VERSION "HNNBNNNYNNNNNNNNNNNNNNNNNNNNNNNNNNNNNNNNNN/4/%%%/4/'%**4NNN///"

NS_ :

BS_:

BU_: AAG BCM1 BCM2 ELV Gateway HDSG IEZS MFG MSBBR SAD SAD2 Schwerpanzer_Zusatz SitzMem_BFS SitzMem_FS SitzMem_HBFS SitzMem_HFS SitzMem_SR3 SpoilerSG TSG_BFS TSG_FS VSG VTS DK_Dummy

BO_ 262 ESP_05: 8 Gateway
 SG_ ESP_05_CRC : 0|8@1+ (1,0) [0|255] ""  BCM2
 SG_ ESP_05_BZ : 8|4@1+ (1,0) [0|15] ""  BCM2
 SG_ ESP_QBit_Bremsdruck : 12|1@1+ (1,0) [0|1] "" Vector__XXX
 SG_ ESP_QBit_Fahrer_bremst : 13|1@1+ (1,0) [0|1] "" Vector__XXX
 SG_ ESP_Schwelle_Unterdruck : 14|2@1+ (1,0) [0|3] "" Vector__XXX
 SG_ ESP_Bremsdruck : 16|10@1+ (0.3,-30) [-30|276.6] "Unit_Bar" Vector__XXX
 SG_ ESP_Fahrer_bremst : 26|1@1+ (1,0) [0|1] "" Vector__XXX
 SG_ ESP_Lenkeingriff_ADS : 28|1@1+ (1,0) [0|1] "" Vector__XXX
 SG_ ECD_Fehler : 32|1@1+ (1,0) [0|1] "" Vector__XXX
 SG_ ECD_nicht_verfuegbar : 33|1@1+ (1,0) [0|1] "" Vector__XXX
 SG_ ESP_Status_Bremsentemp : 34|1@1+ (1,0) [0|1] "" Vector__XXX
 SG_ ESP_Autohold_Standby : 35|1@1+ (1,0) [0|1] "" Vector__XXX
 SG_ ESP_HDC_Standby : 36|1@1+ (1,0) [0|1] "" Vector__XXX
 SG_ ESP_HBA_aktiv : 37|1@1+ (1,0) [0|1] "" Vector__XXX
 SG_ ESP_Prefill_ausgeloest : 38|1@1+ (1,0) [0|1] "" Vector__XXX
 SG_ ESP_Rueckwaertsfahrt_erkannt : 39|1@1+ (1,0) [0|1] "" Vector__XXX
 SG_ ESP_Status_Anfahrhilfe : 40|1@1+ (1,0) [0|1] "" Vector__XXX
 SG_ ESP_HDC_aktiv : 41|1@1+ (1,0) [0|1] "" Vector__XXX
 SG_ ESP_StartStopp_Info : 42|2@1+ (1,0) [0|3] "" Vector__XXX
 SG_ ESP_Eingr_HL : 44|1@1+ (1,0) [0|1] "" Vector__XXX
 SG_ ESP_Eingr_HR : 45|1@1+ (1,0) [0|1] "" Vector__XXX
 SG_ ESP_Eingr_VL : 46|1@1+ (1,0) [0|1] "" Vector__XXX
 SG_ ESP_Eingr_VR : 47|1@1+ (1,0) [0|1] "" Vector__XXX
 SG_ ESP_BKV_Unterdruck : 48|8@1+ (4,0) [4|1012] "Unit_MilliBar" Vector__XXX
 SG_ ESP_Autohold_aktiv : 56|1@1+ (1,0) [0|1] "" Vector__XXX
 SG_ ESP_FStatus_Anfahrhilfe : 57|1@1+ (1,0) [0|1] "" Vector__XXX
 SG_ ESP_Verz_EPB_aktiv : 58|1@1+ (1,0) [0|1] "" Vector__XXX
 SG_ ESC_Bremslicht : 59|1@1+ (1,0) [0|1] ""  AAG,BCM2,MSBBR
 SG_ ESP_Verzoeg_EPB_verf : 60|1@1+ (1,0) [0|1] "" Vector__XXX
 SG_ ESP_Status_Bremsdruck : 61|1@1+ (1,0) [0|1] "" Vector__XXX
 SG_ ESP_Anforderung_EPB : 62|2@1+ (1,0) [0|3] "" Vector__XXX

BO_ 914 ESP_07: 8 Gateway
 SG_ ESP_07_CRC : 0|8@1+ (1,0) [0|255] "" Vector__XXX
 SG_ ESP_07_BZ : 8|4@1+ (1,0) [0|15] "" Vector__XXX
 SG_ ESP_ACC_LDE : 12|1@1+ (1,0) [0|1] "" Vector__XXX
 SG_ ESP_Allrad_Antrieb : 13|1@1+ (1,0) [0|1] "" Vector__XXX
 SG_ ESP_Codierung_ADS : 14|2@1+ (1,0) [0|3] ""  BCM1
 SG_ ESP_RTA_HL : 16|8@1+ (0.048828125,-6.20117) [-6.20117|6.152345625] "Unit_PerCent" Vector__XXX
 SG_ ESP_RTA_HR : 24|8@1+ (0.048828125,-6.20117) [-6.20117|6.152345625] "Unit_PerCent" Vector__XXX
 SG_ ESP_RTA_VR : 32|8@1+ (0.048828125,-6.20117) [-6.20117|6.152345625] "Unit_PerCent" Vector__XXX
 SG_ OBD_Fehler_Radsensor_HL : 40|4@1+ (1,0) [0|15] "" Vector__XXX
 SG_ OBD_Fehler_Radsensor_HR : 44|4@1+ (1,0) [0|15] "" Vector__XXX
 SG_ OBD_Fehler_Radsensor_VL : 48|4@1+ (1,0) [0|15] "" Vector__XXX
 SG_ OBD_Fehler_Radsensor_VR : 52|4@1+ (1,0) [0|15] "" Vector__XXX
 SG_ ESP_Qualifizierung_Antriebsart : 56|1@1+ (1,0) [0|1] "" Vector__XXX
 SG_ ESP_Offroad_Modus : 57|1@1+ (1,0) [0|1] "" Vector__XXX
 SG_ ESP_MKB_ausloesbar : 58|1@1+ (1,0) [0|1] "" Vector__XXX
 SG_ ESP_Stat_FallBack_eBKV : 59|1@1+ (1,0) [0|1] "" Vector__XXX
 SG_ ESP_CM_Variante : 60|1@1+ (1,0) [0|1] "" Vector__XXX
 SG_ ESP_OBD_Status : 61|1@1+ (1,0) [0|1] "" Vector__XXX
 SG_ ESP_Rollenmodus_Deaktivieren : 62|1@1+ (1,0) [0|1] ""  BCM2
 SG_ ESP_nachtr_Stopp_Anf : 63|1@1+ (1,0) [0|1] "" Vector__XXX

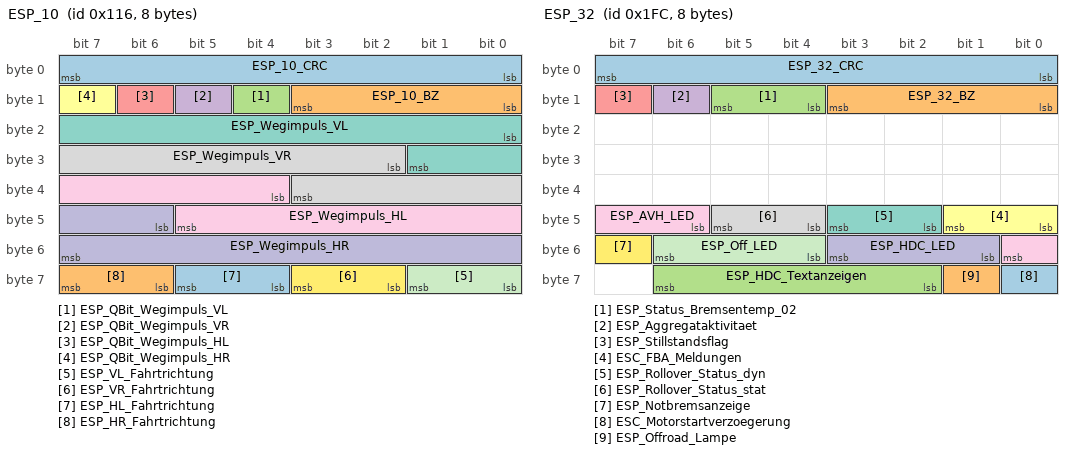
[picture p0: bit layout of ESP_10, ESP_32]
BO_ 278 ESP_10: 8 Gateway
 SG_ ESP_10_CRC : 0|8@1+ (1,0) [0|255] ""  BCM1,ELV
 SG_ ESP_10_BZ : 8|4@1+ (1,0) [0|15] ""  BCM1,ELV
 SG_ ESP_QBit_Wegimpuls_VL : 12|1@1+ (1,0) [0|1] ""  BCM1,ELV
 SG_ ESP_QBit_Wegimpuls_VR : 13|1@1+ (1,0) [0|1] ""  BCM1,ELV
 SG_ ESP_QBit_Wegimpuls_HL : 14|1@1+ (1,0) [0|1] ""  BCM1,ELV
 SG_ ESP_QBit_Wegimpuls_HR : 15|1@1+ (1,0) [0|1] ""  BCM1,ELV
 SG_ ESP_Wegimpuls_VL : 16|10@1+ (1,0) [0|1000] ""  BCM1,ELV
 SG_ ESP_Wegimpuls_VR : 26|10@1+ (1,0) [0|1000] ""  BCM1,ELV
 SG_ ESP_Wegimpuls_HL : 36|10@1+ (1,0) [0|1000] ""  BCM1,ELV
 SG_ ESP_Wegimpuls_HR : 46|10@1+ (1,0) [0|1000] ""  BCM1,ELV
 SG_ ESP_VL_Fahrtrichtung : 56|2@1+ (1,0) [0|3] ""  BCM1
 SG_ ESP_VR_Fahrtrichtung : 58|2@1+ (1,0) [0|3] ""  BCM1
 SG_ ESP_HL_Fahrtrichtung : 60|2@1+ (1,0) [0|3] ""  BCM1
 SG_ ESP_HR_Fahrtrichtung : 62|2@1+ (1,0) [0|3] ""  BCM1

BO_ 418 ESP_15: 8 Gateway
 SG_ ESP_15_CRC : 0|8@1+ (1,0) [0|255] "" Vector__XXX
 SG_ ESP_15_BZ : 8|4@1+ (1,0) [0|15] "" Vector__XXX
 SG_ HMS_P_beibehalten_GE : 12|2@1+ (1,0) [0|3] "" Vector__XXX
 SG_ HMS_Konsistenz_GE : 14|1@1+ (1,0) [0|1] "" Vector__XXX
 SG_ HMS_Konsistenz_IPA : 15|1@1+ (1,0) [0|1] "" Vector__XXX
 SG_ HMS_Konsistenz_EBKV : 16|1@1+ (1,0) [0|1] "" Vector__XXX
 SG_ HMS_Konsistenz_RCTA : 17|1@1+ (1,0) [0|1] "" Vector__XXX
 SG_ HMS_Konsistenz_STA : 18|1@1+ (1,0) [0|1] "" Vector__XXX
 SG_ HMS_Konsistenz_MO : 19|1@1+ (1,0) [0|1] "" Vector__XXX
 SG_ HMS_halten_nicht_verfuegbar : 20|1@1+ (1,0) [0|1] "" Vector__XXX
 SG_ HMS_parken_nicht_verfuegbar : 32|1@1+ (1,0) [0|1] "" Vector__XXX
 SG_ HMS_Anforderung_GE : 33|3@1+ (1,0) [0|7] "" Vector__XXX
 SG_ HMS_Systemstatus : 36|4@1+ (1,0) [0|15] ""  BCM1
 SG_ HMS_Stillstand : 40|3@1+ (1,0) [0|7] ""  BCM1
 SG_ HMS_aktives_System : 43|5@1+ (1,0) [0|31] ""  BCM1
 SG_ HMS_Konsistenz_HVLM : 48|1@1+ (1,0) [0|1] "" Vector__XXX
 SG_ HMS_Konsistenz_ACC : 49|1@1+ (1,0) [0|1] "" Vector__XXX
 SG_ HMS_Fehlerstatus : 50|3@1+ (1,0) [0|7] "" Vector__XXX
 SG_ ESP_Index_Haltemoment : 53|1@1+ (1,0) [0|1] "" Vector__XXX
 SG_ ESP_Haltemoment : 54|10@1+ (10,0) [0|10210] "Unit_NewtoMeter" Vector__XXX

BO_ 1629 ESP_20: 8 Gateway
 SG_ ESP_20_CRC : 0|8@1+ (1,0) [0|255] "" Vector__XXX
 SG_ ESP_20_BZ : 8|4@1+ (1,0) [0|15] "" Vector__XXX
 SG_ BR_Systemart : 12|2@1+ (1,0) [0|3] "" Vector__XXX
 SG_ ESP_SpannungsAnf_02 : 14|2@1+ (1,0) [0|3] "" Vector__XXX
 SG_ ESP_Zaehnezahl : 16|8@1+ (1,0) [0|255] ""  BCM2
 SG_ ESP_Charisma_FahrPr : 24|4@1+ (1,0) [0|15] "" Vector__XXX
 SG_ ESP_Charisma_Status : 28|2@1+ (1,0) [0|3] "" Vector__XXX
 SG_ ESP_Wiederstart_Anz_01 : 30|1@1+ (1,0) [0|1] "" Vector__XXX
 SG_ ESP_Wiederstart_Anz_02 : 31|1@1+ (1,0) [0|1] "" Vector__XXX
 SG_ ESP_Wiederstart_Anz_03 : 32|1@1+ (1,0) [0|1] "" Vector__XXX
 SG_ ESP_Wiederstart_Anz_04 : 33|1@1+ (1,0) [0|1] "" Vector__XXX
 SG_ ESP_Stoppverbot_Anz_01 : 34|1@1+ (1,0) [0|1] "" Vector__XXX
 SG_ ESP_Stoppverbot_Anz_02 : 35|1@1+ (1,0) [0|1] "" Vector__XXX
 SG_ ESP_Stoppverbot_Anz_03 : 36|1@1+ (1,0) [0|1] "" Vector__XXX
 SG_ ESP_Stoppverbot_Anz_04 : 37|1@1+ (1,0) [0|1] "" Vector__XXX
 SG_ ESP_Stoppverbot_Anz_05 : 38|1@1+ (1,0) [0|1] "" Vector__XXX
 SG_ ESP_Stoppverbot_Anz_06 : 39|1@1+ (1,0) [0|1] "" Vector__XXX
 SG_ ESP_Stoppverbot_Anz_07 : 40|1@1+ (1,0) [0|1] "" Vector__XXX
 SG_ ESP_Stoppverbot_Anz_Std : 41|1@1+ (1,0) [0|1] "" Vector__XXX
 SG_ ESP_Dachrelingsensor : 42|2@1+ (1,0) [0|3] "" Vector__XXX
 SG_ ESP_Stoppverbot_Anz_08 : 44|1@1+ (1,0) [0|1] "" Vector__XXX
 SG_ HDC_Charisma_FahrPr : 45|4@1+ (1,0) [0|15] "" Vector__XXX
 SG_ HDC_Charisma_Status : 49|2@1+ (1,0) [0|3] "" Vector__XXX
 SG_ BR_QBit_Reifenumfang : 51|1@1+ (1,0) [0|1] "" Vector__XXX
 SG_ BR_Reifenumfang : 52|12@1+ (1,0) [0|4095] "Unit_MilliMeter" Vector__XXX

BO_ 253 ESP_21: 8 Gateway
 SG_ ESP_21_CRC : 0|8@1+ (1,0) [0|255] ""  AAG,BCM1,BCM2,ELV,IEZS,MSBBR,SitzMem_BFS,SitzMem_FS,SitzMem_HBFS,SitzMem_HFS,SitzMem_SR3,SpoilerSG
 SG_ ESP_21_BZ : 8|4@1+ (1,0) [0|15] ""  AAG,BCM1,BCM2,ELV,IEZS,MSBBR,SitzMem_BFS,SitzMem_FS,SitzMem_HBFS,SitzMem_HFS,SitzMem_SR3,SpoilerSG
 SG_ BR_Eingriffsmoment : 12|10@1+ (1,-509) [-509|509] ""  BCM1
 SG_ ESP_PLA_Bremseingriff : 22|1@1+ (1,0) [0|1] ""  BCM1
 SG_ ESP_Diagnose : 23|1@1+ (1,0) [0|1] "" Vector__XXX
 SG_ ESC_v_Signal_Qualifier_High_Low : 24|3@1+ (1,0) [0|7] ""  IEZS,SpoilerSG
 SG_ ESP_Vorsteuerung : 28|1@1+ (1,0) [0|1] ""  BCM1
 SG_ OBD_Schlechtweg : 30|1@1+ (1,0) [0|1] "" Vector__XXX
 SG_ OBD_QBit_Schlechtweg : 31|1@1+ (1,0) [0|1] "" Vector__XXX
 SG_ ESP_v_Signal : 32|16@1+ (0.01,0) [0|655.32] "Unit_KiloMeterPerHour"  AAG,BCM1,BCM2,ELV,HDSG,MFG,MSBBR,SAD,SAD2,SitzMem_BFS,SitzMem_FS,SitzMem_HBFS,SitzMem_HFS,SitzMem_SR3,SpoilerSG,TSG_BFS,TSG_FS,VSG,VTS
 SG_ ASR_Tastung_passiv : 48|1@1+ (1,0) [0|1] ""  BCM1
 SG_ ESP_Tastung_passiv : 49|1@1+ (1,0) [0|1] ""  BCM1
 SG_ ESP_Systemstatus : 50|1@1+ (1,0) [0|1] ""  BCM1
 SG_ ASR_Schalteingriff : 51|2@1+ (1,0) [0|3] ""  BCM1
 SG_ ESP_Haltebestaetigung : 53|1@1+ (1,0) [0|1] ""  BCM1
 SG_ ESP_MKB_Abbruch_Geschw : 54|1@1+ (1,0) [0|1] "" Vector__XXX
 SG_ ESP_QBit_v_Signal : 55|1@1+ (1,0) [0|1] ""  BCM1,BCM2,ELV,SitzMem_BFS,SitzMem_FS,SitzMem_SR3,SpoilerSG
 SG_ ABS_Bremsung : 56|1@1+ (1,0) [0|1] ""  BCM1,MSBBR
 SG_ ASR_Anf : 57|1@1+ (1,0) [0|1] ""  BCM1
 SG_ MSR_Anf : 58|1@1+ (1,0) [0|1] ""  BCM1
 SG_ EBV_Eingriff : 59|1@1+ (1,0) [0|1] ""  BCM1
 SG_ EDS_Eingriff : 60|1@1+ (1,0) [0|1] ""  BCM1
 SG_ ESP_Eingriff : 61|1@1+ (1,0) [0|1] ""  BCM1
 SG_ ESP_ASP : 62|1@1+ (1,0) [0|1] ""  BCM1

BO_ 795 ESP_24: 8 Gateway
 SG_ ESP_24_CRC : 0|8@1+ (1,0) [0|255] "" Vector__XXX
 SG_ ESP_24_BZ : 8|4@1+ (1,0) [0|15] "" Vector__XXX
 SG_ ESP_Lampe : 12|1@1+ (1,0) [0|1] "" Vector__XXX
 SG_ ABS_Lampe : 13|1@1+ (1,0) [0|1] "" Vector__XXX
 SG_ BK_Lampe_02 : 14|2@1+ (1,0) [0|3] ""  VTS
 SG_ TC_Lampe : 16|1@1+ (1,0) [0|1] "" Vector__XXX
 SG_ ESP_m_Raddrehz : 17|15@1+ (0.002,0) [0|65.278] "Unit_Hertz" Vector__XXX
 SG_ ESP_Textanzeigen_03 : 32|5@1+ (1,0) [0|31] ""  VTS
 SG_ ESP_Meldungen : 37|3@1+ (1,0) [0|7] "" Vector__XXX
 SG_ ESP_Wegimp_VA : 40|11@1+ (1,0) [0|2047] "" Vector__XXX
 SG_ ESP_Fehlerstatus_Wegimp : 51|1@1+ (1,0) [0|1] "" Vector__XXX
 SG_ ESP_Wegimp_Ueberlauf : 52|1@1+ (1,0) [0|1] "" Vector__XXX
 SG_ ESP_QBit_Wegimp_VA : 53|1@1+ (1,0) [0|1] "" Vector__XXX
 SG_ ESP_HDC_FktLampe : 54|1@1+ (1,0) [0|1] "" Vector__XXX
 SG_ ESP_Off_Lampe : 55|1@1+ (1,0) [0|1] "" Vector__XXX
 SG_ ESP_HDC_Regelgeschw : 56|7@1+ (0.32,0) [0.32|39.68] "Unit_KiloMeterPerHour" Vector__XXX
 SG_ ESP_BKV_Warnung : 63|1@1+ (1,0) [0|1] ""  VTS

BO_ 508 ESP_32: 8 Gateway
 SG_ ESP_32_CRC : 0|8@1+ (1,0) [0|255] "" Vector__XXX
 SG_ ESP_32_BZ : 8|4@1+ (1,0) [0|15] "" Vector__XXX
 SG_ ESP_Status_Bremsentemp_02 : 12|2@1+ (1,0) [0|3] "" Vector__XXX
 SG_ ESP_Aggregataktivitaet : 14|1@1+ (1,0) [0|1] "" Vector__XXX
 SG_ ESP_Stillstandsflag : 15|1@1+ (1,0) [0|1] ""  BCM1,BCM2
 SG_ ESC_FBA_Meldungen : 40|2@1+ (1,0) [0|3] "" Vector__XXX
 SG_ ESP_Rollover_Status_dyn : 42|2@1+ (1,0) [0|3] "" Vector__XXX
 SG_ ESP_Rollover_Status_stat : 44|2@1+ (1,0) [0|3] "" Vector__XXX
 SG_ ESP_AVH_LED : 46|3@1+ (1,0) [0|7] ""  BCM1
 SG_ ESP_HDC_LED : 49|3@1+ (1,0) [0|7] ""  BCM1
 SG_ ESP_Off_LED : 52|3@1+ (1,0) [0|7] ""  BCM1,VTS
 SG_ ESP_Notbremsanzeige : 55|1@1+ (1,0) [0|1] ""  SAD2,BCM2,SAD
 SG_ ESC_Motorstartverzoegerung : 56|1@1+ (1,0) [0|1] "" Vector__XXX
 SG_ ESP_Offroad_Lampe : 57|1@1+ (1,0) [0|1] "" Vector__XXX
 SG_ ESP_HDC_Textanzeigen : 58|5@1+ (1,0) [0|31] "" Vector__XXX

BO_ 427 ESP_33: 8 Gateway
 SG_ ESP_33_CRC : 0|8@1+ (1,0) [0|255] "" Vector__XXX
 SG_ ESP_33_BZ : 8|4@1+ (1,0) [0|15] "" Vector__XXX
 SG_ ESC_AHW_aktiv : 12|3@1+ (1,0) [0|7] ""  BCM1
 SG_ ESC_AHW_nicht_verfuegbar : 15|1@1+ (1,0) [0|1] ""  BCM1
 SG_ ESC_ANB_CM_aktiv : 16|2@1+ (1,0) [0|3] "" Vector__XXX
 SG_ ESC_ANB_CM_nicht_verfuegbar : 18|1@1+ (1,0) [0|1] "" Vector__XXX
 SG_ ESC_Warnruck_aktiv : 19|4@1+ (1,0) [0|15] "" Vector__XXX
 SG_ ESC_Warnruck_nicht_verfuegbar : 23|1@1+ (1,0) [0|1] "" Vector__XXX
 SG_ ESC_Prefill_aktiv : 24|1@1+ (1,0) [0|1] "" Vector__XXX
 SG_ ESC_Prefill_nicht_verfuegbar : 25|1@1+ (1,0) [0|1] "" Vector__XXX
 SG_ ESC_HBA_aktiv : 26|1@1+ (1,0) [0|1] "" Vector__XXX
 SG_ ESC_HBA_nicht_verfuegbar : 27|1@1+ (1,0) [0|1] "" Vector__XXX
 SG_ ESC_TSK_SRBM_Anf : 28|1@1+ (1,0) [0|1] "" Vector__XXX
 SG_ ESC_TSK_SRBM_nicht_verfuegbar : 29|1@1+ (1,0) [0|1] "" Vector__XXX
 SG_ ESC_Verz_Reg_aktiv : 30|4@1+ (1,0) [0|15] ""  BCM1
 SG_ ESC_Verz_Reg_nicht_verfuegbar : 34|1@1+ (1,0) [0|1] ""  BCM1
 SG_ ESC_Verz_Reg_TB_nicht_verfuegbar : 35|1@1+ (1,0) [0|1] "" Vector__XXX
 SG_ ESC_Verz_Reg_ZB_nicht_verfuegbar : 36|1@1+ (1,0) [0|1] ""  BCM1
 SG_ ESC_Bremslicht_unplausibel : 37|1@1+ (1,0) [0|1] "" Vector__XXX
 SG_ ESC_Konsistenz_ACC : 38|1@1+ (1,0) [0|1] "" Vector__XXX
 SG_ ESC_Konsistenz_AWV : 39|1@1+ (1,0) [0|1] "" Vector__XXX
 SG_ ESC_Konsistenz_ARA : 40|1@1+ (1,0) [0|1] ""  BCM1
 SG_ ESC_Konsistenz_IPA : 41|1@1+ (1,0) [0|1] ""  BCM1
 SG_ ESC_Konsistenz_FCW : 42|1@1+ (1,0) [0|1] "" Vector__XXX
 SG_ ESC_Konsistenz_NV : 43|1@1+ (1,0) [0|1] "" Vector__XXX
 SG_ ESC_Konsistenz_RCTA : 44|1@1+ (1,0) [0|1] "" Vector__XXX
 SG_ ESC_Konsistenz_TSK : 45|1@1+ (1,0) [0|1] "" Vector__XXX
 SG_ ESC_Konsistenz_vFGS : 46|1@1+ (1,0) [0|1] "" Vector__XXX
 SG_ ESC_Konsistenz_STA : 47|1@1+ (1,0) [0|1] "" Vector__XXX
 SG_ ESC_Fahrer_Bremsdruck_bestimmend : 48|1@1+ (1,0) [0|1] "" Vector__XXX
 SG_ ESC_Konsistenz_EA : 49|1@1+ (1,0) [0|1] "" Vector__XXX
 SG_ ESC_Konsistenz_BFF : 50|1@1+ (1,0) [0|1] "" Vector__XXX
 SG_ ESC_Konsistenz_MKB : 51|1@1+ (1,0) [0|1] "" Vector__XXX

BO_ 2589283470 ESP_35: 8 Gateway
 SG_ ESC_Kilometer : 0|20@1+ (1,0) [0|1048573] "Unit_KiloMeter"  BCM2
 SG_ ESC_Kilometer_MUX M : 20|1@1+ (1,0) [0|1] ""  BCM2
 SG_ ESC_Signatur_Kilometer_GFA_01 m0 : 23|9@1+ (1,0) [0|511] ""  BCM2
 SG_ ESC_Signatur_Kilometer_IKA_01 m1 : 23|9@1+ (1,0) [0|511] ""  BCM2
 SG_ ESC_Signatur_Kilometer_GFA_02 m0 : 32|32@1+ (1,0) [0|4294967295] ""  BCM2
 SG_ ESC_Signatur_Kilometer_IKA_02 m1 : 32|32@1+ (1,0) [0|4294967295] ""  BCM2

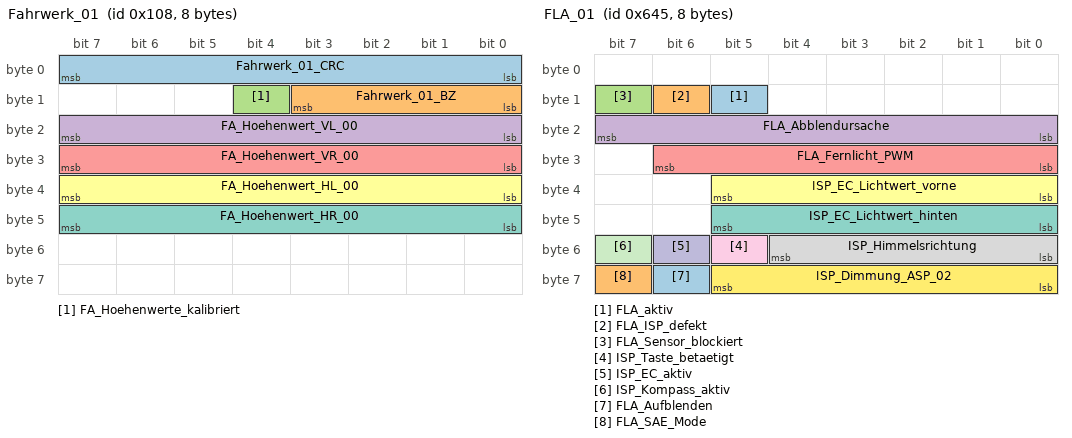
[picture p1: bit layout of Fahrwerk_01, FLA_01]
BO_ 264 Fahrwerk_01: 8 Gateway
 SG_ Fahrwerk_01_CRC : 0|8@1+ (1,0) [0|255] "" Vector__XXX
 SG_ Fahrwerk_01_BZ : 8|4@1+ (1,0) [0|15] "" Vector__XXX
 SG_ FA_Hoehenwerte_kalibriert : 12|1@1+ (1,0) [0|1] ""  BCM1
 SG_ FA_Hoehenwert_VL_00 : 16|8@1+ (1,-127) [-127|126] "Unit_MilliMeter"  BCM1
 SG_ FA_Hoehenwert_VR_00 : 24|8@1+ (1,-127) [-127|126] "Unit_MilliMeter" Vector__XXX
 SG_ FA_Hoehenwert_HL_00 : 32|8@1+ (1,-127) [-127|126] "Unit_MilliMeter"  BCM1
 SG_ FA_Hoehenwert_HR_00 : 40|8@1+ (1,-127) [-127|126] "Unit_MilliMeter" Vector__XXX

BO_ 429 Fahrwerk_06: 8 Gateway
 SG_ Fahrwerk_06_CRC : 0|8@1+ (1,0) [0|255] "" Vector__XXX
 SG_ Fahrwerk_06_BZ : 8|4@1+ (1,0) [0|15] "" Vector__XXX
 SG_ NR_Reglerstatus : 12|4@1+ (1,0) [0|15] ""  BCM1
 SG_ FA_Verstellung_in_Kuerze : 16|1@1+ (1,0) [0|1] "" Vector__XXX
 SG_ FA_Verstellung_aktiv : 17|1@1+ (1,0) [0|1] "" Vector__XXX
 SG_ FA_Kompressor_laeuft_in_Kuerze : 18|1@1+ (1,0) [0|1] "" Vector__XXX
 SG_ FA_Kompressor_laeuft : 19|1@1+ (1,0) [0|1] "" Vector__XXX
 SG_ NR_Anforderung_v_Begrenzung : 20|2@1+ (1,0) [0|3] "" Vector__XXX
 SG_ NR_LED_SGN : 22|1@1+ (1,0) [0|1] ""  BCM1
 SG_ NR_LED_TN : 23|1@1+ (1,0) [0|1] ""  BCM1
 SG_ NR_LED_BN : 24|1@1+ (1,0) [0|1] ""  BCM1
 SG_ FA_Absenkung_Fahrzeug : 25|1@1+ (1,0) [0|1] "" Vector__XXX
 SG_ FA_Anhaengerstatus_intern : 26|3@1+ (1,0) [0|7] "" Vector__XXX
 SG_ FA_Anhebung_Fahrzeug : 29|1@1+ (1,0) [0|1] "" Vector__XXX
 SG_ FA_Druckspeicher_verfuegbar : 30|1@1+ (1,0) [0|1] "" Vector__XXX
 SG_ FA_ESP_Zuschaltung : 32|1@1+ (1,0) [0|1] "" Vector__XXX
 SG_ NR_LED_HN : 33|1@1+ (1,0) [0|1] ""  BCM1
 SG_ FA_Zwischenniveau : 34|1@1+ (1,0) [0|1] "" Vector__XXX
 SG_ FA_Systemstatus : 35|1@1+ (1,0) [0|1] "" Vector__XXX
 SG_ EFP_Soll_FahrPr_HAL : 36|4@1+ (1,0) [0|15] "" Vector__XXX
 SG_ NR_Kompressor_Temp_Zylinderkopf : 48|8@1+ (1,-40) [-40|213] "Unit_DegreCelsi" Vector__XXX
 SG_ FA_Signal_Drucksensor : 56|8@1+ (0.1,0) [0|25.3] "Unit_Bar" Vector__XXX

BO_ 1605 FLA_01: 8 Gateway
 SG_ FLA_aktiv : 13|1@1+ (1,0) [0|1] ""  BCM1
 SG_ FLA_ISP_defekt : 14|1@1+ (1,0) [0|1] ""  BCM1
 SG_ FLA_Sensor_blockiert : 15|1@1+ (1,0) [0|1] ""  BCM1
 SG_ FLA_Abblendursache : 16|8@1+ (1,0) [0|255] "" Vector__XXX
 SG_ FLA_Fernlicht_PWM : 24|7@1+ (1,0) [0|100] "Unit_PerCent"  BCM1
 SG_ ISP_EC_Lichtwert_vorne : 32|6@1+ (1,0) [0|61] "Unit_None" Vector__XXX
 SG_ ISP_EC_Lichtwert_hinten : 40|6@1+ (1,0) [0|61] "Unit_None" Vector__XXX
 SG_ ISP_Himmelsrichtung : 48|5@1+ (12,0) [0|348] "Unit_DegreOfArc" Vector__XXX
 SG_ ISP_Taste_betaetigt : 53|1@1+ (1,0) [0|1] "" Vector__XXX
 SG_ ISP_EC_aktiv : 54|1@1+ (1,0) [0|1] "" Vector__XXX
 SG_ ISP_Kompass_aktiv : 55|1@1+ (1,0) [0|1] "" Vector__XXX
 SG_ ISP_Dimmung_ASP_02 : 56|6@1+ (0.0226,0) [0|1.4012] "Unit_Volt"  TSG_BFS,TSG_FS
 SG_ FLA_Aufblenden : 62|1@1+ (1,0) [0|1] ""  BCM1
 SG_ FLA_SAE_Mode : 63|1@1+ (1,0) [0|1] "" Vector__XXX

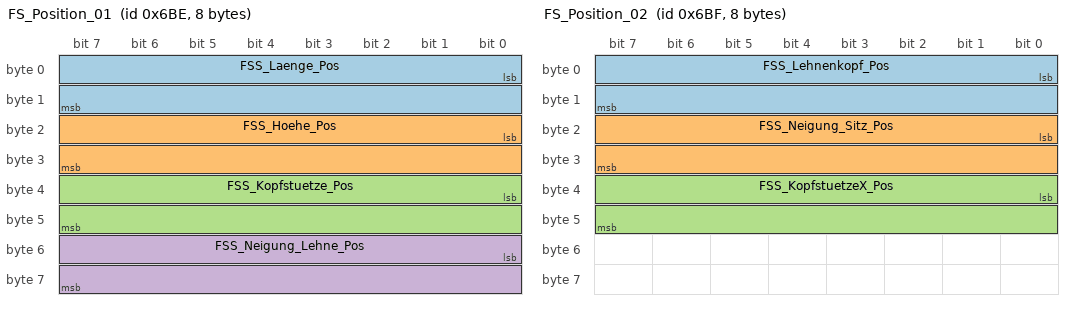
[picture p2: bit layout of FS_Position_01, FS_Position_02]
BO_ 1726 FS_Position_01: 8 SitzMem_FS
 SG_ FSS_Laenge_Pos : 0|16@1+ (1,0) [0|65535] ""  SitzMem_BFS
 SG_ FSS_Hoehe_Pos : 16|16@1+ (1,0) [0|65535] ""  SitzMem_BFS
 SG_ FSS_Kopfstuetze_Pos : 32|16@1+ (1,0) [0|65535] ""  SitzMem_BFS
 SG_ FSS_Neigung_Lehne_Pos : 48|16@1+ (1,0) [0|65535] ""  SitzMem_BFS

BO_ 1727 FS_Position_02: 8 SitzMem_FS
 SG_ FSS_Lehnenkopf_Pos : 0|16@1+ (1,0) [0|65535] ""  SitzMem_BFS
 SG_ FSS_Neigung_Sitz_Pos : 16|16@1+ (1,0) [1|65535] ""  SitzMem_BFS
 SG_ FSS_KopfstuetzeX_Pos : 32|16@1+ (1,0) [1|65535] ""  SitzMem_BFS

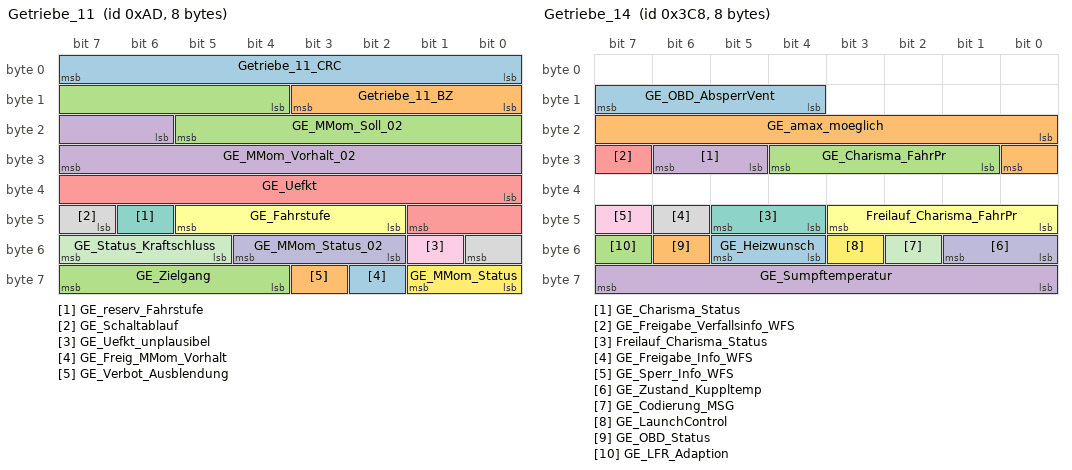
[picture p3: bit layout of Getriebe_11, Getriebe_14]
BO_ 173 Getriebe_11: 8 Gateway
 SG_ Getriebe_11_CRC : 0|8@1+ (1,0) [0|255] "" Vector__XXX
 SG_ Getriebe_11_BZ : 8|4@1+ (1,0) [0|15] "" Vector__XXX
 SG_ GE_MMom_Soll_02 : 12|10@1+ (1,-509) [-509|509] "" Vector__XXX
 SG_ GE_MMom_Vorhalt_02 : 22|10@1+ (1,-509) [-509|509] "" Vector__XXX
 SG_ GE_Uefkt : 32|10@1+ (0.1,0) [0|102.2] "" Vector__XXX
 SG_ GE_Fahrstufe : 42|4@1+ (1,0) [0|15] ""  BCM1,BCM2,ELV,MFG
 SG_ GE_reserv_Fahrstufe : 46|1@1+ (1,0) [0|1] "" Vector__XXX
 SG_ GE_Schaltablauf : 47|2@1+ (1,0) [0|3] "" Vector__XXX
 SG_ GE_Uefkt_unplausibel : 49|1@1+ (1,0) [0|1] "" Vector__XXX
 SG_ GE_MMom_Status_02 : 50|3@1+ (1,0) [0|7] "" Vector__XXX
 SG_ GE_Status_Kraftschluss : 53|3@1+ (1,0) [0|7] "" Vector__XXX
 SG_ GE_MMom_Status : 56|2@1+ (1,0) [0|3] "" Vector__XXX
 SG_ GE_Freig_MMom_Vorhalt : 58|1@1+ (1,0) [0|1] "" Vector__XXX
 SG_ GE_Verbot_Ausblendung : 59|1@1+ (1,0) [0|1] "" Vector__XXX
 SG_ GE_Zielgang : 60|4@1+ (1,0) [0|15] ""  BCM1

BO_ 968 Getriebe_14: 8 Gateway
 SG_ GE_OBD_AbsperrVent : 12|4@1+ (1,0) [0|15] "" Vector__XXX
 SG_ GE_amax_moeglich : 16|9@1+ (0.024,-2.016) [-2.016|10.224] "Unit_MeterPerSeconSquar" Vector__XXX
 SG_ GE_Charisma_FahrPr : 25|4@1+ (1,0) [0|15] "" Vector__XXX
 SG_ GE_Charisma_Status : 29|2@1+ (1,0) [0|3] "" Vector__XXX
 SG_ GE_Freigabe_Verfallsinfo_WFS : 31|1@1+ (1,0) [0|1] ""  BCM2
 SG_ Freilauf_Charisma_FahrPr : 40|4@1+ (1,0) [0|15] "" Vector__XXX
 SG_ Freilauf_Charisma_Status : 44|2@1+ (1,0) [0|3] "" Vector__XXX
 SG_ GE_Freigabe_Info_WFS : 46|1@1+ (1,0) [0|1] ""  BCM2
 SG_ GE_Sperr_Info_WFS : 47|1@1+ (1,0) [0|1] ""  BCM2
 SG_ GE_Zustand_Kuppltemp : 48|2@1+ (1,0) [0|3] "" Vector__XXX
 SG_ GE_Codierung_MSG : 50|1@1+ (1,0) [0|1] "" Vector__XXX
 SG_ GE_LaunchControl : 51|1@1+ (1,0) [0|1] "" Vector__XXX
 SG_ GE_Heizwunsch : 52|2@1+ (1,0) [0|3] "" Vector__XXX
 SG_ GE_OBD_Status : 54|1@1+ (1,0) [0|1] "" Vector__XXX
 SG_ GE_LFR_Adaption : 55|1@1+ (1,0) [0|1] "" Vector__XXX
 SG_ GE_Sumpftemperatur : 56|8@1+ (1,-58) [-58|196] "Unit_DegreCelsi" Vector__XXX

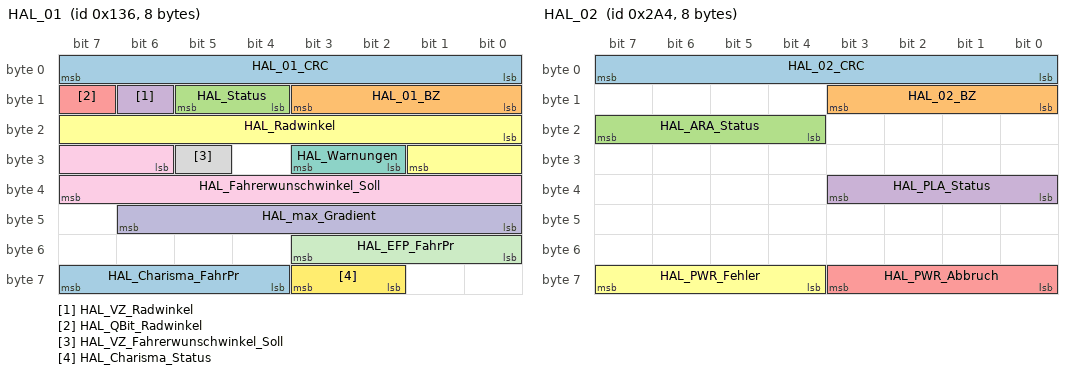
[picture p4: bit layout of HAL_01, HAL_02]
BO_ 310 HAL_01: 8 Gateway
 SG_ HAL_01_CRC : 0|8@1+ (1,0) [0|255] ""  BCM1
 SG_ HAL_01_BZ : 8|4@1+ (1,0) [0|15] ""  BCM1
 SG_ HAL_Status : 12|2@1+ (1,0) [0|3] ""  BCM1
 SG_ HAL_VZ_Radwinkel : 14|1@1+ (1,0) [0|1] ""  BCM1
 SG_ HAL_QBit_Radwinkel : 15|1@1+ (1,0) [0|1] ""  BCM1
 SG_ HAL_Radwinkel : 16|10@1+ (0.01,0) [0|10.19] "Unit_DegreOfArc"  BCM1
 SG_ HAL_Warnungen : 26|2@1+ (1,0) [0|3] "" Vector__XXX
 SG_ HAL_VZ_Fahrerwunschwinkel_Soll : 29|1@1+ (1,0) [0|1] ""  BCM1
 SG_ HAL_Fahrerwunschwinkel_Soll : 30|10@1+ (0.01,0) [0|10.21] "Unit_DegreOfArc"  BCM1
 SG_ HAL_max_Gradient : 40|7@1+ (0.1,0) [0|12.5] "Unit_DegreOfArcPerSecon" Vector__XXX
 SG_ HAL_EFP_FahrPr : 48|4@1+ (1,0) [0|15] "" Vector__XXX
 SG_ HAL_Charisma_Status : 58|2@1+ (1,0) [0|3] "" Vector__XXX
 SG_ HAL_Charisma_FahrPr : 60|4@1+ (1,0) [0|15] "" Vector__XXX

BO_ 676 HAL_02: 8 Gateway
 SG_ HAL_02_CRC : 0|8@1+ (1,0) [0|255] ""  BCM1
 SG_ HAL_02_BZ : 8|4@1+ (1,0) [0|15] ""  BCM1
 SG_ HAL_ARA_Status : 20|4@1+ (1,0) [0|15] ""  BCM1
 SG_ HAL_PLA_Status : 32|4@1+ (1,0) [0|15] ""  BCM1
 SG_ HAL_PWR_Abbruch : 56|4@1+ (1,0) [0|15] ""  BCM1
 SG_ HAL_PWR_Fehler : 60|4@1+ (1,0) [0|15] ""  BCM1

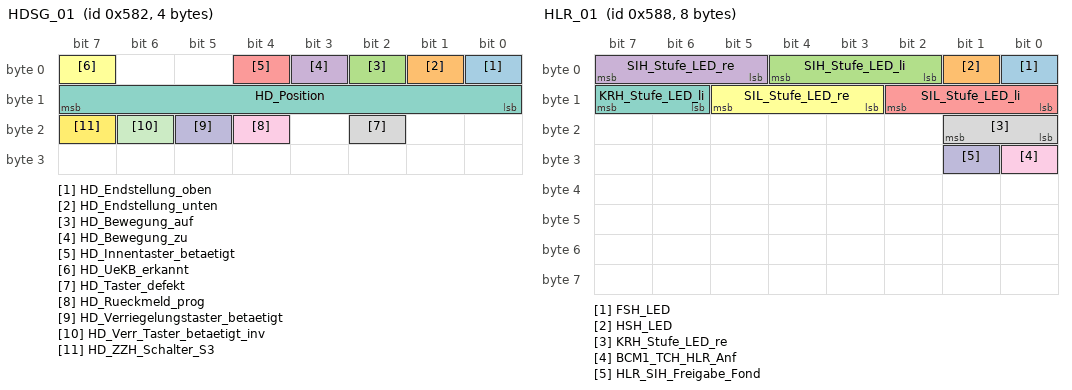
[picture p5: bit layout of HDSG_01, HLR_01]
BO_ 1410 HDSG_01: 4 HDSG
 SG_ HD_Endstellung_oben : 0|1@1+ (1,0) [0|1] ""  Gateway
 SG_ HD_Endstellung_unten : 1|1@1+ (1,0) [0|1] ""  Gateway
 SG_ HD_Bewegung_auf : 2|1@1+ (1,0) [0|1] ""  BCM2,Gateway
 SG_ HD_Bewegung_zu : 3|1@1+ (1,0) [0|1] ""  BCM2,Gateway
 SG_ HD_Innentaster_betaetigt : 4|1@1+ (1,0) [0|1] ""  AAG,Gateway
 SG_ HD_UeKB_erkannt : 7|1@1+ (1,0) [0|1] ""  Gateway
 SG_ HD_Position : 8|8@1+ (1,0) [0|100] "Unit_PerCent"  BCM1,BCM2,Gateway
 SG_ HD_Taster_defekt : 18|1@1+ (1,0) [0|1] ""  Gateway
 SG_ HD_Rueckmeld_prog : 20|1@1+ (1,0) [0|1] ""  BCM2,Gateway
 SG_ HD_Verriegelungstaster_betaetigt : 21|1@1+ (1,0) [0|1] ""  AAG,BCM2,Gateway
 SG_ HD_Verr_Taster_betaetigt_inv : 22|1@1+ (1,0) [0|1] ""  BCM2,Gateway
 SG_ HD_ZZH_Schalter_S3 : 23|1@1+ (1,0) [0|1] ""  BCM2,Gateway

BO_ 1416 HLR_01: 8 BCM1
 SG_ FSH_LED : 0|1@1+ (1,0) [0|1] ""  Gateway
 SG_ HSH_LED : 1|1@1+ (1,0) [0|1] ""  Gateway
 SG_ SIH_Stufe_LED_li : 2|3@1+ (1,0) [0|7] ""  Gateway
 SG_ SIH_Stufe_LED_re : 5|3@1+ (1,0) [0|7] ""  Gateway
 SG_ SIL_Stufe_LED_li : 8|3@1+ (1,0) [0|7] ""  Gateway
 SG_ SIL_Stufe_LED_re : 11|3@1+ (1,0) [0|7] ""  Gateway
 SG_ KRH_Stufe_LED_li : 14|2@1+ (1,0) [0|3] ""  Gateway
 SG_ KRH_Stufe_LED_re : 16|2@1+ (1,0) [0|3] ""  Gateway
 SG_ BCM1_TCH_HLR_Anf : 24|1@1+ (1,0) [0|1] ""  Gateway
 SG_ HLR_SIH_Freigabe_Fond : 25|1@1+ (1,0) [0|1] ""  Gateway

BO_ 1016 HLR_02: 8 Gateway
 SG_ HLR_FlHz_Freigabe_Ruhesitz : 14|2@1+ (1,0) [0|3] ""  BCM1
 SG_ HLR_FlHz_Freigabe_VR : 16|2@1+ (1,0) [0|3] ""  BCM1
 SG_ HLR_FlHz_Freigabe_VL : 18|2@1+ (1,0) [0|3] ""  BCM1
 SG_ HLR_FlHz_Freigabe_HR : 20|2@1+ (1,0) [0|3] ""  BCM1
 SG_ HLR_FlHz_Freigabe_HL : 22|2@1+ (1,0) [0|3] ""  BCM1
 SG_ HLR_TCH_Freigabe : 24|1@1+ (1,0) [0|1] ""  BCM1
 SG_ HLR_SIH_Freigabe_Fond : 25|1@1+ (1,0) [0|1] ""  BCM1
 SG_ HLR_Sp_Heizung_Freigabe_BT : 26|1@1+ (1,0) [0|1] ""  TSG_BFS,TSG_FS
 SG_ HLR_Sp_Heizung_Freigabe_FT : 27|1@1+ (1,0) [0|1] ""  TSG_BFS,TSG_FS
 SG_ HLR_KRH_Freigabe_VL : 28|2@1+ (1,0) [0|3] ""  BCM1
 SG_ HLR_KRH_Freigabe_VR : 30|2@1+ (1,0) [0|3] ""  BCM1
 SG_ HLR_SIH_Freigabe_VL : 32|2@1+ (1,0) [0|3] ""  BCM1
 SG_ HLR_SIH_Freigabe_VR : 34|2@1+ (1,0) [0|3] ""  BCM1
 SG_ HLR_SIH_Freigabe_HL : 36|2@1+ (1,0) [0|3] ""  BCM1
 SG_ HLR_SIH_Freigabe_HR : 38|2@1+ (1,0) [0|3] ""  BCM1
 SG_ HLR_SIL_Freigabe_VL : 40|2@1+ (1,0) [0|3] ""  BCM1
 SG_ HLR_SIL_Freigabe_VR : 42|2@1+ (1,0) [0|3] ""  BCM1
 SG_ HLR_SIL_Freigabe_HL : 44|2@1+ (1,0) [0|3] ""  BCM1
 SG_ HLR_SIL_Freigabe_HR : 46|2@1+ (1,0) [0|3] ""  BCM1
 SG_ HLR_FSH_Freigabe : 48|6@1+ (20,0) [20|1240] "Unit_Watt"  BCM2
 SG_ HLR_HSH_Freigabe : 54|1@1+ (1,0) [0|1] ""  BCM2
 SG_ HLR_LRH_Freigabe : 55|1@1+ (1,0) [0|1] "" Vector__XXX
 SG_ HLR_PTC_linear_Freigabe : 56|6@1+ (50,0) [0|3100] "Unit_Watt" Vector__XXX
 SG_ HLR_PTC_Freigabe : 62|2@1+ (1,0) [0|3] ""  BCM1

BO_ 1412 HSP_01: 6 BCM2
 SG_ HSP_01_CRC : 0|8@1+ (1,0) [0|255] ""  Gateway
 SG_ HSP_01_BZ : 8|4@1+ (1,0) [0|15] ""  Gateway
 SG_ HSP_Taster : 12|1@1+ (1,0) [0|1] ""  Gateway
 SG_ HSP_Status_LED : 13|1@1+ (1,0) [0|1] ""  Gateway
 SG_ HSP_Warnung_LED : 14|1@1+ (1,0) [0|1] ""  Gateway
 SG_ HSP_Warnung_Ton : 15|1@1+ (1,0) [0|1] ""  Gateway
 SG_ HSP_Warnung_Text : 16|1@1+ (1,0) [0|1] ""  Gateway
 SG_ HSP_Endlage_eingefahren : 17|1@1+ (1,0) [0|1] ""  Gateway,VTS
 SG_ HSP_Endlage_ausgefahren : 18|1@1+ (1,0) [0|1] ""  Gateway,VTS
 SG_ HSP_Unterspannung : 19|1@1+ (1,0) [0|1] ""  Gateway
 SG_ HSP_Ueberspannung : 20|1@1+ (1,0) [0|1] ""  Gateway
 SG_ HSP_Lokalaktiv : 21|1@1+ (1,0) [0|1] ""  Gateway
 SG_ HSP_ResponseError : 22|1@1+ (1,0) [0|1] ""  Gateway
 SG_ HSP_ErrorGueltigkeit_1 : 23|1@1+ (1,0) [0|1] ""  Gateway
 SG_ HSP_ErrorGueltigkeit_2 : 24|1@1+ (1,0) [0|1] ""  Gateway
 SG_ HSP_def : 25|1@1+ (1,0) [0|1] ""  Gateway
 SG_ HSP_Motor_def : 26|1@1+ (1,0) [0|1] ""  Gateway
 SG_ HSP_Spoiler_Error : 27|1@1+ (1,0) [0|1] ""  Gateway
 SG_ HSP_Taster_Error : 28|1@1+ (1,0) [0|1] ""  Gateway
 SG_ HSP_LED_Error : 29|1@1+ (1,0) [0|1] ""  Gateway
 SG_ HSP_Spielschutz : 30|1@1+ (1,0) [0|1] ""  Gateway
 SG_ HSP_Charisma_FahrPr : 32|4@1+ (1,0) [0|15] ""  Gateway
 SG_ HSP_Charisma_Status : 36|2@1+ (1,0) [0|3] ""  Gateway
 SG_ HSP_Adressegment : 41|3@1+ (1,0) [0|7] "Unit_None"  Gateway
 SG_ HSP_AdressInhalt : 44|4@1+ (1,0) [0|15] "Unit_None"  Gateway

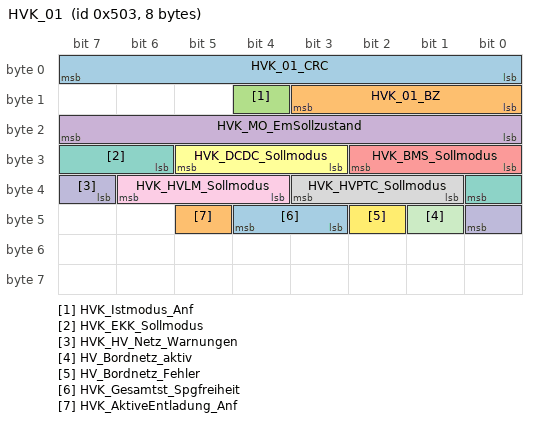
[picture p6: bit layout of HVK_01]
BO_ 1283 HVK_01: 8 Gateway
 SG_ HVK_01_CRC : 0|8@1+ (1,0) [0|255] "" Vector__XXX
 SG_ HVK_01_BZ : 8|4@1+ (1,0) [0|15] "" Vector__XXX
 SG_ HVK_Istmodus_Anf : 12|1@1+ (1,0) [0|1] "" Vector__XXX
 SG_ HVK_MO_EmSollzustand : 16|8@1+ (1,0) [0|255] "" Vector__XXX
 SG_ HVK_BMS_Sollmodus : 24|3@1+ (1,0) [0|7] "" Vector__XXX
 SG_ HVK_DCDC_Sollmodus : 27|3@1+ (1,0) [0|7] "" Vector__XXX
 SG_ HVK_EKK_Sollmodus : 30|3@1+ (1,0) [0|7] "" Vector__XXX
 SG_ HVK_HVPTC_Sollmodus : 33|3@1+ (1,0) [0|7] "" Vector__XXX
 SG_ HVK_HVLM_Sollmodus : 36|3@1+ (1,0) [0|7] "" Vector__XXX
 SG_ HVK_HV_Netz_Warnungen : 39|2@1+ (1,0) [0|3] "" Vector__XXX
 SG_ HV_Bordnetz_aktiv : 41|1@1+ (1,0) [0|1] "" Vector__XXX
 SG_ HV_Bordnetz_Fehler : 42|1@1+ (1,0) [0|1] ""  BCM2
 SG_ HVK_Gesamtst_Spgfreiheit : 43|2@1+ (1,0) [0|3] "" Vector__XXX
 SG_ HVK_AktiveEntladung_Anf : 45|1@1+ (1,0) [0|1] "" Vector__XXX

CM_ SG_ 262 ESP_05_CRC "Für MLB:
'Berechnung siehe Lastenheft 'Kommunikationsabsicherung für FlexRay und CAN''

Ab MQB und MLBevo:
'Berechnung siehe Lastenheft 'End-to-End Kommunikationsabsicherung''

Endwerte siehe Begleitdokument 'S-PDU Kennungsfolgen'";
CM_ SG_ 262 ESP_QBit_Bremsdruck "QBit des Bremsdrucks. Gesetzt bei Ersatzwert, Init oder Fehler.";
CM_ SG_ 262 ESP_QBit_Fahrer_bremst "Gültigkeit der Bremsdruckschwelleninformation des Signals ESP_Fahrer_bremst vom ESP SG
0x1 = Druckschwelleninformation kann noch nicht oder aufgrund eines Fehlers nicht ausgegeben werden
";
CM_ SG_ 262 ESP_Schwelle_Unterdruck "Verwendung im MQB für HBV-Projekte oder wenn für St/St ein Unterdrucksensor verbaut ist";
CM_ SG_ 262 ESP_Bremsdruck "Rohwert des Bremsdrucks [Vordruck durch Fahrervorgabe (Pvor). Bei aktivem Druckaufbau (Stabilisierungseingriffe) kein Pvor]
";
CM_ SG_ 262 ESP_Fahrer_bremst "Bit wird gesetzt beim Überschreiten der Bremsdruckschwelle

Weiterführende Informationen im Lastenheft spezifiziert und in der entsprechenden Fachabteilung zu erfragen.
";
CM_ SG_ 262 ESP_Lenkeingriff_ADS "Im Falle eines fahrzeugstabilisierenden Lenkeingriffs des ADS-Systems soll ACC/GRA deaktiviert werden.

Im MQB wird dieses Signal nicht unterstützt!";
CM_ SG_ 262 ECD_Fehler "ESP kann die Verzögerungsregelung/Bremsenregelung aufgrund eines internen Fehlers nicht ausführen, mit Fehlereintrag im ESP.
";
CM_ SG_ 262 ECD_nicht_verfuegbar "ESP kann die Verzögerungsregelung/Bremsenregelung temporär nicht ausführen (z.B. Netzwerkmanagement-Betriebe - KL15 Aus; v<18km/h; ESP in Diagnose, ...), ohne Fehlereintrag im ESP.

";
CM_ SG_ 262 ESP_Status_Bremsentemp "ECD-Bremsscheibentemperaturmodell. Rückmeldung für Sender einer ECD Verzögerungsanforderung, ohne Fehlereintrag im ESP";
CM_ SG_ 262 ESP_Autohold_Standby "Rückmeldung an EPB, dass der Fahrer die Funktion Autohold mindestens einmal angefordert hat. Im Fall eines ESP-Ausfalles oder einer Übernahmeaufforderung erfolgt die EPB-Zuschaltung nur nach Setzen dieses Bits. Bit wird gesetzt nach Betätigung des Autohol";
CM_ SG_ 262 ESP_HDC_Standby "Verwendung/Bedienung im MQB und AU57x Allroad:
Flag wird vom ESP gesetzt, wenn über den HDC-Taster die HDC-Funktion eingeschalten wurde";
CM_ SG_ 262 ESP_HBA_aktiv "Verwendung/Bedienung ab D4
Signal gibt an, ob der hydraulische Bremsassistent im Regler aktiviert wurde

Im MQB wird das Signal nicht unterstützt!

";
CM_ SG_ 262 ESP_Prefill_ausgeloest "MLB: Verwendung/Bedienung ab D4
zeigt, ob die Funktion Prefill (aufgrund Fahrpedalgradient) ausgelöst wird; zeigt keinen Funktionszustand bezüglich Fehlerstilllegung

MQB: Wird gesetzt bei jeder Art von aktivem Prefill";
CM_ SG_ 262 ESP_Rueckwaertsfahrt_erkannt "nur bei AU57x und AU416 sowie Audi B8PA
Info, ob Rückwärtsfahrt über internen Algorithmus sicher erkannt

Im MQB wird das Signal nicht unterstützt!";
CM_ SG_ 262 ESP_Status_Anfahrhilfe "Funktionsstatus des Berganfahrassistenten
MQB: Auswertung im Getriebe zwecks Standabkopplung";
CM_ SG_ 262 ESP_HDC_aktiv "MQB und AU57x Allroad: Mit diesem Statusbit wird eine gerade aktive Regelung des Bergabfahrassistenten (Hill Descent Control) signalisiert.";
CM_ SG_ 262 ESP_StartStopp_Info "Stopp-Freigabe und Start-Anforderung an den Start-Stopp-Koordinator";
CM_ SG_ 262 ESP_Eingr_HL "wird von QSP und Neigungsanzeige verwendet

Flag wird vom ESP gesetzt, sobald aufgrund eines ESP-Eingriffs am Rad aktiv Druck aufgebaut wird.
Frühestens mit öffnen des Ventils und spätestens bei einem Bremsmoment von 100Nm. Flag bleibt solange gesetzt ";
CM_ SG_ 262 ESP_Eingr_HR "wird von QSP und Neigungsanzeige verwendet

Flag wird vom ESP gesetzt, sobald aufgrund eines ESP-Eingriffs am Rad aktiv Druck aufgebaut wird.
Frühestens mit öffnen des Ventils und spätestens bei einem Bremsmoment von 100Nm. Flag bleibt solange gesetzt ";
CM_ SG_ 262 ESP_Eingr_VL "wird von QSP und Neigungsanzeige verwendet

Flag wird vom ESP gesetzt, sobald aufgrund eines ESP-Eingriffs am Rad aktiv Druck aufgebaut wird.
Frühestens mit öffnen des Ventils und spätestens bei einem Bremsmoment von 100Nm. Flag bleibt solange gesetzt ";
CM_ SG_ 262 ESP_Eingr_VR "wird von QSP und Neigungsanzeige verwendet

Flag wird vom ESP gesetzt, sobald aufgrund eines ESP-Eingriffs am Rad aktiv Druck aufgebaut wird.
Frühestens mit öffnen des Ventils und spätestens bei einem Bremsmoment von 100Nm. Flag bleibt solange gesetzt ";
CM_ SG_ 262 ESP_BKV_Unterdruck "Der maximale Wert wird auf 1012 mbar begrenzt.
Dieses Signal wird im AU64x nicht unterstützt.

Hinweis: Auch bei nicht verbautem BKV-Unterdrucksensor könnte während der Initialisierung der Initialisierungswert gesendet werden.";
CM_ SG_ 262 ESP_Autohold_aktiv "Rückmeldung an EPB, dass Autohold aktiv ist.";
CM_ SG_ 262 ESP_FStatus_Anfahrhilfe "Bei gesetztem Bit steht die Funktion Berganfahrassistent (Hillhold) nicht zur Verfügung";
CM_ SG_ 262 ESP_Verz_EPB_aktiv "Bei gesetztem Bit wird die Verzögerungsanforderung von EPB umgesetzt.";
CM_ SG_ 262 ESC_Bremslicht "Die Bremslichtansteuerung erfolgt, wenn die Ist_Verzögerung für eine Dauer von  (ca.100 ms) die bewertete Verzögerungsschwelle unterschreitet (Einschaltschwelle Bremslicht),  Bremsdruck vorhanden aufgrund ECD , EMP, HMS oder HDC. Bei AWV2 wird von Beginn ";
CM_ SG_ 262 ESP_Verzoeg_EPB_verf "Bei gesetztem Bit ist der Verzögerungsregeler für EPB verfügbar.";
CM_ SG_ 262 ESP_Status_Bremsdruck "MLB: Bei gesetztem Bit liegt p > ca. 2 bar an, hervorgerufen durch Fahrer, ASR, FZR, ECD, Bremsregler ... bei Abfall des Bits ist p < X bar, bei aktivem ECD-Eingriff Ende des Eingriffs 

Weiterführende Informationen im Lastenheft spezifiziert und in der";
CM_ SG_ 262 ESP_Anforderung_EPB "ESP fordert von der EPB Öffnen bzw. Schliessen an. Notwendig wegen Autohold-Funktion.";
CM_ SG_ 914 ESP_07_CRC "Für MLB:
'Berechnung siehe Lastenheft 'Kommunikationsabsicherung für FlexRay und CAN''

Ab MQB und MLBevo:
'Berechnung siehe Lastenheft 'End-to-End Kommunikationsabsicherung''

Endwerte siehe Begleitdokument 'S-PDU Kennungsfolgen'";
CM_ SG_ 914 ESP_ACC_LDE "Verwendung/Bedienung ab Folgeprojekte D4, aber nicht im D4 selbst
Lebensdauerende für ACC-Bremsung erreicht";
CM_ SG_ 914 ESP_Allrad_Antrieb "Im MQB wird das Signal nicht unterstützt!";
CM_ SG_ 914 ESP_Codierung_ADS "ESP gibt für Empfänger im Fahrzeug aus, ob ADS verbaut/nicht verbaut ist.

Im MQB wird das Signal nicht unterstützt!
";
CM_ SG_ 914 ESP_RTA_HL "Physikalischer Wertebereich +/-5%. Der Reifentoleranzabgleich bezieht sich auf das linke Vorderrad.

physikalischer Wert = ( (Hex-Wert - 0x7F) / 2048 )*100%

Im MQB wird das Signal nicht unterstützt!";
CM_ SG_ 914 ESP_RTA_HR "Physikalischer Wertebereich +/-5%. Der Reifentoleranzabgleich bezieht sich auf das linke Vorderrad.

physikalischer Wert = ( (Hex-Wert - 0x7F) / 2048 )*100%

Im MQB wird das Signal nicht unterstützt!";
CM_ SG_ 914 ESP_RTA_VR "Physikalischer Wertebereich +/-5%. Der Reifentoleranzabgleich bezieht sich auf das linke Vorderrad.

physikalischer Wert = ( (Hex-Wert - 0x7F) / 2048 )*100%

Im MQB wird das Signal nicht unterstützt!";
CM_ SG_ 914 OBD_Fehler_Radsensor_HL "Für Motor-SG (gesetzliche Vorgabe)";
CM_ SG_ 914 OBD_Fehler_Radsensor_HR "Für Motor-SG (gesetzliche Vorgabe)";
CM_ SG_ 914 OBD_Fehler_Radsensor_VL "Für Motor-SG (gesetzliche Vorgabe)";
CM_ SG_ 914 OBD_Fehler_Radsensor_VR "Für Motor-SG (gesetzliche Vorgabe)";
CM_ SG_ 914 ESP_Qualifizierung_Antriebsart "Signal for Bentley BY83x: ESP_wheel_drive_selector

Bit qualifiziert für neue Projekte (ab D4 ff.) das Signal 'ESP_Quattro_Antrieb', d.h. ist 'ESP_Qualifizierung_Antriebsart'
auf 0x1 gesetzt, ändert sich die bisherige Bedeutung des Signals 'ESP_Quattro";
CM_ SG_ 914 ESP_Offroad_Modus "Nur VW526: Bei Offroad-Fahrzeugen kann über einen Schalter ein Offroadmodus gewählt werden, dieser wird hier angezeigt. Bei Offroad Plus- Fahrzeugen wird hier der Offroadmodus indirekt durch das Verteilergetriebe vorgegeben (ALR_Offroad = 1) und eingespie";
CM_ SG_ 914 ESP_MKB_ausloesbar "ESP hat Funktion Multi-Kollisions-Bremsung freigeschaltet";
CM_ SG_ 914 ESP_Stat_FallBack_eBKV "Das Signal zeigt dem eBKV an, ob seine Rückfallebene im ESP verfügbar ist.";
CM_ SG_ 914 ESP_CM_Variante "Signal gibt an welche CM-Variante unterstuetzt wird. 
";
CM_ SG_ 914 ESP_OBD_Status "Dieses Bit steuert die MIL-Lampe an (Motorsteuergerät reicht diese Info an Kombi weiter).";
CM_ SG_ 914 ESP_Rollenmodus_Deaktivieren "Zwang zum Abbruch des Rollenmodus mit anschließender ESP-Vollfunktion.
MQB: Zwang zum Abbruch des Rollenmodus in allen Funktionsteilnehmern (Empfänger) mit anschließender ESP-Vollfunktion (Sender).
Signal wird vom ESP dauerhaft mit gültigen Werten bedat";
CM_ SG_ 914 ESP_nachtr_Stopp_Anf "Dieses Signal dient dem Motor als Trigger, dass ein nachträglicher Motorstopp eingeleitet werden kann, wenn es die Bedingungen des StSt Koordinators dies zulassen. ";
CM_ SG_ 278 ESP_10_CRC "Für MLB:
'Berechnung siehe Lastenheft 'Kommunikationsabsicherung für FlexRay und CAN''

Ab MQB und MLBevo:
'Berechnung siehe Lastenheft 'End-to-End Kommunikationsabsicherung''

Endwerte siehe Begleitdokument 'S-PDU Kennungsfolgen'

Wird im Projekt";
CM_ SG_ 278 ESP_10_BZ "MQB: ACHTUNG: Systematische Botschaftszählersprünge im I- und KCAN durch asynchrones Routing der ESP_10 (Originalsender 20ms zyklisch) vom FCAN

Wird im Projekt D4 und D4Hybrid nicht verwendet!  Wird im D4 PA verwendet";
CM_ SG_ 278 ESP_QBit_Wegimpuls_VL "Qualifizierungsbit Wegimpulszähler VL

Wird im Projekt D4 und D4Hybrid nicht verwendet!  Wird im D4 PA verwendet";
CM_ SG_ 278 ESP_QBit_Wegimpuls_VR "Qualifizierungsbit Wegimpulszähler VR

Wird im Projekt D4 und D4Hybrid nicht verwendet!  Wird im D4 PA verwendet";
CM_ SG_ 278 ESP_QBit_Wegimpuls_HL "Qualifizierungsbit Wegimpulszähler HL

Wird im Projekt D4 und D4Hybrid nicht verwendet!  Wird im D4 PA verwendet";
CM_ SG_ 278 ESP_QBit_Wegimpuls_HR "Qualifizierungsbit Wegimpulszähler HR

Wird im Projekt D4 und D4Hybrid nicht verwendet!  Wird im D4 PA verwendet";
CM_ SG_ 278 ESP_Wegimpuls_VL "Wegimpulszähler VL.
Anzahl der Wegimpulse Vorderrad links (steigende und fallende Flanke)
Zähler läuft grundsätzlich vorwärts, auch bei Rückwärtsfahrt.
Nach SG-Reset ist immer, ohne Ausnahme, 1mal der Init Wert 1021 zu senden.

Wird im Projekt D4 und";
CM_ SG_ 278 ESP_Wegimpuls_VR "Wegimpulszähler VR.
Anzahl der Wegimpulse Vorderrad rechts (steigende und fallende Flanke)
Zähler läuft grundsätzlich vorwärts, auch bei Rückwärtsfahrt.
Nach SG-Reset ist immer, ohne Ausnahme, 1mal der Init Wert 1021 zu senden.

Wird im Projekt D4 un";
CM_ SG_ 278 ESP_Wegimpuls_HL "Wegimpulszähler HL.
Anzahl der Wegimpulse Hinterrad links (steigende und fallende Flanke)
Zähler läuft grundsätzlich vorwärts, auch bei Rückwärtsfahrt.
Nach SG-Reset ist immer, ohne Ausnahme, 1mal der Init Wert 1021 zu senden.

Wird im Projekt D4 und";
CM_ SG_ 278 ESP_Wegimpuls_HR "Wegimpulszähler HR.
Anzahl der Wegimpulse Hinterrad rechts (steigende und fallende Flanke)
Zähler läuft grundsätzlich vorwärts, auch bei Rückwärtsfahrt.
Nach SG-Reset ist immer, ohne Ausnahme, 1mal der Init Wert 1021 zu senden.

Wird im Projekt D4 un";
CM_ SG_ 278 ESP_VL_Fahrtrichtung "Drehrichtung Rad VL

Weiterführende Informationen im Lastenheft spezifiziert und in der entsprechenden Fachabteilung zu erfragen.

Wird im Projekt D4 und D4Hybrid nicht verwendet!  Wird im D4 PA verwendet";
CM_ SG_ 278 ESP_VR_Fahrtrichtung "Drehrichtung Rad VR

Weiterführende Informationen im Lastenheft spezifiziert und in der entsprechenden Fachabteilung zu erfragen.

Wird im Projekt D4 und D4Hybrid nicht verwendet!  Wird im D4 PA verwendet";
CM_ SG_ 278 ESP_HL_Fahrtrichtung "Drehrichtung Rad HL

Weiterführende Informationen im Lastenheft spezifiziert und in der entsprechenden Fachabteilung zu erfragen.

Wird im Projekt D4 und D4Hybrid nicht verwendet!  Wird im D4 PA verwendet";
CM_ SG_ 278 ESP_HR_Fahrtrichtung "Drehrichtung Rad HR

Weiterführende Informationen im Lastenheft spezifiziert und in der entsprechenden Fachabteilung zu erfragen.

Wird im Projekt D4 und D4Hybrid nicht verwendet!  Wird im D4 PA verwendet";
CM_ BO_ 418 "MLBevo verlangsamte 100ms-Botscahft";
CM_ SG_ 418 ESP_15_CRC "Für MLB:
'Berechnung siehe Lastenheft 'Kommunikationsabsicherung für FlexRay und CAN''

Ab MQB und MLBevo:
'Berechnung siehe Lastenheft 'End-to-End Kommunikationsabsicherung''

Endwerte siehe Begleitdokument 'S-PDU Kennungsfolgen'

Wird im Projekt";
CM_ SG_ 418 ESP_15_BZ "MQB: ACHTUNG: Systematische Botschaftszählersprünge im I- und KCAN durch asynchrones Routing der ESP_10 (Originalsender 20ms zyklisch) vom FCAN

Wird im Projekt D4 und D4Hybrid nicht verwendet!  Wird im D4 PA verwendet";
CM_ SG_ 418 HMS_P_beibehalten_GE "Fordert das Getriebe auf in Stellung 'P' zu bleiben.";
CM_ SG_ 418 HMS_Konsistenz_GE "Zeigt an, ob die Kommunikation und die Anforderungen plausibel sind.";
CM_ SG_ 418 HMS_Konsistenz_IPA "Zeigt an, ob die Kommunikation und die Anforderungen plausibel sind.
";
CM_ SG_ 418 HMS_Konsistenz_EBKV "Zeigt an, ob die Kommunikation und die Anforderungen plausibel sind.
";
CM_ SG_ 418 HMS_Konsistenz_RCTA "Zeigt an, ob die Kommunikation und die Anforderungen plausibel sind.";
CM_ SG_ 418 HMS_Konsistenz_STA "Zeigt an, ob die Kommunikation und die Anforderungen plausibel sind.";
CM_ SG_ 418 HMS_Konsistenz_MO "Zeigt an, ob die Kommunikation und die Anforderungen plausibel sind.";
CM_ SG_ 418 HMS_halten_nicht_verfuegbar "Rueckmeldung HMS-Teilfunktion 'Halten' nicht verfuegbar.";
CM_ SG_ 418 HMS_parken_nicht_verfuegbar "Rueckmeldung HMS-Teilfunktionen 'Parken' nicht verfuegbar.";
CM_ SG_ 418 HMS_Anforderung_GE "Fordert vom Getriebe bestimmte Schaltstellungen an.";
CM_ SG_ 418 HMS_Systemstatus "Zeigt den aktuellen Systemstatus des HMS an.";
CM_ SG_ 418 HMS_Stillstand "Das Signal zeigt, basierend auf den vier ESP-Raddrehzahlinformatioen, gefiltert und/oder entprellt mehrstufig den Fahrzeuggeschwindigkeitszustand an.";
CM_ SG_ 418 HMS_aktives_System "Zeigt an, von welchem System die Anforderung gerade umgesetzt wird.";
CM_ SG_ 418 HMS_Konsistenz_HVLM "Zeigt an, ob die Kommunikation und die Anforderungen plausibel sind.";
CM_ SG_ 418 HMS_Konsistenz_ACC "Zeigt an, ob die Kommunikation und die Anforderungen plausibel sind.";
CM_ SG_ 418 HMS_Fehlerstatus "Zeigt den Fehlerstatus des Haltemanagementsystems HMS an.
Details zu den Werten 3/4:
3=Systemeinschränkung, Parken EPB oder GSG nicht möglich
4=Systemstörung bzw. Parken EPB und GSG nicht möglich  ";
CM_ SG_ 418 ESP_Index_Haltemoment "Zeigt an, ob das Summen-Radmoment von ESP_Haltemoment ein Bremsmoment (bergab) oder ein Antriebsmoment (bergauf) darstellt.";
CM_ SG_ 418 ESP_Haltemoment "Zeigt in Abhängigkeit von ESP_Index_Haltemoment das notwendige Summen-Radmoment an (bergab: Bremsmoment; bergauf: Antriebsmoment), das mindestens notwendig ist um das Fahrzeug an der aktuellen Neigung zu halten.";
CM_ BO_ 1629 "neu im MQB";
CM_ SG_ 1629 ESP_20_CRC "Für MLB:
'Berechnung siehe Lastenheft 'Kommunikationsabsicherung für FlexRay und CAN''

Ab MQB und MLBevo:
'Berechnung siehe Lastenheft 'End-to-End Kommunikationsabsicherung''

Endwerte siehe Begleitdokument 'S-PDU Kennungsfolgen'";
CM_ SG_ 1629 BR_Systemart "Identifikation des verbauten Bremssystems

Dient dem Kombi zur Plausibilisierung";
CM_ SG_ 1629 ESP_SpannungsAnf_02 "Forderung des ESP-SG's zur Spannungsanhebung.";
CM_ SG_ 1629 ESP_Zaehnezahl "Konstanter Wert der Zähnezahl des verwendeten Impulsrades wird ausgegeben, jeder Empfänger der Wegimpulse muss die Zähnezahl einlesen, um eine volle Umdrehung des Rades zu erkennen. 

Weiterführende Informationen im Lastenheft spezifiziert und in der en";
CM_ SG_ 1629 ESP_Charisma_FahrPr "MLBevo: Aktuelles Fahrprogramm des Charisma-Teilnehmers (siehe Systemlastenheft Drive Select)
MQB: Istwert der Kennlinie (siehe Systemlastenheft MQB FPA)";
CM_ SG_ 1629 ESP_Charisma_Status "Systemstatus des Charismateilnehmers

Wert 0x3 ist nur für Fahrzeuge ab MQB relevant";
CM_ SG_ 1629 ESP_Wiederstart_Anz_01 "Dieses Signal gibt die detaillierte Begründung für einen Wiederstart vom Bremsensteuergerät an. ";
CM_ SG_ 1629 ESP_Wiederstart_Anz_02 "Dieses Signal gibt die detaillierte Begründung für einen Wiederstart vom Bremsensteuergerät an. ";
CM_ SG_ 1629 ESP_Wiederstart_Anz_03 "Dieses Signal gibt die detaillierte Begründung für einen Wiederstart vom Bremsensteuergerät an. ";
CM_ SG_ 1629 ESP_Wiederstart_Anz_04 "Dieses Signal gibt die detaillierte Begründung für einen Wiederstart vom Bremsensteuergerät an.";
CM_ SG_ 1629 ESP_Stoppverbot_Anz_01 "Dieses Signal gibt die detaillierte Begründung für ein Stoppverbot vom Bremsensteuergerät an.";
CM_ SG_ 1629 ESP_Stoppverbot_Anz_02 "Dieses Signal gibt die detaillierte Begründung für ein Stoppverbot vom Bremsensteuergerät an.";
CM_ SG_ 1629 ESP_Stoppverbot_Anz_03 "Dieses Signal gibt die detaillierte Begründung für ein Stoppverbot vom Bremsensteuergerät an.";
CM_ SG_ 1629 ESP_Stoppverbot_Anz_04 "Dieses Signal gibt die detaillierte Begründung für ein Stoppverbot vom Bremsensteuergerät an.";
CM_ SG_ 1629 ESP_Stoppverbot_Anz_05 "Dieses Signal gibt die detaillierte Begründung für ein Stoppverbot vom Bremsensteuergerät an.";
CM_ SG_ 1629 ESP_Stoppverbot_Anz_06 "Dieses Signal gibt die detaillierte Begründung für ein Stoppverbot vom Bremsensteuergerät an.";
CM_ SG_ 1629 ESP_Stoppverbot_Anz_07 "Dieses Signal gibt die detaillierte Begründung für ein Stoppverbot vom Bremsensteuergerät an.";
CM_ SG_ 1629 ESP_Stoppverbot_Anz_Std "Dieses Signal gibt die detaillierte Begründung für ein Stoppverbot vom Bremsensteuergerät an.";
CM_ SG_ 1629 ESP_Dachrelingsensor "Erkennung auf Verbau des Dachrelingsensors und Dachquerträger.";
CM_ SG_ 1629 ESP_Stoppverbot_Anz_08 "Dieses Signal gibt die detaillierte Begründung für ein Stoppverbot vom Bremsensteuergerät an.";
CM_ SG_ 1629 HDC_Charisma_FahrPr "MLBevo: Aktuelles Fahrprogramm des Charisma-Teilnehmers (siehe Systemlastenheft Drive Select)
MQB: Istwert der Kennlinie (siehe Systemlastenheft MQB FPA)";
CM_ SG_ 1629 HDC_Charisma_Status "Systemstatus des Charismateilnehmers

Wert 0x3 ist nur für Fahrzeuge ab MQB relevant";
CM_ SG_ 1629 BR_QBit_Reifenumfang "Gesetzt bei Ersatzwert, Init oder Fehler.";
CM_ SG_ 1629 BR_Reifenumfang "Mittlerer Radumfang gerechnet in Millimeter.
Von der Bremse plausibilisierter Wert (Kopie von KBI_Reifenumfang wenn dieser plausibel) oder Ersatzwert aus Bremse wenn KBI_Reifenumfang unplausibel. Bitte das QBit beachten!";
CM_ BO_ 253 "Neue Momente im MQB
Struktur ab MQB mit CRC8 entstanden aus ESP_01";
CM_ SG_ 253 ESP_21_CRC "Für MLB:
'Berechnung siehe Lastenheft 'Kommunikationsabsicherung für FlexRay und CAN''

Ab MQB und MLBevo:
'Berechnung siehe Lastenheft 'End-to-End Kommunikationsabsicherung''

Endwerte siehe Begleitdokument 'S-PDU Kennungsfolgen'";
CM_ SG_ 253 BR_Eingriffsmoment "Einheitenloser Wert! Faktor in MO_Faktor_Momente_02 in Motor_Code_01 beachten!
Schnelle reduzierende (ASR) oder erhöhende (MSR) Momentanforderung an den Motor.";
CM_ SG_ 253 ESP_PLA_Bremseingriff "Signalisierung des aktiven Bremseingriffes des ESP aufgrund einer Bremsanforderung vom PLA.";
CM_ SG_ 253 ESP_Diagnose "MLB: Nach Diagnoseende wird ein SW-Reset ausgelöst welcher einen Kommunikatiosausfall für max. 150ms verursacht. Dies ist bei SG mit verschärfter Timeoutüberwachung (nicht nach Konzern-LH) zu beachten.

MQB: Weiterführende Informationen im Lastenheft sp";
CM_ SG_ 253 ESC_v_Signal_Qualifier_High_Low "Das Qualifizerungssignal ESC_v_Signal_Qualifier_High_Low gibt eine Information über die Güte der vom Bremsregelsystem ausgegebenen Geschwindigkeitsinformation 'mittlere Geschwindigkeit', wobei Vertrauensbereiche für das ausgegebene Geschwindigkeitssignal ";
CM_ SG_ 253 ESP_Vorsteuerung "zur Unterscheidung zwischen ESP-Vorsteuermaßnahmen und ESP-Regeleingriffen";
CM_ SG_ 253 OBD_Schlechtweg "Für Ausblendung der Zündaussetzererkennung im Motorsteuergerät (Otto). Bit wird gesetzt, wenn Rad-Drehbeschleunigung im ESP > Grenzwert ist. Vorteil gegenüber Radgeschwindigkeiten, dass ESP alle 2 ms dynamisch die Rad-Drehbeschleunigung errechnet und dem ";
CM_ SG_ 253 ESP_v_Signal "Geschwindigkeitssignal vom ABS/ASR oder ESP. Mittelwert der angetriebenen Räder.
Bei MSR oder ABS Eingriffen wird die ABS-Referenzgeschwindigkeit für >= 200ms eingespiegelt (Zeit wird mit Aktiv-Flanke der Funktionsbits getriggert)

MQB: Bei Frontantrie";
CM_ SG_ 253 ASR_Tastung_passiv "ASR deaktiviert oder Schwellen geändert (projektabhängig)
Weiterführende Informationen im Lastenheft spezifiziert und in der entsprechenden Fachabteilung zu erfragen.
";
CM_ SG_ 253 ESP_Tastung_passiv "ESP deaktiviert oder Schwellen geändert (projektabhängig)
Weiterführende Informationen im Lastenheft spezifiziert und in der entsprechenden Fachabteilung zu erfragen.";
CM_ SG_ 253 ESP_Systemstatus "Fehler steht für Stillegung ESP mit Fehlereintrag.

MLB: Flag wird bei Unterspannung im Stand bis einmalig 6km/h (AU48x) oder 10 km/h (AU641, AU57x) überschritten nicht gesetzt (Ausblendung Startvorgang)
Im AU64x, AU57x gilt ESP D4 Funktionsanforderung";
CM_ SG_ 253 ASR_Schalteingriff "Wunsch an das Getriebe während einer ASR Regelung

MLB: Es wird nur 0x0 und 0x1 genutzt

";
CM_ SG_ 253 ESP_Haltebestaetigung "Rückmeldung vom ESP-SG, dass das Fahrzeug aufgrund einer externen Bremsanforderung (z. B. ACC, PLA, ANB, o. ä.) abgebremst wurde und im Stillstand gehalten wird.";
CM_ SG_ 253 ESP_MKB_Abbruch_Geschw "Im Falle einer Multikollisionsbremsung teilt das ESP den Abbruch der MKB aufgrund der unteren Geschwindigkeitsschwelle mit.";
CM_ SG_ 253 ESP_QBit_v_Signal "Geschwindigkeit wird vom ABS/ASR oder ESP aus Ersatzwerten errechnet, wenn Bit gesetzt ist. Güte des Signals ist verändert.";
CM_ SG_ 253 ABS_Bremsung "Antiblockiersystem, Bit zeigt auch Druckabbau an (z.B. ESP hat zuviel Druck aufgebaut oder ungebremste Regelung auf Bahnübergang)
Weiterführende Informationen im Lastenheft spezifiziert und in der entsprechenden Fachabteilung zu erfragen.";
CM_ SG_ 253 ASR_Anf "MLB: Die Momentenanforderung 'ASR_MSR_Moment_schnell' und 'ASR_Moment_langsam' sind auszuführen
MQB: Die Momentenanforderung 'BR_Eingriffsmoment' ist auszuführen";
CM_ SG_ 253 MSR_Anf "MLB: Die Momentenanforderung 'ASR_MSR_Moment_schnell' ist auszuführen.
MQB: Die Momentenanforderung 'BR_Eingriffsmoment' ist auszuführen";
CM_ SG_ 253 EBV_Eingriff "Elektronische Bremskraftverteilung, aktueller Eingriff (Druckhalten, Druckabbau)

Im MLB: kein ABS / ESP-Eingriff ???";
CM_ SG_ 253 EDS_Eingriff "Elektronische Differentialsperre";
CM_ SG_ 253 ESP_Eingriff "Eingriff des Fahrdynamikreglers";
CM_ SG_ 253 ESP_ASP "MLB: Anhaenger-Stabilisierungs-Programm
MQB: Gespannstabilisierung";
CM_ BO_ 795 "neu für MQB wg. Absicherung
Entstanden aus ESP_04";
CM_ SG_ 795 ESP_24_CRC "Für MLB:
'Berechnung siehe Lastenheft 'Kommunikationsabsicherung für FlexRay und CAN''

Ab MQB und MLBevo:
'Berechnung siehe Lastenheft 'End-to-End Kommunikationsabsicherung''

Endwerte siehe Begleitdokument 'S-PDU Kennungsfolgen'";
CM_ SG_ 795 ESP_Lampe "Zustand der Fahrdynamikregelungslampe (MLB: ASR und/oder ESP, MQB: nur ESP)

Weiterführende Informationen im Lastenheft spezifiziert und in der entsprechenden Fachabteilung zu erfragen.";
CM_ SG_ 795 ABS_Lampe "Sicherheitswarnlampe

Weiterführende Informationen im Lastenheft spezifiziert und in der entsprechenden Fachabteilung zu erfragen.";
CM_ SG_ 795 BK_Lampe_02 "Sicherheitswarnlampe signalisiert EBV-Ausfall

MQB: wird auch bei HBV-Ausfall verwendet.

Weiterführende Informationen im Lastenheft spezifiziert und in der entsprechenden Fachabteilung zu erfragen.";
CM_ SG_ 795 TC_Lampe "M-ABS Lampe (separate Lampe für M-ABS-Systeme Markt Brasilien)

Weiterführende Informationen im Lastenheft spezifiziert und in der entsprechenden Fachabteilung zu erfragen.";
CM_ SG_ 795 ESP_m_Raddrehz "Radumdrehungen pro Sekunde sind Eingangsgröße für die Geschwindigkeitsberechnung im Kombi. Aus dieser Raddrehzahl und dem Radumfang wird die Fahrzeuggeschwindigkeit errechnet.

MLB: Exklusiver Empfänger ist das Kombiinstrument!
MQB: Bei Frontantrieb un";
CM_ SG_ 795 ESP_Textanzeigen_03 "Textanzeigen der Fahrdynamikregelung im Kombiinstrument

Weiterführende Informationen im Lastenheft spezifiziert und in der entsprechenden Fachabteilung zu erfragen.";
CM_ SG_ 795 ESP_Meldungen "ESP sendet im Hinweis- /Störungsfall an das Kombi Informationen zum Anzeigen

Weiterführende Informationen im Lastenheft spezifiziert und in der entsprechenden Fachabteilung zu erfragen.
Ergänzender Hinweis:
1 = Autohold_Hinweis_1 (Anfahrassistent: nu";
CM_ SG_ 795 ESP_Wegimp_VA "Weiterführende Informationen im Lastenheft spezifiziert und in der entsprechenden Fachabteilung zu erfragen.

MLB: Die Wegimpulse Vorderachse sind die gemittelten Werte (reine mathematische Operation: Addition und Division durch zwei, keine Filterung) d";
CM_ SG_ 795 ESP_Fehlerstatus_Wegimp "Weiterführende Informationen im Lastenheft spezifiziert und in der entsprechenden Fachabteilung zu erfragen.

MLB: Fehler wird gesetzt, wenn beide ESP-Drehzahlfühler an der Vorderachse defekt sind.

MQB: Fehler wird gesetzt, wenn beide Raddrehzahlfühl";
CM_ SG_ 795 ESP_Wegimp_Ueberlauf "Der Wegimpulszähler ist pro Zündungslauf mindestens einmal übergelaufen

Weiterführende Informationen im Lastenheft spezifiziert und in der entsprechenden Fachabteilung zu erfragen.";
CM_ SG_ 795 ESP_QBit_Wegimp_VA "Gesetzt bei Ersatzwert, Init oder Fehler.";
CM_ SG_ 795 ESP_HDC_FktLampe "Funktionslampe Bergabfahrassistent.
(Sender blinkt mit dem Bit 3,3Hz)";
CM_ SG_ 795 ESP_Off_Lampe "Bit zur Ansteuerung der separaten ESP-off-Lampe im Kombi (Gesetzesforderung USA)

MLB:
Verwendung/Bedienung ab D4";
CM_ SG_ 795 ESP_HDC_Regelgeschw "Verwendung/Bedienung nur im AU57x Allroad:
HDC-Geschwindigkeit
Dient der Anzeige der HDC-Geschwindigkeit und eines Bergabfahrsymbols im Kombi.
HDC-Standby wird gesetzt sobald der Fahrer den HDC-Taster aktiviert hat.
Bei HDC-Off oder während der Initia";
CM_ SG_ 795 ESP_BKV_Warnung "ESP sendet im Hinweis- /Störungsfall an das Kombi Informationen zum Anzeigen (Text + Akustik)

Im MQB wird dieses Signal nicht unterstützt!
";
CM_ BO_ 508 "CAN-Botschaft";
CM_ SG_ 508 ESP_32_CRC "Für MLB:
'Berechnung siehe Lastenheft 'Kommunikationsabsicherung für FlexRay und CAN''

Ab MQB und MLBevo:
'Berechnung siehe Lastenheft 'End-to-End Kommunikationsabsicherung''

Endwerte siehe Begleitdokument 'S-PDU Kennungsfolgen'";
CM_ SG_ 508 ESP_Status_Bremsentemp_02 "Bremsscheibentemperaturmodell. Rückmeldung für Sender einer Verzögerungsanforderung";
CM_ SG_ 508 ESP_Aggregataktivitaet "Info über die Aktivität des ESP Aggregats bei aktivem Druckaufbau oder Ventilaktivität";
CM_ SG_ 508 ESP_Stillstandsflag "Bei RB-Projekten wird das Stillstandsflag gesetzt, wenn der absolute Stillstand der Raddrehzahlsensoren erkannt wurde, d.h. kein Zahn bewegt sich mehr. Dieses Bit wird bspw. im MOST für TV-Tuner-Abschaltung Australien verwendet, d.h. leichte Erschütterung";
CM_ SG_ 508 ESC_FBA_Meldungen "Hinweis an den Fahrer über das Kombi, bei dauerhafter Bergabfahrt einen Gang einzulegen um die Motorbremse zu nutzen.
Unterscheidung zwischen: 
Handschalterfahrzeugen (FBA_Warnung_aktiv_MT)
Automatikfahrzeugen (FBA_Warnung_aktiv_AT)";
CM_ SG_ 508 ESP_Rollover_Status_dyn "Information vom ESP an die Dämpferregelung über den dynamischen Rolloverstatus";
CM_ SG_ 508 ESP_Rollover_Status_stat "Information vom ESP an die Dämpferregelung über den statischen Rolloverstatus";
CM_ SG_ 508 ESP_AVH_LED "Ansteuerung der AVH Funktions-LED durch das BCM.
0 = LED aus
1 = LED ein
2 = LED blinken
3 = Funktion gesperrt, LED aus
4 = frei
5 = frei
6 = Init
7 = frei";
CM_ SG_ 508 ESP_HDC_LED "Ansteuerung der HDC LED in der Schalterleiste durch BCM
0 = LED aus
1 = LED ein
2 = LED blinken
3 = Funktion gesperrt, LED aus
4 = frei
5 = frei
6 = Init
7 = frei";
CM_ SG_ 508 ESP_Off_LED "Ansteuerung der ESP-Off LED in der Schalterleiste durch BCM
0 = LED aus
1 = LED ein
2 = LED blinken
3 = Funktion gesperrt, LED aus
4 = frei
5 = frei
6 = Init
7 = frei";
CM_ SG_ 508 ESP_Notbremsanzeige "ABS/ASR oder ESP hat Notbremssituation erkannt.
Weiterführende Informationen im Lastenheft spezifiziert und in der entsprechenden Fachabteilung zu erfragen.

";
CM_ SG_ 508 ESC_Motorstartverzoegerung "Mit dem Signal 'Motorstartverzögerung' wird den aktiven Teilnehmern ermöglicht, einen Motorstart durch die Start-Stop-Funktion zu verzögern.";
CM_ SG_ 508 ESP_Offroad_Lampe "Anzeige der ESC-Offroad-Lampe im Kombiinstrument für Bentley";
CM_ SG_ 508 ESP_HDC_Textanzeigen "Textanzeigen der HDC im Kombiinstrument für Bentley";
CM_ SG_ 427 ESP_33_CRC "Für MLB:
'Berechnung siehe Lastenheft 'Kommunikationsabsicherung für FlexRay und CAN''

Ab MQB und MLBevo:
'Berechnung siehe Lastenheft 'End-to-End Kommunikationsabsicherung''

Endwerte siehe Begleitdokument 'S-PDU Kennungsfolgen'";
CM_ SG_ 427 ESC_AHW_aktiv "Rueckmeldung Anhaltewegregelung aktiv
";
CM_ SG_ 427 ESC_AHW_nicht_verfuegbar "Rueckmeldung Anhaltewegregelung nicht verfuegbar
";
CM_ SG_ 427 ESC_ANB_CM_aktiv "Rueckmeldung ANB_CM (Autom_Notbremsung_Collision_Mitigation) aktiv
";
CM_ SG_ 427 ESC_ANB_CM_nicht_verfuegbar "Rueckmeldung ANB_CM nicht verfuegbar
";
CM_ SG_ 427 ESC_Warnruck_aktiv "Rueckmeldung Warnruck aktiv";
CM_ SG_ 427 ESC_Warnruck_nicht_verfuegbar "Rueckmeldung Warnruck nicht verfuegbar";
CM_ SG_ 427 ESC_Prefill_aktiv "Rueckmeldung Prefill aktiv";
CM_ SG_ 427 ESC_Prefill_nicht_verfuegbar "Rueckmeldung Prefill nicht verfuegbar";
CM_ SG_ 427 ESC_HBA_aktiv "Rueckmeldung HBA (hydraulischer Bremsassistent) aktiv";
CM_ SG_ 427 ESC_HBA_nicht_verfuegbar "Rueckmeldung HBA (hydraulischer Bremsassistent) nicht verfuegbar";
CM_ SG_ 427 ESC_TSK_SRBM_Anf "Quittierung fuer TSK (SRBM=Summenradbremsmoment) Anforderung";
CM_ SG_ 427 ESC_TSK_SRBM_nicht_verfuegbar "Rueckmeldung TSK (SRBM= Summenradbremsmoment) nicht verfuegbar";
CM_ SG_ 427 ESC_Verz_Reg_aktiv "Rueckmeldung Verzoegerungsregelung aktiv";
CM_ SG_ 427 ESC_Verz_Reg_nicht_verfuegbar "Rueckmeldung Verzoegerungsregelung nicht verfuegbar";
CM_ SG_ 427 ESC_Verz_Reg_TB_nicht_verfuegbar "Rueckmeldung Verzoegerungsregelung (Teilbremsung) nicht verfuegbar";
CM_ SG_ 427 ESC_Verz_Reg_ZB_nicht_verfuegbar "Rueckmeldung Verzoegerungsregelung ZB (Zielbremsung) nicht verfuegbar";
CM_ SG_ 427 ESC_Bremslicht_unplausibel "Plausibilisierung der Rückmeldeinformation von BCM/AAG bezüglich Anforderung ESC_Bremslicht";
CM_ SG_ 427 ESC_Konsistenz_ACC "Rueckmeldung Konsistenz der ACC Botschaften";
CM_ SG_ 427 ESC_Konsistenz_AWV "Rueckmeldung Konsistenz der AWV Botschaften";
CM_ SG_ 427 ESC_Konsistenz_ARA "Rueckmeldung Konsistenz der ARA Botschaften";
CM_ SG_ 427 ESC_Konsistenz_IPA "Rueckmeldung Konsistenz der IPA Botschaften";
CM_ SG_ 427 ESC_Konsistenz_FCW "Rueckmeldung Konsistenz der FCW Botschaften";
CM_ SG_ 427 ESC_Konsistenz_NV "Rueckmeldung Konsistenz der NightVision Botschaften";
CM_ SG_ 427 ESC_Konsistenz_RCTA "Rueckmeldung Konsistenz der RCTA (Rear Cross Traffic Alert) Botschaften";
CM_ SG_ 427 ESC_Konsistenz_TSK "Rueckmeldung Konsistenz der TSK Botschaften";
CM_ SG_ 427 ESC_Konsistenz_vFGS "Rueckmeldung Konsistenz der vFGS Botschaften";
CM_ SG_ 427 ESC_Konsistenz_STA "Rueckmeldung Konsistenz der STA Botschaften";
CM_ SG_ 427 ESC_Fahrer_Bremsdruck_bestimmend "Das Signal zeigt an, dass der Fahrer Bremsdruck bestimmend ist";
CM_ SG_ 427 ESC_Konsistenz_EA "Rueckmeldung Konsistenz der EA Botschaften (HCA)";
CM_ SG_ 427 ESC_Konsistenz_BFF "Rückmeldung Konsistenz der Verzögerungsanforderung an das ESC-Steuergerät der Funktion 'Bremsen im freien Fahren' vom PDC_PLA_ARA-Steuergerät";
CM_ SG_ 427 ESC_Konsistenz_MKB "Rückmeldung Konsistenz für MKB-Verzögerungsanfoorderung";
CM_ SG_ 2589283470 ESC_Kilometer "Kilometerstand aus dem ESC ";
CM_ SG_ 2589283470 ESC_Kilometer_MUX "Zeigt an ob ein GFA oder IKA signierter Kilometerstand übertragen wird";
CM_ SG_ 2589283470 ESC_Signatur_Kilometer_GFA_01 "GFA Signatur des Kilometerstandes";
CM_ SG_ 2589283470 ESC_Signatur_Kilometer_IKA_01 "IKA Signatur des Kilometerstandes";
CM_ SG_ 2589283470 ESC_Signatur_Kilometer_GFA_02 "GFA Signatur des Kilometerstandes";
CM_ SG_ 2589283470 ESC_Signatur_Kilometer_IKA_02 "IKA Signatur des Kilometerstandes";
CM_ BO_ 264 "ab MLBevo mit CRC";
CM_ SG_ 264 Fahrwerk_01_CRC "Für MLB:
'Berechnung siehe Lastenheft 'Kommunikationsabsicherung für FlexRay und CAN''

Ab MQB und MLBevo:
'Berechnung siehe Lastenheft 'End-to-End Kommunikationsabsicherung''

Endwerte siehe Begleitdokument 'S-PDU Kennungsfolgen'";
CM_ SG_ 264 FA_Hoehenwerte_kalibriert "Legt fest, wie die Höhensensorwerte interpretiert werden müssen. Umschaltung kalibrierte Höhenwerte / Rohsignale in Byte 3-6

Achtung:
Im AUDI B8 Konstante: 0x1. D.h. es werden nur Rohwerte bedient!
Im AUDI D4 Konstante: 0x0. D.h. es werden nur Millim";
CM_ SG_ 264 FA_Hoehenwert_VL_00 "Aktueller Höhenwert (kalibriert) Vorne Links; ungefiltertes Signal
Einheit, Offset und Faktor sind abhänig von 'FA_Hoehenwert_kalibriert'

Achtung:
Wird im AUDI B8 nicht bedient";
CM_ SG_ 264 FA_Hoehenwert_VR_00 "Aktueller Höhenwert (kalibriert) Vorne Rechts; ungefiltertes Signal
Einheit, Offset und Faktor sind abhänig von 'FA_Hoehenwert_kalibriert'

Achtung:
Wird im AUDI B8 nicht bedient";
CM_ SG_ 264 FA_Hoehenwert_HL_00 "Aktueller Höhenwert (kalibriert) Hinten Links; ungefiltertes Signal
Einheit, Offset und Faktor sind abhänig von 'FA_Hoehenwert_kalibriert'

Achtung:
Wird im AUDI B8 nicht bedient";
CM_ SG_ 264 FA_Hoehenwert_HR_00 "Aktueller Höhenwert (kalibriert) Hinten Rechts; ungefiltertes Signal
Einheit, Offset und Faktor sind abhänig von 'FA_Hoehenwert_kalibriert'

Achtung:
Wird im AUDI B8 nicht bedient";
CM_ SG_ 429 Fahrwerk_06_CRC "Ab MQB und MLBevo:
'Berechnung siehe Lastenheft 'End-to-End Kommunikationsabsicherung''

Endwerte siehe Begleitdokument 'S-PDU Kennungsfolgen'";
CM_ SG_ 429 NR_Reglerstatus "Anzeige des auszuregelnden Sollniveaus (wird bei Beginn der Regelung auf entsprechenden Wert gesetzt).";
CM_ SG_ 429 FA_Verstellung_in_Kuerze "Dieses Bit wird gesetzt, wenn eine Verstellung unmittelbar bevorsteht.";
CM_ SG_ 429 FA_Verstellung_aktiv "Verstellung ist aktiv. Dieses Bit wird immer gesetzt in Verbindung mit den Bits FA_Anhebung_Fahrzeug oder FA_Absenkung_Fahrzeug.";
CM_ SG_ 429 FA_Kompressor_laeuft_in_Kuerze "Kompressorlauf steht unmittelbar bevor. Das Bit wird immer gesetzt in Verbindung mit den Bits FA_Anhebung_Fahrzeug oder FA_Absenkung_Fahrzeug.";
CM_ SG_ 429 FA_Kompressor_laeuft "Zustand der Kompressoransteuerung";
CM_ SG_ 429 NR_Anforderung_v_Begrenzung "Anforderung einer v-Begrenzung an das Motor-SG.";
CM_ SG_ 429 NR_LED_SGN "Statusrückmeldung der eingestellten Fahrzeughöhe Sondergeländeniveau bzw. Tasterbetätigung Anheben/Absenken.";
CM_ SG_ 429 NR_LED_TN "Statusrückmeldung der eingestellten Fahrzeughöhe Tiefniveau";
CM_ SG_ 429 NR_LED_BN "Statusrückmeldung der eingestellten Fahrzeughöhe Beladungsniveau bzw. Tasterbetätigung Anheben/Absenken.";
CM_ SG_ 429 FA_Absenkung_Fahrzeug "Nächsttieferes Niveau wird angefahren (Absenken). Dieses Bit wird immer gesetzt in Verbindung mit einer Auswahl aus den Bits FA_Verstellung_xx.";
CM_ SG_ 429 FA_Anhaengerstatus_intern "Anzeige des SG-internen Verarbeitungsstatus Anhängers";
CM_ SG_ 429 FA_Anhebung_Fahrzeug "Nächsthöheres Niveau wird angefahren (Anheben). Dieses Bit wird immer gesetzt in Verbindung mit einer Auswahl aus den Bits FA_Verstellung_xx.";
CM_ SG_ 429 FA_Druckspeicher_verfuegbar "Bit ist gesetzt, wenn eine Regelung aus dem Druckspeicher möglich ist.";
CM_ SG_ 429 FA_ESP_Zuschaltung "Zwangsweise Aktivierung der ESP-Funktionalität wird angefordert auch bei Passivtastung";
CM_ SG_ 429 NR_LED_HN "Statusrückmeldung der eingestellten Fahrzeughöhe Hochniveau
";
CM_ SG_ 429 FA_Zwischenniveau "Dieses Bit wird gesetzt, wenn die Fahrzeughöhe zwischen 2 definierten Niveaus liegt, z.B.. während des Regelvorgangs.";
CM_ SG_ 429 FA_Systemstatus "Bit wird gesetzt, wenn interne Funktionsprüfung i.O. und System generell funktionsfähig ist.";
CM_ SG_ 429 EFP_Soll_FahrPr_HAL "Anforderung einer Zwangsumschaltung des Fahrprogramms der HAL durch EFP";
CM_ SG_ 429 NR_Kompressor_Temp_Zylinderkopf "Gemessene Temperatur im Zylinderkopf des Luftfeder-Kompressors";
CM_ SG_ 429 FA_Signal_Drucksensor "Signalwert des Drucksensors im Magnetventilblock";
CM_ SG_ 1605 FLA_aktiv "FLA aktiv  (200ms Task)";
CM_ SG_ 1605 FLA_ISP_defekt "FLA Innenspiegel defekt
interner Fehler  (200ms Task)";
CM_ SG_ 1605 FLA_Sensor_blockiert "FLA Sensor blockiert
Sichtbeeinträchtigung CMOS-Kamera  (200ms Task)";
CM_ SG_ 1605 FLA_Abblendursache "FLA Abblendursache
(20ms Task)";
CM_ SG_ 1605 FLA_Fernlicht_PWM "FLA PWM Vorgabe Fernlicht
(20ms Task)";
CM_ SG_ 1605 ISP_EC_Lichtwert_vorne "Innenspiegel: Lichtwert vorne
";
CM_ SG_ 1605 ISP_EC_Lichtwert_hinten "Innenspiegel: Lichtwert hinten
";
CM_ SG_ 1605 ISP_Himmelsrichtung "Himmelsrichtung Kompass im EC Spiegel
Wertebereich 0-29 (12°-Schritte, 0-348°)
";
CM_ SG_ 1605 ISP_Taste_betaetigt "ISP Taste betätigt
(200ms Task)";
CM_ SG_ 1605 ISP_EC_aktiv "Status Innenspiegel (EC-Spiegel)
";
CM_ SG_ 1605 ISP_Kompass_aktiv "Status Kompass Innenspiegel
";
CM_ SG_ 1605 ISP_Dimmung_ASP_02 "Dimmwertvorgabe für Aussenspiegel
Es wird 1:1 die Spannung am Innenspiegel nach außen übertragen.";
CM_ SG_ 1605 FLA_Aufblenden "FLA Aufblenden (20ms Task)";
CM_ SG_ 1605 FLA_SAE_Mode "Rückmeldung an den Fahrer, über Wechsel in den SAE Modus --> wird nur für den amerikanischen Markt benötigt.";
CM_ SG_ 1726 FSS_Laenge_Pos "Position Längs Fahrersitz";
CM_ SG_ 1726 FSS_Hoehe_Pos "Position Hoehe Fahrersitz";
CM_ SG_ 1726 FSS_Kopfstuetze_Pos "Position Kopfstuetze";
CM_ SG_ 1726 FSS_Neigung_Lehne_Pos "Position Lehnenneigung Fahrersitz";
CM_ BO_ 1727 "ab MLBevo: 8 Byte";
CM_ SG_ 1727 FSS_Lehnenkopf_Pos "Position Lehnenkopf Fahrersitz";
CM_ SG_ 1727 FSS_Neigung_Sitz_Pos "Position Sitzneigung Fahrersitz";
CM_ SG_ 1727 FSS_KopfstuetzeX_Pos "Berücksichtigung der Kopfstützen-X-Position in der Sysmmetriefahrt.";
CM_ SG_ 173 Getriebe_11_CRC "Für MLB:
'Berechnung siehe Lastenheft 'Kommunikationsabsicherung für FlexRay und CAN''

Ab MQB und MLBevo:
'Berechnung siehe Lastenheft 'End-to-End Kommunikationsabsicherung''

Endwerte siehe Begleitdokument 'S-PDU Kennungsfolgen'";
CM_ SG_ 173 Getriebe_11_BZ "MQB: ACHTUNG: Systematische Botschaftszählersprünge im F- und ECAN durch asynchrones Routing der Getriebe_11 (Originalsender 10ms zyklisch) vom ACAN";
CM_ SG_ 173 GE_MMom_Soll_02 "Momenteneingriff an den Motor.
Fordert vom MSG eine kurzfristige Reduzierung oder Anhebung des Moments.
Das Signal ist nur gültig in Kombination mit GE_MMom_Status (bei MQB) bzw. GE_MMom_Status_02 (bei MLBevo).

Achtung:
Einheitenloser Wert! Faktor i";
CM_ SG_ 173 GE_MMom_Vorhalt_02 "Anforderung einer Momentenreserve durch das Getriebe, gilt nur mit Freigabe durch 
GE_Freig_MMom_Vorhalt

Anforderung wird als Absolut-Wert umgesetzt, nicht als Relativ-Wert/Delta zum aktuellen Ist-Moment (d. h. eine Momentenreserve wird eingestellt, w";
CM_ SG_ 173 GE_Uefkt "Übertragungsfunktion des Getriebes
Drehzahlverhältnis = Eingangsdrehzahl / Ausgangsdrehzahl

AL: Wandlerverstärkung x Drehzahlverhältnis
VL: Drehzahlverhältnis
DL: Drehzahlverhältnis der aktiven und kraftschluß führenden Welle zum Abtrieb, bei Schalt";
CM_ SG_ 173 GE_Fahrstufe "Fahrprogramm des Getriebes

Hinweis: Zwischenstellung '0x0' darf nur für Zustandswechsel P/R, R/N, N/D ausgegeben werden, nicht für D/S oder D/Tippgasse wegen Abschaltkriterium GRA/ACC";
CM_ SG_ 173 GE_reserv_Fahrstufe "reserviert, falls künftig Erweiterung von GE_Fahrstufe nötig";
CM_ SG_ 173 GE_Schaltablauf "Das Signal zeigt den aktuellen Status eines Schaltvorgangs.

Bei Signal = 0 liegt kein Schaltvorgang vor.
Bei Signal =2 liegt die Befüllphase der zuschaltenden Kupplung bzw. 
                      die Vorbereitungsphase dazu vor.

Mit den unterschie";
CM_ SG_ 173 GE_Uefkt_unplausibel "Das Signal darf nur im Reku-Manager in Hybrid-Varianten verwendet werden.
Zeigt an, ob die Plausibilisierung Momenten-Verhältnis zu Drehzahl-Verhältnis i.O. ist.
Ein gesetztes Signal meldet eine unplausible GE_Uefkt bzw. GE_Uefkt_02.";
CM_ SG_ 173 GE_MMom_Status_02 "Das Signal qualifiziert GE_MMom_Soll_02 und gibt an, wie GE_MMom_Soll_02 umgesetzt werden soll.
Werte:
0= kein Eingriff
1=   absoluter reduzierender Eingriff auf Gesamt Antrieb nur über schnellen Pfad 
2 = absoluter, erhöhender Eingriff auf Gesamt-Ant";
CM_ SG_ 173 GE_Status_Kraftschluss "Zeigt den Ist-Status des Kraftschlusses im Getriebe.
(Anmerkung: meist wird damit der Zustand des Anfahrelements beschrieben, d.h. bei DL/DQ die Kupplung;  bei AQ/AL der Wandler incl. Überbrückungskupplung)
0 = offen, kein Kraftschluss
1 = offen mit Kr";
CM_ SG_ 173 GE_MMom_Status "Qualifiziert 
MLB: GE_MMom_Soll
MQB: GE_MMom_Soll_02";
CM_ SG_ 173 GE_Freig_MMom_Vorhalt "Freigabe für die Anforderung einer Momentenreserve durch das Getriebe über das Signal
MLB: GE_MMom_Vorhalt
MQB/MLBevo: GE_MMom_Vorhalt_02";
CM_ SG_ 173 GE_Verbot_Ausblendung "Verbot Einspritzausblendung für komfortable Schaltungen";
CM_ SG_ 173 GE_Zielgang "VL-Getriebe:
Signalisiert den Zielgang im manuellen Modus während eines Schaltvorgangs bzw. die momentane simulierte Gangstufe wenn kein Schaltvorgang aktiv ist. In den Fahrprogrammen 'D' und 'S' ist die Übersetzung variabel und somit wird dauerhaft 'Ist";
CM_ SG_ 968 GE_OBD_AbsperrVent "Das Getriebesteuergerät führt eine elektrische Diagnose des von ihm angesteuerten Absperrventils für den Öl-Wasser-Wärmetauscher durch und übermittelt das Ergebnis an das MSG (Standard-4Bit-OBD-Status, nicht alle Zustände müssen genutzt werden; so sind z.";
CM_ SG_ 968 GE_amax_moeglich "AL/DL: maximal mögliche Beschleunigung unter Berücksichtigung aller möglichen Gänge.

Eine Reduzierung des maximalen Motormoments durch Efficiency wird in dem Signal berücksichtigt.

VL: maximal mögliche Beschleunigung bei Nenndrehzahl (Efficency wird";
CM_ SG_ 968 GE_Charisma_FahrPr "MLBevo: Aktuelles Fahrprogramm des Charisma-Teilnehmers (siehe Systemlastenheft Drive Select)
MQB: Istwert der Kennlinie (siehe Systemlastenheft MQB FPA)";
CM_ SG_ 968 GE_Charisma_Status "Charisma Systemstatus des Charisma-Teilnehmers

Wert 0x3 ist nur für Fahrzeuge ab MQB relevant";
CM_ SG_ 968 GE_Freigabe_Verfallsinfo_WFS "WFS";
CM_ SG_ 968 Freilauf_Charisma_FahrPr "MLBevo: Aktuelles Fahrprogramm des Charisma-Teilnehmers (siehe Systemlastenheft Drive Select)
MQB: Istwert der Kennlinie (siehe Systemlastenheft MQB FPA)";
CM_ SG_ 968 Freilauf_Charisma_Status "Charisma Systemstatus des Charisma-Teilnehmers

Wert 0x3 ist nur für Fahrzeuge ab MQB relevant";
CM_ SG_ 968 GE_Freigabe_Info_WFS "WFS-Freigabeinformation";
CM_ SG_ 968 GE_Sperr_Info_WFS "WFS-Sperrinformation";
CM_ SG_ 968 GE_Zustand_Kuppltemp "Dieses Signal gibt den Temperaturzustand der Kupplung im DQ-Getriebe (z. Zt. DQ2x0, DQ500) an das ACC-System.";
CM_ SG_ 968 GE_Codierung_MSG "Statusausgabe der Diagnose für Falschverbau. Plausibilisierung der empfangenen Motor- und Getriebevariante mit der erwarteten Motor- und Getriebevarianten.";
CM_ SG_ 968 GE_LaunchControl "Während einer LaunchControl-Anfahrt sendet das Getriebesteuergerät das Bit LaunchControl aktiv.
Die Bremse wertet dieses Bit aus, um während einer solchen Anfahrt die Regelgrenzen der Schlupfregelung zu erweitern.
Im Motor Nutzung zur Verbesserung des A";
CM_ SG_ 968 GE_OBD_Status "Dieses Bit steuert die MIL-Lampe an (Motorsteuergerät reicht diese Info an Kombi weiter).";
CM_ SG_ 968 GE_LFR_Adaption "Qualifiziert das ausgegeben Motorbelastungsmoment (durch GE_Vorsteuermoment) für die Verwendung zur LFR (Leerlauffüllungsregelung) im Moto";
CM_ SG_ 968 GE_Sumpftemperatur "Getriebesumpftemperatur wird über den Temperatursensor auf der Getriebeplatine ermittelt. Die absolute Sumpftemperatur wird vom Motor empfangen, um entsprechende Kühlleistung für das Getriebe einzustellen.";
CM_ SG_ 310 HAL_01_CRC "Für MLB:
'Berechnung siehe Lastenheft 'Kommunikationsabsicherung für FlexRay und CAN''

Ab MQB und MLBevo:
'Berechnung siehe Lastenheft 'End-to-End Kommunikationsabsicherung''

Endwerte siehe Begleitdokument 'S-PDU Kennungsfolgen'
";
CM_ SG_ 310 HAL_Status "Status der Hinterachslenkung
0: normaler Betrieb 
1: HAL verriegelt (z.B. harter Fehler, nicht kalibriert)
2: Rücknahme der Leistung, Funktion eingeschränkt/Derating aktiv 
3: HAL deaktiviert";
CM_ SG_ 310 HAL_VZ_Radwinkel "Lenkrichtung der HAL";
CM_ SG_ 310 HAL_QBit_Radwinkel "Wenn Bit gesetzt, dann entspreicht das Signal nicht mehr ASIL-D. (z.B. Ausfall der redundanten Sensorik)";
CM_ SG_ 310 HAL_Radwinkel "Zusätzlich durch die HAL gestellter Radwinkeloffset an der Hinterachse in Grad";
CM_ SG_ 310 HAL_Warnungen "Warnmeldungsanforderung von der Hinterachslenkung an das Kombiinstrumnent";
CM_ SG_ 310 HAL_VZ_Fahrerwunschwinkel_Soll "Soll-Lenkrichtung der HAL";
CM_ SG_ 310 HAL_Fahrerwunschwinkel_Soll "Zielwinkel (=Fahrerwunschwinkel) am Rad Hinterachslenkung in Grad";
CM_ SG_ 310 HAL_max_Gradient "maximaler Zustellgradient für die Stabilisierungsfunktion mit HAL durch ESP";
CM_ SG_ 310 HAL_EFP_FahrPr "Aktueller Ist-Zustand der HAL";
CM_ SG_ 310 HAL_Charisma_Status "Rückmeldung an den Charisma-Master";
CM_ SG_ 310 HAL_Charisma_FahrPr "MLBevo: Aktuelles Fahrprogramm des Charisma-Teilnehmers (siehe Systemlastenheft Drive Select)
MQB: Istwert der Kennlinie (siehe Systemlastenheft MQB FPA)";
CM_ SG_ 676 HAL_02_CRC "Für MLB:
'Berechnung siehe Lastenheft 'Kommunikationsabsicherung für FlexRay und CAN''

Ab MQB und MLBevo:
'Berechnung siehe Lastenheft 'End-to-End Kommunikationsabsicherung''

Endwerte siehe Begleitdokument 'S-PDU Kennungsfolgen'";
CM_ SG_ 676 HAL_02_BZ "4bit Botschaftszaehler; wird in jeder Sendebotschaft inkrementiert";
CM_ SG_ 676 HAL_ARA_Status "Anforderung vom Anhängerrangierassistent. 
16 Statuswerte";
CM_ SG_ 676 HAL_PLA_Status "16 Statuswerte (siehe LH PLA/HAL)";
CM_ SG_ 676 HAL_PWR_Abbruch "Dieses Signal gibt das Abbruchkriterium für PLA und ARA an.
";
CM_ SG_ 676 HAL_PWR_Fehler "Gibt den Fehler aus wenn eine Radwinkelanforderung nicht ausgeführt werden konnte.
";
CM_ SG_ 1410 HD_Endstellung_oben "obere Endstellung HD
";
CM_ SG_ 1410 HD_Endstellung_unten "untere Endstellung HD
";
CM_ SG_ 1410 HD_Bewegung_auf "Bewegung HD (öffnen)
";
CM_ SG_ 1410 HD_Bewegung_zu "Bewegung HD (schließen)
";
CM_ SG_ 1410 HD_Innentaster_betaetigt "Betätigung Innentaster HD
";
CM_ SG_ 1410 HD_UeKB_erkannt "Erkennung Einklemmschutz
";
CM_ SG_ 1410 HD_Position "HD Position von 0 bis 100 %";
CM_ SG_ 1410 HD_Taster_defekt "Anzeige ob Heckdeckeltaster defekt ist";
CM_ SG_ 1410 HD_Rueckmeld_prog "Programmierung Endstellung HD 
";
CM_ SG_ 1410 HD_Verriegelungstaster_betaetigt "Betätigung des Verriegelungstaster für Heckdeckel";
CM_ SG_ 1410 HD_Verr_Taster_betaetigt_inv "Inverses Bit (Fusi-Anforderung) Betätigung des Verriegelungstaster für Heckdeckel";
CM_ SG_ 1410 HD_ZZH_Schalter_S3 "Teilt den Zustand des Statusschalters in einer unidirektionalen ZZH mit.";
CM_ BO_ 1416 "Heizleistungsregelung";
CM_ SG_ 1416 FSH_LED "LED Ansteuerung Frontscheibenheizung";
CM_ SG_ 1416 HSH_LED "LED Ansteuerung Heckscheibenheizung";
CM_ SG_ 1416 SIH_Stufe_LED_li "Statusmeldung Sitzheizung links";
CM_ SG_ 1416 SIH_Stufe_LED_re "Statusmeldung Sitzheizung rechts";
CM_ SG_ 1416 SIL_Stufe_LED_li "Statusmeldung Sitzlüftung links";
CM_ SG_ 1416 SIL_Stufe_LED_re "Statusmeldung Sitzlüftung rechts";
CM_ SG_ 1416 KRH_Stufe_LED_li "Statusmeldung Kopfraumheizung links";
CM_ SG_ 1416 KRH_Stufe_LED_re "Statusmeldung Kopfraumheizung rechts";
CM_ SG_ 1416 BCM1_TCH_HLR_Anf "Kundenanforderung des Thermocupholders zum Heizen-/Kühlen";
CM_ SG_ 1416 HLR_SIH_Freigabe_Fond "Freigabe des EM für Sitzheizungen hinten";
CM_ BO_ 1016 "Heizleistungsregelung 
MLBevo (NVEM im Gateway)";
CM_ SG_ 1016 HLR_FlHz_Freigabe_Ruhesitz "Freigabe des NVEM für die Flächenheizung des Ruhesitzes";
CM_ SG_ 1016 HLR_FlHz_Freigabe_VR "Freigabe des NVEM für die Flächenheizung vorne rechts";
CM_ SG_ 1016 HLR_FlHz_Freigabe_VL "Freigabe des NVEM für die Flächenheizung vorne links";
CM_ SG_ 1016 HLR_FlHz_Freigabe_HR "Freigabe des NVEM für die Flächenheizung hinten rechts";
CM_ SG_ 1016 HLR_FlHz_Freigabe_HL "Freigabe des NVEM für die Flächenheizung hinten links";
CM_ SG_ 1016 HLR_TCH_Freigabe "Freigabe des NVEM für den Thermocupholder";
CM_ SG_ 1016 HLR_SIH_Freigabe_Fond "Freigabe des EM für Sitzheizungen hinten";
CM_ SG_ 1016 HLR_Sp_Heizung_Freigabe_BT "Freigabe der Außenspiegelheizung Beifahrerseite";
CM_ SG_ 1016 HLR_Sp_Heizung_Freigabe_FT "Freigabe des EEM für die Außenspiegelheizung rechtsFreigabe der Außenspiegelheizung Fahrerseite";
CM_ SG_ 1016 HLR_KRH_Freigabe_VL "Freigabe des EEM für die Kopfraumheizung vorne links";
CM_ SG_ 1016 HLR_KRH_Freigabe_VR "Freigabe des EEM für die Kopfraumheizung vorne rechts";
CM_ SG_ 1016 HLR_SIH_Freigabe_VL "Freigabe des EEM für die Sitzheizung vorne links";
CM_ SG_ 1016 HLR_SIH_Freigabe_VR "Freigabe des EEM für die Sitzheizung vorne rechts";
CM_ SG_ 1016 HLR_SIH_Freigabe_HL "Freigabe des EEM für die Sitzheizung hinten links";
CM_ SG_ 1016 HLR_SIH_Freigabe_HR "Freigabe des EEM für die Sitzheizung hinten rechts";
CM_ SG_ 1016 HLR_SIL_Freigabe_VL "Freigabe des EEM für die Sitzlüftung Vorne Links";
CM_ SG_ 1016 HLR_SIL_Freigabe_VR "Freigabe des EEM für die Sitzlüftung vorne Rechts";
CM_ SG_ 1016 HLR_SIL_Freigabe_HL "Freigabe des EEM für die Sitzbelüftung hinten links";
CM_ SG_ 1016 HLR_SIL_Freigabe_HR "Freigabe des EEM für die Sitzlüftung hinten rechts";
CM_ SG_ 1016 HLR_FSH_Freigabe "Freigabe des EEM für die Frontscheibenheizung";
CM_ SG_ 1016 HLR_HSH_Freigabe "Freigabe des EEM für die Heckscheibenheizung";
CM_ SG_ 1016 HLR_LRH_Freigabe "Freigabe für die Lenkradheizung";
CM_ SG_ 1016 HLR_PTC_linear_Freigabe "Freigabe des EEM für den linearen PTC-Zuheizer";
CM_ SG_ 1016 HLR_PTC_Freigabe "Freigabe des elektrischen Energiemanagements für das gestufte/geregelte PTC";
CM_ SG_ 1412 HSP_01_CRC "CRC8-Checksumme über alle Datenbytes der Botschaft HSPs_01

 Für MLB:
 'Berechnung siehe Lastenheft 'Kommunikationsabsicherung für Flexray und CAN''

 Ab MQB und MLBevo:
 'Berechnung siehe Lastenheft 'End-to-End Kommunikationsabsicherung'

 Endwer";
CM_ SG_ 1412 HSP_Warnung_LED "Kombi Warnung LED Spoiler";
CM_ SG_ 1412 HSP_Warnung_Ton "Kombi Warnung Ton Spoiler";
CM_ SG_ 1412 HSP_Warnung_Text "Kombi Warnung Text Spoiler";
CM_ SG_ 1412 HSP_Endlage_eingefahren "Spoiler in Endlage eingefahren";
CM_ SG_ 1412 HSP_Endlage_ausgefahren "Spoiler in Endlage ausgefahren";
CM_ SG_ 1412 HSP_ResponseError "siehe LIN2.0-Specification
(Darf nicht über ein Fehlergueltigkeitsbit abgesichtert werden!)";
CM_ SG_ 1412 HSP_def "Spoilersteuergerät defekt";
CM_ SG_ 1412 HSP_Motor_def "elektr. Fehler im Spoilermotor";
CM_ SG_ 1412 HSP_Taster_Error "Spoiler meldet Tasterfehler";
CM_ SG_ 1412 HSP_LED_Error "Spoiler meldet LED-Fehler";
CM_ SG_ 1412 HSP_Charisma_FahrPr "MLBevo: Aktuelles Fahrprogramm des Charisma-Teilnehmers (siehe Systemlastenheft Drive Select)
MQB: Istwert der Kennlinie (siehe Systemlastenheft MQB FPA)";
CM_ SG_ 1412 HSP_Charisma_Status "Rückmeldung an den Charisma-Master

Wert 0x3 ist nur für Fahrzeuge ab MQB relevant";
CM_ SG_ 1283 HVK_01_CRC "Für MLB:
'Berechnung siehe Lastenheft 'Kommunikationsabsicherung für FlexRay und CAN''

Ab MQB und MLBevo:
'Berechnung siehe Lastenheft 'End-to-End Kommunikationsabsicherung''

Endwerte siehe Begleitdokument 'S-PDU Kennungsfolgen'";
CM_ SG_ 1283 HVK_Istmodus_Anf "HVK-Anforderung an alle HV-Komponenten deren Istmodus im schnellen Zyklus (Inhibitzeit) zu senden.";
CM_ SG_ 1283 HVK_MO_EmSollzustand "Anforderung vom HVK Sollzustand der Elm_State
0 = HvOff              
1 = HvStbyReq          
2 = HvStbyWait         
3 = HvBattOnReq        
4 = HvBattOnWait       
10 = HvOnIdle          
18 = HvOnDrvReq        
19 = HvOnDrvWait       
20 = HvO";
CM_ SG_ 1283 HVK_BMS_Sollmodus "Angeforderter Sollmodus der HV-Batterie:
0 : HV_Off                                
1 : HV_On (HS geschlossen)                
2 : nicht belegbar                        
3 : nicht belegbar                        
4 : AC-Laden (HS +AC-Schütze geschlos";
CM_ SG_ 1283 HVK_DCDC_Sollmodus "angeforderte Soll-Betriebsart des DC/DC-Wandlers: 
0: Standby; Kommunikation aktiv
1: Tiefsetzen (HV --> BN 14,4V)
    Sollwertvorgabe projektabhängig vom BSG/BCM über Lin/BSS oder vom MSG über 'MO_DC_SollSpannung_NV' bzw. 'MY2_DC_uSetPLV'
    (PQ35/P";
CM_ SG_ 1283 HVK_EKK_Sollmodus "Sollmodus elektrischer Klimakompressor";
CM_ SG_ 1283 HVK_HVPTC_Sollmodus "Sollmodus HV-PTC
0 : keine Freigabe
1 : Freigabe
2 : nicht belegbar
3 : nicht belegbar
4 : nicht belegbar
5 : nicht belegbar
6 : nicht belegbar
7 : Init   (CAN-Initialisierung)   

Info: 'nicht belegbar' d.h. Sollmodus nicht relevant für HVK";
CM_ SG_ 1283 HVK_HVLM_Sollmodus "Angeforderter Sollmodus des Lademanagers.";
CM_ SG_ 1283 HVK_HV_Netz_Warnungen "Anforderung Warnung/Fehler HV-System im Kombi
0: Keine Warnung/Init
1:Anforderung_Anzeige_Warnung_HV-Netz (gelbes Symbol)
2:Anforderung_Anzeige_Fehler_HV-Netz (rotes Symbol)
3:Anforderung_Anzeige_Warnung_Kein_Wiederstart_möglich";
CM_ SG_ 1283 HV_Bordnetz_aktiv "Signalisiert ein aktives Hochvoltbordnetz. HV-Schütze geschlossen. Im Fehlerfall wird das Bit nicht gesetzt.(Klemmende Schütze)";
CM_ SG_ 1283 HV_Bordnetz_Fehler "Status ob im  HV-Netz ein Fehler detektiert wurde.";
CM_ SG_ 1283 HVK_Gesamtst_Spgfreiheit "Status des HV-Systems";
CM_ SG_ 1283 HVK_AktiveEntladung_Anf "Anforderung zum aktiven Entladen des HV-Netzes, während der Abschaltung des HV-Netz.";
BA_DEF_ BO_  "DiagRequest" ENUM  "No","Yes";
BA_DEF_ BO_  "DiagResponse" ENUM  "No","Yes";
BA_DEF_ BO_  "DiagState" ENUM  "No","Yes";
BA_DEF_ BO_  "GenMsgChkConstant" HEX 0 4095;
BA_DEF_ BO_  "GenMsgCycleTime" INT 0 65535;
BA_DEF_ BO_  "GenMsgCycleTimeFast" INT 0 65535;
BA_DEF_ BO_  "GenMsgDelayTime" INT 0 100000;
BA_DEF_ BO_  "GenMsgILSupport" ENUM  "No","Yes";
BA_DEF_ BO_  "GenMsgNrOfRepetition" INT 0 100;
BA_DEF_ BO_  "GenMsgPDUConstants" STRING ;
BA_DEF_ BO_  "GenMsgSendType" ENUM  "Cyclic","not_used","not_used","not_used","not_used","not_used","not_used","IfActive","NoMsgSendType";
BA_DEF_ BO_  "GenMsgStartDelayTime" INT 0 100000;
BA_DEF_ BO_  "NmMessage" ENUM  "No","Yes";
BA_DEF_ BO_  "NmhMessage" ENUM  "No","Yes";
BA_DEF_ BO_  "MsgType" ENUM  "Application","NM ","NMH","TP2.0","ISO-TP ","BAP","EID";
BA_DEF_ BO_  "VAGTP20_API" HEX 0 255;
BA_DEF_ BO_  "VAGTP20_DynConnection" ENUM  "No","Yes";
BA_DEF_ BO_  "VAGTP20_DynSetup" ENUM  "No","Yes";
BA_DEF_ BO_  "VAGTP20_StatConnection" ENUM  "No","Yes";
BA_DEF_ SG_  "GenSigActiveRepetitions" INT -2147483648 2147483647;
BA_DEF_ SG_  "GenSigInactiveValue" INT -2147483648 2147483647;
BA_DEF_ SG_  "GenSigSendType" ENUM  "Cyclic","OnWrite","OnWriteWithRepetition","OnChange","OnChangeWithRepetition","IfActive","IfActiveWithRepetition","NoSigSendType","OnChangeAndIfActive","OnChangeAndIfActiveWithRepetition";
BA_DEF_ SG_  "GenSigStartValue" INT -2147483648 2147483647;
BA_DEF_ SG_  "NWM-WakeupAllowed" ENUM  "No","Yes";
BA_DEF_ SG_  "GenSigFuncType" ENUM  "NoFunction","MsgCounter","CRC-8","XOR","XOR-2","DatedBit","SW-Kl15","CHK","Constant","Protocol","CRC-8-SAE_J1850";
BA_DEF_ SG_  "GenSigSwitchedByIgnition" ENUM  "No","Yes";
BA_DEF_ SG_  "Fehlerwert" HEX 0 2147483647;
BA_DEF_ SG_  "GenSigMissingSourceValue" HEX 0 2147483647;
BA_DEF_REL_ BU_SG_REL_  "GenSigTimeoutTime" INT 0 65535;
BA_DEF_DEF_  "DiagRequest" "No";
BA_DEF_DEF_  "DiagResponse" "No";
BA_DEF_DEF_  "DiagState" "No";
BA_DEF_DEF_  "GenMsgChkConstant" 0;
BA_DEF_DEF_  "GenMsgCycleTime" 0;
BA_DEF_DEF_  "GenMsgCycleTimeFast" 0;
BA_DEF_DEF_  "GenMsgDelayTime" 0;
BA_DEF_DEF_  "GenMsgILSupport" "No";
BA_DEF_DEF_  "GenMsgNrOfRepetition" 0;
BA_DEF_DEF_  "GenMsgPDUConstants" "";
BA_DEF_DEF_  "GenMsgSendType" "NoMsgSendType";
BA_DEF_DEF_  "GenMsgStartDelayTime" 0;
BA_DEF_DEF_  "NmMessage" "No";
BA_DEF_DEF_  "NmhMessage" "No";
BA_DEF_DEF_  "MsgType" "Application";
BA_DEF_DEF_  "VAGTP20_API" 0;
BA_DEF_DEF_  "VAGTP20_DynConnection" "No";
BA_DEF_DEF_  "VAGTP20_DynSetup" "No";
BA_DEF_DEF_  "VAGTP20_StatConnection" "No";
BA_DEF_DEF_  "GenSigActiveRepetitions" 0;
BA_DEF_DEF_  "GenSigInactiveValue" 0;
BA_DEF_DEF_  "GenSigSendType" "NoSigSendType";
BA_DEF_DEF_  "GenSigStartValue" 0;
BA_DEF_DEF_  "NWM-WakeupAllowed" "No";
BA_DEF_DEF_  "GenSigFuncType" "NoFunction";
BA_DEF_DEF_  "GenSigSwitchedByIgnition" "Yes";
BA_DEF_DEF_  "Fehlerwert" 0;
BA_DEF_DEF_  "GenSigMissingSourceValue" 0;
BA_DEF_DEF_REL_ "GenSigTimeoutTime" 0;
BA_ "GenMsgSendType" BO_ 262 0;
BA_ "GenMsgPDUConstants" BO_ 262 "0x07,0x07,0x07,0x07,0x07,0x07,0x07,0x07,0x07,0x07,0x07,0x07,0x07,0x07,0x07,0x07";
BA_ "GenMsgILSupport" BO_ 262 1;
BA_ "GenMsgCycleTime" BO_ 262 20;
BA_ "GenMsgChkConstant" BO_ 262 7;
BA_ "GenMsgSendType" BO_ 914 0;
BA_ "GenMsgPDUConstants" BO_ 914 "0x91,0x91,0x91,0x91,0x91,0x91,0x91,0x91,0x91,0x91,0x91,0x91,0x91,0x91,0x91,0x91";
BA_ "GenMsgILSupport" BO_ 914 1;
BA_ "GenMsgCycleTime" BO_ 914 80;
BA_ "GenMsgChkConstant" BO_ 914 145;
BA_ "GenMsgSendType" BO_ 278 0;
BA_ "GenMsgPDUConstants" BO_ 278 "0xac,0xac,0xac,0xac,0xac,0xac,0xac,0xac,0xac,0xac,0xac,0xac,0xac,0xac,0xac,0xac";
BA_ "GenMsgILSupport" BO_ 278 1;
BA_ "GenMsgCycleTime" BO_ 278 20;
BA_ "GenMsgChkConstant" BO_ 278 172;
BA_ "GenMsgSendType" BO_ 418 0;
BA_ "GenMsgPDUConstants" BO_ 418 "0xcb,0x47,0xd7,0xd2,0x56,0x3e,0x20,0xea,0x6e,0x6d,0x8c,0x1b,0xdf,0x49,0xaa,0xab";
BA_ "GenMsgILSupport" BO_ 418 1;
BA_ "GenMsgDelayTime" BO_ 418 20;
BA_ "GenMsgCycleTime" BO_ 418 200;
BA_ "GenMsgSendType" BO_ 1629 0;
BA_ "GenMsgPDUConstants" BO_ 1629 "0xac,0xb3,0xab,0xeb,0x7a,0xe1,0x3b,0xf7,0x73,0xba,0x7c,0x9e,0x06,0x5f,0x02,0xd9";
BA_ "GenMsgILSupport" BO_ 1629 1;
BA_ "GenMsgCycleTime" BO_ 1629 1000;
BA_ "GenMsgSendType" BO_ 253 0;
BA_ "GenMsgPDUConstants" BO_ 253 "0xb4,0xef,0xf8,0x49,0x1e,0xe5,0xc2,0xc0,0x97,0x19,0x3c,0xc9,0xf1,0x98,0xd6,0x61";
BA_ "GenMsgILSupport" BO_ 253 1;
BA_ "GenMsgCycleTime" BO_ 253 20;
BA_ "GenMsgSendType" BO_ 795 0;
BA_ "GenMsgPDUConstants" BO_ 795 "0x67,0x8a,0xae,0x22,0x4d,0xd0,0x51,0x80,0x5c,0xb9,0xce,0x1e,0xdf,0x02,0x2d,0xd4";
BA_ "GenMsgILSupport" BO_ 795 1;
BA_ "GenMsgCycleTime" BO_ 795 1000;
BA_ "GenMsgSendType" BO_ 508 0;
BA_ "GenMsgPDUConstants" BO_ 508 "0x01,0x10,0x05,0xde,0xe0,0xdc,0x34,0xc4,0x8a,0xb1,0x6d,0x7b,0x62,0xef,0x1f,0x95";
BA_ "GenMsgILSupport" BO_ 508 1;
BA_ "GenMsgCycleTime" BO_ 508 100;
BA_ "GenMsgSendType" BO_ 427 0;
BA_ "GenMsgPDUConstants" BO_ 427 "0x13,0x21,0x9b,0x6a,0x9a,0x62,0xd4,0x65,0x18,0xf1,0xab,0x16,0x32,0x89,0xe7,0x26";
BA_ "GenMsgILSupport" BO_ 427 1;
BA_ "GenMsgDelayTime" BO_ 427 20;
BA_ "GenMsgCycleTime" BO_ 427 200;
BA_ "GenMsgSendType" BO_ 2589283470 0;
BA_ "GenMsgILSupport" BO_ 2589283470 1;
BA_ "GenMsgCycleTime" BO_ 2589283470 960;
BA_ "GenMsgSendType" BO_ 264 0;
BA_ "GenMsgPDUConstants" BO_ 264 "0x09,0x09,0x09,0x09,0x09,0x09,0x09,0x09,0x09,0x09,0x09,0x09,0x09,0x09,0x09,0x09";
BA_ "GenMsgILSupport" BO_ 264 1;
BA_ "GenMsgCycleTime" BO_ 264 20;
BA_ "GenMsgChkConstant" BO_ 264 9;
BA_ "GenMsgSendType" BO_ 429 0;
BA_ "GenMsgPDUConstants" BO_ 429 "0x40,0x7a,0x23,0x13,0x03,0xf4,0xf8,0xe5,0x97,0xc9,0xd6,0x07,0x47,0x21,0x66,0xdd";
BA_ "GenMsgILSupport" BO_ 429 1;
BA_ "GenMsgDelayTime" BO_ 429 40;
BA_ "GenMsgCycleTime" BO_ 429 1000;
BA_ "GenMsgSendType" BO_ 1605 0;
BA_ "GenMsgILSupport" BO_ 1605 1;
BA_ "GenMsgDelayTime" BO_ 1605 20;
BA_ "GenMsgCycleTime" BO_ 1605 1000;
BA_ "GenMsgSendType" BO_ 1726 7;
BA_ "GenMsgNrOfRepetition" BO_ 1726 5;
BA_ "GenMsgILSupport" BO_ 1726 1;
BA_ "GenMsgCycleTimeFast" BO_ 1726 500;
BA_ "GenMsgSendType" BO_ 1727 7;
BA_ "GenMsgNrOfRepetition" BO_ 1727 5;
BA_ "GenMsgILSupport" BO_ 1727 1;
BA_ "GenMsgCycleTimeFast" BO_ 1727 500;
BA_ "GenMsgSendType" BO_ 173 0;
BA_ "GenMsgPDUConstants" BO_ 173 "0x3f,0x69,0x39,0xdc,0x94,0xf9,0x14,0x64,0xd8,0x6a,0x34,0xce,0xa2,0x55,0xb5,0x2c";
BA_ "GenMsgILSupport" BO_ 173 1;
BA_ "GenMsgDelayTime" BO_ 173 10;
BA_ "GenMsgCycleTime" BO_ 173 100;
BA_ "GenMsgSendType" BO_ 968 0;
BA_ "GenMsgILSupport" BO_ 968 1;
BA_ "GenMsgDelayTime" BO_ 968 20;
BA_ "GenMsgCycleTime" BO_ 968 80;
BA_ "GenMsgSendType" BO_ 310 0;
BA_ "GenMsgPDUConstants" BO_ 310 "0x37,0x37,0x37,0x37,0x37,0x37,0x37,0x37,0x37,0x37,0x37,0x37,0x37,0x37,0x37,0x37";
BA_ "GenMsgILSupport" BO_ 310 1;
BA_ "GenMsgCycleTime" BO_ 310 10;
BA_ "GenMsgChkConstant" BO_ 310 55;
BA_ "GenMsgSendType" BO_ 676 0;
BA_ "GenMsgPDUConstants" BO_ 676 "0x42,0x54,0xd5,0x29,0xcc,0x16,0x4d,0xa8,0xd4,0xed,0x7c,0x21,0xdb,0x6b,0xe6,0x5a";
BA_ "GenMsgILSupport" BO_ 676 1;
BA_ "GenMsgCycleTime" BO_ 676 40;
BA_ "GenMsgSendType" BO_ 1410 0;
BA_ "GenMsgILSupport" BO_ 1410 1;
BA_ "GenMsgDelayTime" BO_ 1410 20;
BA_ "GenMsgCycleTime" BO_ 1410 200;
BA_ "GenMsgSendType" BO_ 1416 0;
BA_ "GenMsgILSupport" BO_ 1416 1;
BA_ "GenMsgDelayTime" BO_ 1416 50;
BA_ "GenMsgCycleTime" BO_ 1416 500;
BA_ "GenMsgSendType" BO_ 1016 0;
BA_ "GenMsgILSupport" BO_ 1016 1;
BA_ "GenMsgDelayTime" BO_ 1016 50;
BA_ "GenMsgCycleTime" BO_ 1016 500;
BA_ "GenMsgSendType" BO_ 1412 0;
BA_ "GenMsgPDUConstants" BO_ 1412 "0x7f,0x7f,0x7f,0x7f,0x7f,0x7f,0x7f,0x7f,0x7f,0x7f,0x7f,0x7f,0x7f,0x7f,0x7f,0x7f";
BA_ "GenMsgILSupport" BO_ 1412 1;
BA_ "GenMsgCycleTime" BO_ 1412 160;
BA_ "GenMsgChkConstant" BO_ 1412 127;
BA_ "GenMsgSendType" BO_ 1283 0;
BA_ "GenMsgPDUConstants" BO_ 1283 "0xed,0xd6,0x96,0x63,0xa5,0x12,0xd5,0x9a,0x1e,0x0d,0x24,0xcd,0x8c,0xa6,0x2f,0x41";
BA_ "GenMsgILSupport" BO_ 1283 1;
BA_ "GenMsgDelayTime" BO_ 1283 10;
BA_ "GenMsgCycleTime" BO_ 1283 100;
BA_ "GenSigSwitchedByIgnition" SG_ 262 ESP_05_CRC 0;
BA_ "GenSigFuncType" SG_ 262 ESP_05_CRC 2;
BA_ "GenSigSendType" SG_ 262 ESP_05_CRC 0;
BA_ "GenSigSwitchedByIgnition" SG_ 262 ESP_05_BZ 0;
BA_ "GenSigFuncType" SG_ 262 ESP_05_BZ 1;
BA_ "GenSigSendType" SG_ 262 ESP_05_BZ 0;
BA_ "GenSigSwitchedByIgnition" SG_ 262 ESP_QBit_Bremsdruck 0;
BA_ "GenSigStartValue" SG_ 262 ESP_QBit_Bremsdruck 1;
BA_ "GenSigSendType" SG_ 262 ESP_QBit_Bremsdruck 0;
BA_ "GenSigSwitchedByIgnition" SG_ 262 ESP_QBit_Fahrer_bremst 0;
BA_ "GenSigStartValue" SG_ 262 ESP_QBit_Fahrer_bremst 1;
BA_ "GenSigSendType" SG_ 262 ESP_QBit_Fahrer_bremst 0;
BA_ "GenSigSwitchedByIgnition" SG_ 262 ESP_Schwelle_Unterdruck 0;
BA_ "GenSigSendType" SG_ 262 ESP_Schwelle_Unterdruck 0;
BA_ "Fehlerwert" SG_ 262 ESP_Bremsdruck 1023;
BA_ "GenSigSwitchedByIgnition" SG_ 262 ESP_Bremsdruck 0;
BA_ "GenSigStartValue" SG_ 262 ESP_Bremsdruck 100;
BA_ "GenSigSendType" SG_ 262 ESP_Bremsdruck 0;
BA_ "GenSigSwitchedByIgnition" SG_ 262 ESP_Fahrer_bremst 0;
BA_ "GenSigSendType" SG_ 262 ESP_Fahrer_bremst 0;
BA_ "GenSigSwitchedByIgnition" SG_ 262 ESP_Lenkeingriff_ADS 0;
BA_ "GenSigSendType" SG_ 262 ESP_Lenkeingriff_ADS 0;
BA_ "GenSigSwitchedByIgnition" SG_ 262 ECD_Fehler 0;
BA_ "GenSigSendType" SG_ 262 ECD_Fehler 0;
BA_ "GenSigSwitchedByIgnition" SG_ 262 ECD_nicht_verfuegbar 0;
BA_ "GenSigStartValue" SG_ 262 ECD_nicht_verfuegbar 1;
BA_ "GenSigSendType" SG_ 262 ECD_nicht_verfuegbar 0;
BA_ "GenSigSwitchedByIgnition" SG_ 262 ESP_Status_Bremsentemp 0;
BA_ "GenSigSendType" SG_ 262 ESP_Status_Bremsentemp 0;
BA_ "GenSigSwitchedByIgnition" SG_ 262 ESP_Autohold_Standby 0;
BA_ "GenSigSendType" SG_ 262 ESP_Autohold_Standby 0;
BA_ "GenSigSwitchedByIgnition" SG_ 262 ESP_HDC_Standby 0;
BA_ "GenSigSendType" SG_ 262 ESP_HDC_Standby 0;
BA_ "GenSigSwitchedByIgnition" SG_ 262 ESP_HBA_aktiv 0;
BA_ "GenSigSendType" SG_ 262 ESP_HBA_aktiv 0;
BA_ "GenSigSwitchedByIgnition" SG_ 262 ESP_Prefill_ausgeloest 0;
BA_ "GenSigSendType" SG_ 262 ESP_Prefill_ausgeloest 0;
BA_ "GenSigSwitchedByIgnition" SG_ 262 ESP_Rueckwaertsfahrt_erkannt 0;
BA_ "GenSigSendType" SG_ 262 ESP_Rueckwaertsfahrt_erkannt 0;
BA_ "GenSigSwitchedByIgnition" SG_ 262 ESP_Status_Anfahrhilfe 0;
BA_ "GenSigSendType" SG_ 262 ESP_Status_Anfahrhilfe 0;
BA_ "GenSigSwitchedByIgnition" SG_ 262 ESP_HDC_aktiv 0;
BA_ "GenSigSendType" SG_ 262 ESP_HDC_aktiv 0;
BA_ "GenSigSwitchedByIgnition" SG_ 262 ESP_StartStopp_Info 0;
BA_ "GenSigSendType" SG_ 262 ESP_StartStopp_Info 0;
BA_ "GenSigSwitchedByIgnition" SG_ 262 ESP_Eingr_HL 0;
BA_ "GenSigSendType" SG_ 262 ESP_Eingr_HL 0;
BA_ "GenSigSwitchedByIgnition" SG_ 262 ESP_Eingr_HR 0;
BA_ "GenSigSendType" SG_ 262 ESP_Eingr_HR 0;
BA_ "GenSigSwitchedByIgnition" SG_ 262 ESP_Eingr_VL 0;
BA_ "GenSigSendType" SG_ 262 ESP_Eingr_VL 0;
BA_ "GenSigSwitchedByIgnition" SG_ 262 ESP_Eingr_VR 0;
BA_ "GenSigSendType" SG_ 262 ESP_Eingr_VR 0;
BA_ "Fehlerwert" SG_ 262 ESP_BKV_Unterdruck 255;
BA_ "GenSigSwitchedByIgnition" SG_ 262 ESP_BKV_Unterdruck 0;
BA_ "GenSigStartValue" SG_ 262 ESP_BKV_Unterdruck 254;
BA_ "GenSigSendType" SG_ 262 ESP_BKV_Unterdruck 0;
BA_ "GenSigSwitchedByIgnition" SG_ 262 ESP_Autohold_aktiv 0;
BA_ "GenSigSendType" SG_ 262 ESP_Autohold_aktiv 0;
BA_ "Fehlerwert" SG_ 262 ESP_FStatus_Anfahrhilfe 1;
BA_ "GenSigSwitchedByIgnition" SG_ 262 ESP_FStatus_Anfahrhilfe 0;
BA_ "GenSigSendType" SG_ 262 ESP_FStatus_Anfahrhilfe 0;
BA_ "GenSigSwitchedByIgnition" SG_ 262 ESP_Verz_EPB_aktiv 0;
BA_ "GenSigSendType" SG_ 262 ESP_Verz_EPB_aktiv 0;
BA_ "GenSigSwitchedByIgnition" SG_ 262 ESC_Bremslicht 0;
BA_ "GenSigSendType" SG_ 262 ESC_Bremslicht 0;
BA_ "GenSigSwitchedByIgnition" SG_ 262 ESP_Verzoeg_EPB_verf 0;
BA_ "GenSigSendType" SG_ 262 ESP_Verzoeg_EPB_verf 0;
BA_ "GenSigSwitchedByIgnition" SG_ 262 ESP_Status_Bremsdruck 0;
BA_ "GenSigSendType" SG_ 262 ESP_Status_Bremsdruck 0;
BA_ "GenSigSwitchedByIgnition" SG_ 262 ESP_Anforderung_EPB 0;
BA_ "GenSigSendType" SG_ 262 ESP_Anforderung_EPB 0;
BA_ "GenSigSwitchedByIgnition" SG_ 914 ESP_07_CRC 0;
BA_ "GenSigFuncType" SG_ 914 ESP_07_CRC 2;
BA_ "GenSigSendType" SG_ 914 ESP_07_CRC 0;
BA_ "GenSigSwitchedByIgnition" SG_ 914 ESP_07_BZ 0;
BA_ "GenSigFuncType" SG_ 914 ESP_07_BZ 1;
BA_ "GenSigSendType" SG_ 914 ESP_07_BZ 0;
BA_ "GenSigSwitchedByIgnition" SG_ 914 ESP_ACC_LDE 0;
BA_ "GenSigSendType" SG_ 914 ESP_ACC_LDE 0;
BA_ "GenSigSwitchedByIgnition" SG_ 914 ESP_Allrad_Antrieb 0;
BA_ "GenSigFuncType" SG_ 914 ESP_Allrad_Antrieb 8;
BA_ "GenSigSendType" SG_ 914 ESP_Allrad_Antrieb 0;
BA_ "GenSigSwitchedByIgnition" SG_ 914 ESP_Codierung_ADS 0;
BA_ "GenSigFuncType" SG_ 914 ESP_Codierung_ADS 8;
BA_ "GenSigSendType" SG_ 914 ESP_Codierung_ADS 0;
BA_ "Fehlerwert" SG_ 914 ESP_RTA_HL 255;
BA_ "GenSigSwitchedByIgnition" SG_ 914 ESP_RTA_HL 0;
BA_ "GenSigStartValue" SG_ 914 ESP_RTA_HL 254;
BA_ "GenSigSendType" SG_ 914 ESP_RTA_HL 0;
BA_ "Fehlerwert" SG_ 914 ESP_RTA_HR 255;
BA_ "GenSigSwitchedByIgnition" SG_ 914 ESP_RTA_HR 0;
BA_ "GenSigStartValue" SG_ 914 ESP_RTA_HR 254;
BA_ "GenSigSendType" SG_ 914 ESP_RTA_HR 0;
BA_ "Fehlerwert" SG_ 914 ESP_RTA_VR 255;
BA_ "GenSigSwitchedByIgnition" SG_ 914 ESP_RTA_VR 0;
BA_ "GenSigStartValue" SG_ 914 ESP_RTA_VR 254;
BA_ "GenSigSendType" SG_ 914 ESP_RTA_VR 0;
BA_ "GenSigSwitchedByIgnition" SG_ 914 OBD_Fehler_Radsensor_HL 0;
BA_ "GenSigSendType" SG_ 914 OBD_Fehler_Radsensor_HL 0;
BA_ "GenSigSwitchedByIgnition" SG_ 914 OBD_Fehler_Radsensor_HR 0;
BA_ "GenSigSendType" SG_ 914 OBD_Fehler_Radsensor_HR 0;
BA_ "GenSigSwitchedByIgnition" SG_ 914 OBD_Fehler_Radsensor_VL 0;
BA_ "GenSigSendType" SG_ 914 OBD_Fehler_Radsensor_VL 0;
BA_ "GenSigSwitchedByIgnition" SG_ 914 OBD_Fehler_Radsensor_VR 0;
BA_ "GenSigSendType" SG_ 914 OBD_Fehler_Radsensor_VR 0;
BA_ "GenSigSwitchedByIgnition" SG_ 914 ESP_Qualifizierung_Antriebsart 0;
BA_ "GenSigFuncType" SG_ 914 ESP_Qualifizierung_Antriebsart 8;
BA_ "GenSigSendType" SG_ 914 ESP_Qualifizierung_Antriebsart 0;
BA_ "GenSigSwitchedByIgnition" SG_ 914 ESP_Offroad_Modus 0;
BA_ "GenSigSendType" SG_ 914 ESP_Offroad_Modus 0;
BA_ "GenSigSwitchedByIgnition" SG_ 914 ESP_MKB_ausloesbar 0;
BA_ "GenSigSendType" SG_ 914 ESP_MKB_ausloesbar 0;
BA_ "GenSigSwitchedByIgnition" SG_ 914 ESP_Stat_FallBack_eBKV 0;
BA_ "GenSigSendType" SG_ 914 ESP_Stat_FallBack_eBKV 0;
BA_ "GenSigSwitchedByIgnition" SG_ 914 ESP_CM_Variante 0;
BA_ "GenSigSendType" SG_ 914 ESP_CM_Variante 0;
BA_ "GenSigSwitchedByIgnition" SG_ 914 ESP_OBD_Status 0;
BA_ "GenSigSendType" SG_ 914 ESP_OBD_Status 0;
BA_ "GenSigSwitchedByIgnition" SG_ 914 ESP_Rollenmodus_Deaktivieren 0;
BA_ "GenSigSendType" SG_ 914 ESP_Rollenmodus_Deaktivieren 0;
BA_ "GenSigSwitchedByIgnition" SG_ 914 ESP_nachtr_Stopp_Anf 0;
BA_ "GenSigSendType" SG_ 914 ESP_nachtr_Stopp_Anf 0;
BA_ "GenSigSwitchedByIgnition" SG_ 278 ESP_10_CRC 0;
BA_ "GenSigFuncType" SG_ 278 ESP_10_CRC 2;
BA_ "GenSigSendType" SG_ 278 ESP_10_CRC 0;
BA_ "GenSigSwitchedByIgnition" SG_ 278 ESP_10_BZ 0;
BA_ "GenSigFuncType" SG_ 278 ESP_10_BZ 1;
BA_ "GenSigSendType" SG_ 278 ESP_10_BZ 0;
BA_ "GenSigSwitchedByIgnition" SG_ 278 ESP_QBit_Wegimpuls_VL 0;
BA_ "GenSigStartValue" SG_ 278 ESP_QBit_Wegimpuls_VL 1;
BA_ "GenSigSendType" SG_ 278 ESP_QBit_Wegimpuls_VL 0;
BA_ "GenSigSwitchedByIgnition" SG_ 278 ESP_QBit_Wegimpuls_VR 0;
BA_ "GenSigStartValue" SG_ 278 ESP_QBit_Wegimpuls_VR 1;
BA_ "GenSigSendType" SG_ 278 ESP_QBit_Wegimpuls_VR 0;
BA_ "GenSigSwitchedByIgnition" SG_ 278 ESP_QBit_Wegimpuls_HL 0;
BA_ "GenSigStartValue" SG_ 278 ESP_QBit_Wegimpuls_HL 1;
BA_ "GenSigSendType" SG_ 278 ESP_QBit_Wegimpuls_HL 0;
BA_ "GenSigSwitchedByIgnition" SG_ 278 ESP_QBit_Wegimpuls_HR 0;
BA_ "GenSigStartValue" SG_ 278 ESP_QBit_Wegimpuls_HR 1;
BA_ "GenSigSendType" SG_ 278 ESP_QBit_Wegimpuls_HR 0;
BA_ "Fehlerwert" SG_ 278 ESP_Wegimpuls_VL 1023;
BA_ "GenSigSwitchedByIgnition" SG_ 278 ESP_Wegimpuls_VL 0;
BA_ "GenSigStartValue" SG_ 278 ESP_Wegimpuls_VL 1021;
BA_ "GenSigSendType" SG_ 278 ESP_Wegimpuls_VL 0;
BA_ "Fehlerwert" SG_ 278 ESP_Wegimpuls_VR 1023;
BA_ "GenSigSwitchedByIgnition" SG_ 278 ESP_Wegimpuls_VR 0;
BA_ "GenSigStartValue" SG_ 278 ESP_Wegimpuls_VR 1021;
BA_ "GenSigSendType" SG_ 278 ESP_Wegimpuls_VR 0;
BA_ "Fehlerwert" SG_ 278 ESP_Wegimpuls_HL 1023;
BA_ "GenSigSwitchedByIgnition" SG_ 278 ESP_Wegimpuls_HL 0;
BA_ "GenSigStartValue" SG_ 278 ESP_Wegimpuls_HL 1021;
BA_ "GenSigSendType" SG_ 278 ESP_Wegimpuls_HL 0;
BA_ "Fehlerwert" SG_ 278 ESP_Wegimpuls_HR 1023;
BA_ "GenSigSwitchedByIgnition" SG_ 278 ESP_Wegimpuls_HR 0;
BA_ "GenSigStartValue" SG_ 278 ESP_Wegimpuls_HR 1021;
BA_ "GenSigSendType" SG_ 278 ESP_Wegimpuls_HR 0;
BA_ "GenSigSwitchedByIgnition" SG_ 278 ESP_VL_Fahrtrichtung 0;
BA_ "GenSigStartValue" SG_ 278 ESP_VL_Fahrtrichtung 2;
BA_ "GenSigSendType" SG_ 278 ESP_VL_Fahrtrichtung 0;
BA_ "GenSigSwitchedByIgnition" SG_ 278 ESP_VR_Fahrtrichtung 0;
BA_ "GenSigStartValue" SG_ 278 ESP_VR_Fahrtrichtung 2;
BA_ "GenSigSendType" SG_ 278 ESP_VR_Fahrtrichtung 0;
BA_ "GenSigSwitchedByIgnition" SG_ 278 ESP_HL_Fahrtrichtung 0;
BA_ "GenSigStartValue" SG_ 278 ESP_HL_Fahrtrichtung 2;
BA_ "GenSigSendType" SG_ 278 ESP_HL_Fahrtrichtung 0;
BA_ "GenSigSwitchedByIgnition" SG_ 278 ESP_HR_Fahrtrichtung 0;
BA_ "GenSigStartValue" SG_ 278 ESP_HR_Fahrtrichtung 2;
BA_ "GenSigSendType" SG_ 278 ESP_HR_Fahrtrichtung 0;
BA_ "GenSigSwitchedByIgnition" SG_ 418 ESP_15_CRC 0;
BA_ "GenSigFuncType" SG_ 418 ESP_15_CRC 2;
BA_ "GenSigSendType" SG_ 418 ESP_15_CRC 0;
BA_ "GenSigSwitchedByIgnition" SG_ 418 ESP_15_BZ 0;
BA_ "GenSigFuncType" SG_ 418 ESP_15_BZ 1;
BA_ "GenSigSendType" SG_ 418 ESP_15_BZ 0;
BA_ "Fehlerwert" SG_ 418 HMS_P_beibehalten_GE 3;
BA_ "GenSigSwitchedByIgnition" SG_ 418 HMS_P_beibehalten_GE 0;
BA_ "GenSigStartValue" SG_ 418 HMS_P_beibehalten_GE 2;
BA_ "GenSigSendType" SG_ 418 HMS_P_beibehalten_GE 0;
BA_ "GenSigSwitchedByIgnition" SG_ 418 HMS_Konsistenz_GE 0;
BA_ "GenSigSendType" SG_ 418 HMS_Konsistenz_GE 0;
BA_ "GenSigSwitchedByIgnition" SG_ 418 HMS_Konsistenz_IPA 0;
BA_ "GenSigSendType" SG_ 418 HMS_Konsistenz_IPA 0;
BA_ "GenSigSwitchedByIgnition" SG_ 418 HMS_Konsistenz_EBKV 0;
BA_ "GenSigSendType" SG_ 418 HMS_Konsistenz_EBKV 0;
BA_ "GenSigSwitchedByIgnition" SG_ 418 HMS_Konsistenz_RCTA 0;
BA_ "GenSigSendType" SG_ 418 HMS_Konsistenz_RCTA 3;
BA_ "GenSigSwitchedByIgnition" SG_ 418 HMS_Konsistenz_STA 0;
BA_ "GenSigSendType" SG_ 418 HMS_Konsistenz_STA 0;
BA_ "GenSigSwitchedByIgnition" SG_ 418 HMS_Konsistenz_MO 0;
BA_ "GenSigSendType" SG_ 418 HMS_Konsistenz_MO 0;
BA_ "GenSigSwitchedByIgnition" SG_ 418 HMS_halten_nicht_verfuegbar 0;
BA_ "GenSigSendType" SG_ 418 HMS_halten_nicht_verfuegbar 0;
BA_ "GenSigSwitchedByIgnition" SG_ 418 HMS_parken_nicht_verfuegbar 0;
BA_ "GenSigSendType" SG_ 418 HMS_parken_nicht_verfuegbar 0;
BA_ "GenSigSwitchedByIgnition" SG_ 418 HMS_Anforderung_GE 0;
BA_ "GenSigSendType" SG_ 418 HMS_Anforderung_GE 0;
BA_ "Fehlerwert" SG_ 418 HMS_Systemstatus 15;
BA_ "GenSigSwitchedByIgnition" SG_ 418 HMS_Systemstatus 0;
BA_ "GenSigStartValue" SG_ 418 HMS_Systemstatus 14;
BA_ "GenSigSendType" SG_ 418 HMS_Systemstatus 3;
BA_ "Fehlerwert" SG_ 418 HMS_Stillstand 7;
BA_ "GenSigSwitchedByIgnition" SG_ 418 HMS_Stillstand 0;
BA_ "GenSigStartValue" SG_ 418 HMS_Stillstand 6;
BA_ "GenSigSendType" SG_ 418 HMS_Stillstand 3;
BA_ "GenSigSwitchedByIgnition" SG_ 418 HMS_aktives_System 0;
BA_ "GenSigSendType" SG_ 418 HMS_aktives_System 3;
BA_ "GenSigSwitchedByIgnition" SG_ 418 HMS_Konsistenz_HVLM 0;
BA_ "GenSigSendType" SG_ 418 HMS_Konsistenz_HVLM 3;
BA_ "GenSigSwitchedByIgnition" SG_ 418 HMS_Konsistenz_ACC 0;
BA_ "GenSigSendType" SG_ 418 HMS_Konsistenz_ACC 0;
BA_ "GenSigSwitchedByIgnition" SG_ 418 HMS_Fehlerstatus 0;
BA_ "GenSigSendType" SG_ 418 HMS_Fehlerstatus 3;
BA_ "GenSigSwitchedByIgnition" SG_ 418 ESP_Index_Haltemoment 0;
BA_ "GenSigSendType" SG_ 418 ESP_Index_Haltemoment 0;
BA_ "Fehlerwert" SG_ 418 ESP_Haltemoment 1023;
BA_ "GenSigSwitchedByIgnition" SG_ 418 ESP_Haltemoment 0;
BA_ "GenSigStartValue" SG_ 418 ESP_Haltemoment 1022;
BA_ "GenSigSendType" SG_ 418 ESP_Haltemoment 0;
BA_ "GenSigSwitchedByIgnition" SG_ 1629 ESP_20_CRC 0;
BA_ "GenSigFuncType" SG_ 1629 ESP_20_CRC 2;
BA_ "GenSigSendType" SG_ 1629 ESP_20_CRC 0;
BA_ "GenSigSwitchedByIgnition" SG_ 1629 ESP_20_BZ 0;
BA_ "GenSigFuncType" SG_ 1629 ESP_20_BZ 1;
BA_ "GenSigSendType" SG_ 1629 ESP_20_BZ 0;
BA_ "GenSigSwitchedByIgnition" SG_ 1629 BR_Systemart 0;
BA_ "GenSigFuncType" SG_ 1629 BR_Systemart 8;
BA_ "GenSigSendType" SG_ 1629 BR_Systemart 0;
BA_ "GenSigSwitchedByIgnition" SG_ 1629 ESP_SpannungsAnf_02 0;
BA_ "GenSigSendType" SG_ 1629 ESP_SpannungsAnf_02 0;
BA_ "GenSigSwitchedByIgnition" SG_ 1629 ESP_Zaehnezahl 0;
BA_ "GenSigFuncType" SG_ 1629 ESP_Zaehnezahl 8;
BA_ "GenSigSendType" SG_ 1629 ESP_Zaehnezahl 0;
BA_ "GenSigSwitchedByIgnition" SG_ 1629 ESP_Charisma_FahrPr 0;
BA_ "GenSigSendType" SG_ 1629 ESP_Charisma_FahrPr 0;
BA_ "GenSigSwitchedByIgnition" SG_ 1629 ESP_Charisma_Status 0;
BA_ "GenSigSendType" SG_ 1629 ESP_Charisma_Status 0;
BA_ "GenSigSwitchedByIgnition" SG_ 1629 ESP_Wiederstart_Anz_01 0;
BA_ "GenSigSendType" SG_ 1629 ESP_Wiederstart_Anz_01 0;
BA_ "GenSigSwitchedByIgnition" SG_ 1629 ESP_Wiederstart_Anz_02 0;
BA_ "GenSigSendType" SG_ 1629 ESP_Wiederstart_Anz_02 0;
BA_ "GenSigSwitchedByIgnition" SG_ 1629 ESP_Wiederstart_Anz_03 0;
BA_ "GenSigSendType" SG_ 1629 ESP_Wiederstart_Anz_03 0;
BA_ "GenSigSwitchedByIgnition" SG_ 1629 ESP_Wiederstart_Anz_04 0;
BA_ "GenSigSendType" SG_ 1629 ESP_Wiederstart_Anz_04 0;
BA_ "GenSigSwitchedByIgnition" SG_ 1629 ESP_Stoppverbot_Anz_01 0;
BA_ "GenSigSendType" SG_ 1629 ESP_Stoppverbot_Anz_01 0;
BA_ "GenSigSwitchedByIgnition" SG_ 1629 ESP_Stoppverbot_Anz_02 0;
BA_ "GenSigSendType" SG_ 1629 ESP_Stoppverbot_Anz_02 0;
BA_ "GenSigSwitchedByIgnition" SG_ 1629 ESP_Stoppverbot_Anz_03 0;
BA_ "GenSigSendType" SG_ 1629 ESP_Stoppverbot_Anz_03 0;
BA_ "GenSigSwitchedByIgnition" SG_ 1629 ESP_Stoppverbot_Anz_04 0;
BA_ "GenSigSendType" SG_ 1629 ESP_Stoppverbot_Anz_04 0;
BA_ "GenSigSwitchedByIgnition" SG_ 1629 ESP_Stoppverbot_Anz_05 0;
BA_ "GenSigSendType" SG_ 1629 ESP_Stoppverbot_Anz_05 0;
BA_ "GenSigSwitchedByIgnition" SG_ 1629 ESP_Stoppverbot_Anz_06 0;
BA_ "GenSigSendType" SG_ 1629 ESP_Stoppverbot_Anz_06 0;
BA_ "GenSigSwitchedByIgnition" SG_ 1629 ESP_Stoppverbot_Anz_07 0;
BA_ "GenSigSendType" SG_ 1629 ESP_Stoppverbot_Anz_07 0;
BA_ "GenSigSwitchedByIgnition" SG_ 1629 ESP_Stoppverbot_Anz_Std 0;
BA_ "GenSigSendType" SG_ 1629 ESP_Stoppverbot_Anz_Std 0;
BA_ "Fehlerwert" SG_ 1629 ESP_Dachrelingsensor 3;
BA_ "GenSigSwitchedByIgnition" SG_ 1629 ESP_Dachrelingsensor 0;
BA_ "GenSigSendType" SG_ 1629 ESP_Dachrelingsensor 0;
BA_ "GenSigSwitchedByIgnition" SG_ 1629 ESP_Stoppverbot_Anz_08 0;
BA_ "GenSigSendType" SG_ 1629 ESP_Stoppverbot_Anz_08 0;
BA_ "GenSigSwitchedByIgnition" SG_ 1629 HDC_Charisma_FahrPr 0;
BA_ "GenSigSendType" SG_ 1629 HDC_Charisma_FahrPr 0;
BA_ "GenSigSwitchedByIgnition" SG_ 1629 HDC_Charisma_Status 0;
BA_ "GenSigSendType" SG_ 1629 HDC_Charisma_Status 0;
BA_ "GenSigSwitchedByIgnition" SG_ 1629 BR_QBit_Reifenumfang 0;
BA_ "GenSigStartValue" SG_ 1629 BR_QBit_Reifenumfang 1;
BA_ "GenSigSendType" SG_ 1629 BR_QBit_Reifenumfang 0;
BA_ "GenSigSwitchedByIgnition" SG_ 1629 BR_Reifenumfang 0;
BA_ "GenSigSendType" SG_ 1629 BR_Reifenumfang 0;
BA_ "GenSigSwitchedByIgnition" SG_ 253 ESP_21_CRC 0;
BA_ "GenSigFuncType" SG_ 253 ESP_21_CRC 2;
BA_ "GenSigSendType" SG_ 253 ESP_21_CRC 0;
BA_ "GenSigSwitchedByIgnition" SG_ 253 ESP_21_BZ 0;
BA_ "GenSigFuncType" SG_ 253 ESP_21_BZ 1;
BA_ "GenSigSendType" SG_ 253 ESP_21_BZ 0;
BA_ "Fehlerwert" SG_ 253 BR_Eingriffsmoment 1023;
BA_ "GenSigSwitchedByIgnition" SG_ 253 BR_Eingriffsmoment 0;
BA_ "GenSigStartValue" SG_ 253 BR_Eingriffsmoment 1022;
BA_ "GenSigSendType" SG_ 253 BR_Eingriffsmoment 0;
BA_ "GenSigSwitchedByIgnition" SG_ 253 ESP_PLA_Bremseingriff 0;
BA_ "GenSigSendType" SG_ 253 ESP_PLA_Bremseingriff 0;
BA_ "GenSigSwitchedByIgnition" SG_ 253 ESP_Diagnose 0;
BA_ "GenSigSendType" SG_ 253 ESP_Diagnose 0;
BA_ "Fehlerwert" SG_ 253 ESC_v_Signal_Qualifier_High_Low 7;
BA_ "GenSigSwitchedByIgnition" SG_ 253 ESC_v_Signal_Qualifier_High_Low 0;
BA_ "GenSigStartValue" SG_ 253 ESC_v_Signal_Qualifier_High_Low 6;
BA_ "GenSigSendType" SG_ 253 ESC_v_Signal_Qualifier_High_Low 0;
BA_ "GenSigSwitchedByIgnition" SG_ 253 ESP_Vorsteuerung 0;
BA_ "GenSigSendType" SG_ 253 ESP_Vorsteuerung 0;
BA_ "GenSigSwitchedByIgnition" SG_ 253 OBD_Schlechtweg 0;
BA_ "GenSigSendType" SG_ 253 OBD_Schlechtweg 0;
BA_ "GenSigSwitchedByIgnition" SG_ 253 OBD_QBit_Schlechtweg 0;
BA_ "GenSigStartValue" SG_ 253 OBD_QBit_Schlechtweg 1;
BA_ "GenSigSendType" SG_ 253 OBD_QBit_Schlechtweg 0;
BA_ "GenSigMissingSourceValue" SG_ 253 ESP_v_Signal 65534;
BA_ "Fehlerwert" SG_ 253 ESP_v_Signal 65535;
BA_ "GenSigSwitchedByIgnition" SG_ 253 ESP_v_Signal 0;
BA_ "GenSigStartValue" SG_ 253 ESP_v_Signal 65534;
BA_ "GenSigSendType" SG_ 253 ESP_v_Signal 0;
BA_ "GenSigSwitchedByIgnition" SG_ 253 ASR_Tastung_passiv 0;
BA_ "GenSigSendType" SG_ 253 ASR_Tastung_passiv 0;
BA_ "GenSigSwitchedByIgnition" SG_ 253 ESP_Tastung_passiv 0;
BA_ "GenSigSendType" SG_ 253 ESP_Tastung_passiv 0;
BA_ "GenSigSwitchedByIgnition" SG_ 253 ESP_Systemstatus 0;
BA_ "GenSigSendType" SG_ 253 ESP_Systemstatus 0;
BA_ "GenSigSwitchedByIgnition" SG_ 253 ASR_Schalteingriff 0;
BA_ "GenSigSendType" SG_ 253 ASR_Schalteingriff 0;
BA_ "GenSigSwitchedByIgnition" SG_ 253 ESP_Haltebestaetigung 0;
BA_ "GenSigSendType" SG_ 253 ESP_Haltebestaetigung 0;
BA_ "GenSigSwitchedByIgnition" SG_ 253 ESP_MKB_Abbruch_Geschw 0;
BA_ "GenSigSendType" SG_ 253 ESP_MKB_Abbruch_Geschw 0;
BA_ "GenSigSwitchedByIgnition" SG_ 253 ESP_QBit_v_Signal 0;
BA_ "GenSigStartValue" SG_ 253 ESP_QBit_v_Signal 1;
BA_ "GenSigSendType" SG_ 253 ESP_QBit_v_Signal 0;
BA_ "GenSigSwitchedByIgnition" SG_ 253 ABS_Bremsung 0;
BA_ "GenSigSendType" SG_ 253 ABS_Bremsung 0;
BA_ "GenSigSwitchedByIgnition" SG_ 253 ASR_Anf 0;
BA_ "GenSigSendType" SG_ 253 ASR_Anf 0;
BA_ "GenSigSwitchedByIgnition" SG_ 253 MSR_Anf 0;
BA_ "GenSigSendType" SG_ 253 MSR_Anf 0;
BA_ "GenSigSwitchedByIgnition" SG_ 253 EBV_Eingriff 0;
BA_ "GenSigSendType" SG_ 253 EBV_Eingriff 0;
BA_ "GenSigSwitchedByIgnition" SG_ 253 EDS_Eingriff 0;
BA_ "GenSigSendType" SG_ 253 EDS_Eingriff 0;
BA_ "GenSigSwitchedByIgnition" SG_ 253 ESP_Eingriff 0;
BA_ "GenSigSendType" SG_ 253 ESP_Eingriff 0;
BA_ "GenSigSwitchedByIgnition" SG_ 253 ESP_ASP 0;
BA_ "GenSigSendType" SG_ 253 ESP_ASP 0;
BA_ "GenSigSwitchedByIgnition" SG_ 795 ESP_24_CRC 0;
BA_ "GenSigFuncType" SG_ 795 ESP_24_CRC 2;
BA_ "GenSigSendType" SG_ 795 ESP_24_CRC 0;
BA_ "GenSigSwitchedByIgnition" SG_ 795 ESP_24_BZ 0;
BA_ "GenSigFuncType" SG_ 795 ESP_24_BZ 1;
BA_ "GenSigSendType" SG_ 795 ESP_24_BZ 0;
BA_ "GenSigSwitchedByIgnition" SG_ 795 ESP_Lampe 0;
BA_ "GenSigStartValue" SG_ 795 ESP_Lampe 1;
BA_ "GenSigSendType" SG_ 795 ESP_Lampe 0;
BA_ "GenSigSwitchedByIgnition" SG_ 795 ABS_Lampe 0;
BA_ "GenSigStartValue" SG_ 795 ABS_Lampe 1;
BA_ "GenSigSendType" SG_ 795 ABS_Lampe 0;
BA_ "GenSigSwitchedByIgnition" SG_ 795 BK_Lampe_02 0;
BA_ "GenSigStartValue" SG_ 795 BK_Lampe_02 1;
BA_ "GenSigSendType" SG_ 795 BK_Lampe_02 0;
BA_ "GenSigSwitchedByIgnition" SG_ 795 TC_Lampe 0;
BA_ "GenSigSendType" SG_ 795 TC_Lampe 0;
BA_ "Fehlerwert" SG_ 795 ESP_m_Raddrehz 32767;
BA_ "GenSigSwitchedByIgnition" SG_ 795 ESP_m_Raddrehz 0;
BA_ "GenSigStartValue" SG_ 795 ESP_m_Raddrehz 32766;
BA_ "GenSigSendType" SG_ 795 ESP_m_Raddrehz 0;
BA_ "GenSigSwitchedByIgnition" SG_ 795 ESP_Textanzeigen_03 0;
BA_ "GenSigSendType" SG_ 795 ESP_Textanzeigen_03 0;
BA_ "GenSigSwitchedByIgnition" SG_ 795 ESP_Meldungen 0;
BA_ "GenSigSendType" SG_ 795 ESP_Meldungen 0;
BA_ "GenSigSwitchedByIgnition" SG_ 795 ESP_Wegimp_VA 0;
BA_ "GenSigSendType" SG_ 795 ESP_Wegimp_VA 0;
BA_ "GenSigSwitchedByIgnition" SG_ 795 ESP_Fehlerstatus_Wegimp 0;
BA_ "GenSigSendType" SG_ 795 ESP_Fehlerstatus_Wegimp 0;
BA_ "GenSigSwitchedByIgnition" SG_ 795 ESP_Wegimp_Ueberlauf 0;
BA_ "GenSigSendType" SG_ 795 ESP_Wegimp_Ueberlauf 0;
BA_ "GenSigSwitchedByIgnition" SG_ 795 ESP_QBit_Wegimp_VA 0;
BA_ "GenSigStartValue" SG_ 795 ESP_QBit_Wegimp_VA 1;
BA_ "GenSigSendType" SG_ 795 ESP_QBit_Wegimp_VA 0;
BA_ "GenSigSwitchedByIgnition" SG_ 795 ESP_HDC_FktLampe 0;
BA_ "GenSigSendType" SG_ 795 ESP_HDC_FktLampe 0;
BA_ "GenSigSwitchedByIgnition" SG_ 795 ESP_Off_Lampe 0;
BA_ "GenSigSendType" SG_ 795 ESP_Off_Lampe 0;
BA_ "Fehlerwert" SG_ 795 ESP_HDC_Regelgeschw 127;
BA_ "GenSigSwitchedByIgnition" SG_ 795 ESP_HDC_Regelgeschw 0;
BA_ "GenSigStartValue" SG_ 795 ESP_HDC_Regelgeschw 126;
BA_ "GenSigSendType" SG_ 795 ESP_HDC_Regelgeschw 0;
BA_ "GenSigSwitchedByIgnition" SG_ 795 ESP_BKV_Warnung 0;
BA_ "GenSigSendType" SG_ 795 ESP_BKV_Warnung 0;
BA_ "GenSigSwitchedByIgnition" SG_ 508 ESP_32_CRC 0;
BA_ "GenSigFuncType" SG_ 508 ESP_32_CRC 2;
BA_ "GenSigSendType" SG_ 508 ESP_32_CRC 0;
BA_ "GenSigSwitchedByIgnition" SG_ 508 ESP_32_BZ 0;
BA_ "GenSigFuncType" SG_ 508 ESP_32_BZ 1;
BA_ "GenSigSendType" SG_ 508 ESP_32_BZ 0;
BA_ "GenSigSwitchedByIgnition" SG_ 508 ESP_Status_Bremsentemp_02 0;
BA_ "GenSigSendType" SG_ 508 ESP_Status_Bremsentemp_02 0;
BA_ "GenSigSwitchedByIgnition" SG_ 508 ESP_Aggregataktivitaet 0;
BA_ "GenSigSendType" SG_ 508 ESP_Aggregataktivitaet 0;
BA_ "GenSigSwitchedByIgnition" SG_ 508 ESP_Stillstandsflag 0;
BA_ "GenSigSendType" SG_ 508 ESP_Stillstandsflag 0;
BA_ "GenSigSwitchedByIgnition" SG_ 508 ESC_FBA_Meldungen 0;
BA_ "GenSigSendType" SG_ 508 ESC_FBA_Meldungen 0;
BA_ "GenSigSwitchedByIgnition" SG_ 508 ESP_Rollover_Status_dyn 0;
BA_ "GenSigSendType" SG_ 508 ESP_Rollover_Status_dyn 0;
BA_ "GenSigSwitchedByIgnition" SG_ 508 ESP_Rollover_Status_stat 0;
BA_ "GenSigSendType" SG_ 508 ESP_Rollover_Status_stat 0;
BA_ "GenSigSwitchedByIgnition" SG_ 508 ESP_AVH_LED 0;
BA_ "GenSigStartValue" SG_ 508 ESP_AVH_LED 6;
BA_ "GenSigSendType" SG_ 508 ESP_AVH_LED 0;
BA_ "GenSigSwitchedByIgnition" SG_ 508 ESP_HDC_LED 0;
BA_ "GenSigStartValue" SG_ 508 ESP_HDC_LED 6;
BA_ "GenSigSendType" SG_ 508 ESP_HDC_LED 0;
BA_ "GenSigSwitchedByIgnition" SG_ 508 ESP_Off_LED 0;
BA_ "GenSigStartValue" SG_ 508 ESP_Off_LED 6;
BA_ "GenSigSendType" SG_ 508 ESP_Off_LED 0;
BA_ "GenSigSwitchedByIgnition" SG_ 508 ESP_Notbremsanzeige 0;
BA_ "GenSigSendType" SG_ 508 ESP_Notbremsanzeige 0;
BA_ "GenSigSwitchedByIgnition" SG_ 508 ESC_Motorstartverzoegerung 0;
BA_ "GenSigSendType" SG_ 508 ESC_Motorstartverzoegerung 0;
BA_ "GenSigSwitchedByIgnition" SG_ 508 ESP_Offroad_Lampe 0;
BA_ "GenSigSendType" SG_ 508 ESP_Offroad_Lampe 0;
BA_ "GenSigSwitchedByIgnition" SG_ 508 ESP_HDC_Textanzeigen 0;
BA_ "GenSigSendType" SG_ 508 ESP_HDC_Textanzeigen 0;
BA_ "GenSigSwitchedByIgnition" SG_ 427 ESP_33_CRC 0;
BA_ "GenSigFuncType" SG_ 427 ESP_33_CRC 2;
BA_ "GenSigSendType" SG_ 427 ESP_33_CRC 0;
BA_ "GenSigSwitchedByIgnition" SG_ 427 ESP_33_BZ 0;
BA_ "GenSigFuncType" SG_ 427 ESP_33_BZ 1;
BA_ "GenSigSendType" SG_ 427 ESP_33_BZ 0;
BA_ "GenSigSwitchedByIgnition" SG_ 427 ESC_AHW_aktiv 0;
BA_ "GenSigSendType" SG_ 427 ESC_AHW_aktiv 3;
BA_ "GenSigSwitchedByIgnition" SG_ 427 ESC_AHW_nicht_verfuegbar 0;
BA_ "GenSigSendType" SG_ 427 ESC_AHW_nicht_verfuegbar 3;
BA_ "GenSigSwitchedByIgnition" SG_ 427 ESC_ANB_CM_aktiv 0;
BA_ "GenSigSendType" SG_ 427 ESC_ANB_CM_aktiv 0;
BA_ "GenSigSwitchedByIgnition" SG_ 427 ESC_ANB_CM_nicht_verfuegbar 0;
BA_ "GenSigSendType" SG_ 427 ESC_ANB_CM_nicht_verfuegbar 0;
BA_ "GenSigSwitchedByIgnition" SG_ 427 ESC_Warnruck_aktiv 0;
BA_ "GenSigSendType" SG_ 427 ESC_Warnruck_aktiv 3;
BA_ "GenSigSwitchedByIgnition" SG_ 427 ESC_Warnruck_nicht_verfuegbar 0;
BA_ "GenSigSendType" SG_ 427 ESC_Warnruck_nicht_verfuegbar 3;
BA_ "GenSigSwitchedByIgnition" SG_ 427 ESC_Prefill_aktiv 0;
BA_ "GenSigSendType" SG_ 427 ESC_Prefill_aktiv 3;
BA_ "GenSigSwitchedByIgnition" SG_ 427 ESC_Prefill_nicht_verfuegbar 0;
BA_ "GenSigSendType" SG_ 427 ESC_Prefill_nicht_verfuegbar 3;
BA_ "GenSigSwitchedByIgnition" SG_ 427 ESC_HBA_aktiv 0;
BA_ "GenSigSendType" SG_ 427 ESC_HBA_aktiv 3;
BA_ "GenSigSwitchedByIgnition" SG_ 427 ESC_HBA_nicht_verfuegbar 0;
BA_ "GenSigSendType" SG_ 427 ESC_HBA_nicht_verfuegbar 3;
BA_ "GenSigSwitchedByIgnition" SG_ 427 ESC_TSK_SRBM_Anf 0;
BA_ "GenSigSendType" SG_ 427 ESC_TSK_SRBM_Anf 0;
BA_ "GenSigSwitchedByIgnition" SG_ 427 ESC_TSK_SRBM_nicht_verfuegbar 0;
BA_ "GenSigSendType" SG_ 427 ESC_TSK_SRBM_nicht_verfuegbar 0;
BA_ "GenSigSwitchedByIgnition" SG_ 427 ESC_Verz_Reg_aktiv 0;
BA_ "GenSigSendType" SG_ 427 ESC_Verz_Reg_aktiv 0;
BA_ "GenSigSwitchedByIgnition" SG_ 427 ESC_Verz_Reg_nicht_verfuegbar 0;
BA_ "GenSigSendType" SG_ 427 ESC_Verz_Reg_nicht_verfuegbar 0;
BA_ "GenSigSwitchedByIgnition" SG_ 427 ESC_Verz_Reg_TB_nicht_verfuegbar 0;
BA_ "GenSigSendType" SG_ 427 ESC_Verz_Reg_TB_nicht_verfuegbar 0;
BA_ "GenSigSwitchedByIgnition" SG_ 427 ESC_Verz_Reg_ZB_nicht_verfuegbar 0;
BA_ "GenSigSendType" SG_ 427 ESC_Verz_Reg_ZB_nicht_verfuegbar 0;
BA_ "GenSigSwitchedByIgnition" SG_ 427 ESC_Bremslicht_unplausibel 0;
BA_ "GenSigSendType" SG_ 427 ESC_Bremslicht_unplausibel 3;
BA_ "GenSigSwitchedByIgnition" SG_ 427 ESC_Konsistenz_ACC 0;
BA_ "GenSigSendType" SG_ 427 ESC_Konsistenz_ACC 0;
BA_ "GenSigSwitchedByIgnition" SG_ 427 ESC_Konsistenz_AWV 0;
BA_ "GenSigSendType" SG_ 427 ESC_Konsistenz_AWV 0;
BA_ "GenSigSwitchedByIgnition" SG_ 427 ESC_Konsistenz_ARA 0;
BA_ "GenSigSendType" SG_ 427 ESC_Konsistenz_ARA 3;
BA_ "GenSigSwitchedByIgnition" SG_ 427 ESC_Konsistenz_IPA 0;
BA_ "GenSigSendType" SG_ 427 ESC_Konsistenz_IPA 0;
BA_ "GenSigSwitchedByIgnition" SG_ 427 ESC_Konsistenz_FCW 0;
BA_ "GenSigSendType" SG_ 427 ESC_Konsistenz_FCW 0;
BA_ "GenSigSwitchedByIgnition" SG_ 427 ESC_Konsistenz_NV 0;
BA_ "GenSigSendType" SG_ 427 ESC_Konsistenz_NV 3;
BA_ "GenSigSwitchedByIgnition" SG_ 427 ESC_Konsistenz_RCTA 0;
BA_ "GenSigSendType" SG_ 427 ESC_Konsistenz_RCTA 3;
BA_ "GenSigSwitchedByIgnition" SG_ 427 ESC_Konsistenz_TSK 0;
BA_ "GenSigSendType" SG_ 427 ESC_Konsistenz_TSK 0;
BA_ "GenSigSwitchedByIgnition" SG_ 427 ESC_Konsistenz_vFGS 0;
BA_ "GenSigSendType" SG_ 427 ESC_Konsistenz_vFGS 0;
BA_ "GenSigSwitchedByIgnition" SG_ 427 ESC_Konsistenz_STA 0;
BA_ "GenSigSendType" SG_ 427 ESC_Konsistenz_STA 0;
BA_ "GenSigSwitchedByIgnition" SG_ 427 ESC_Fahrer_Bremsdruck_bestimmend 0;
BA_ "GenSigSendType" SG_ 427 ESC_Fahrer_Bremsdruck_bestimmend 0;
BA_ "GenSigSwitchedByIgnition" SG_ 427 ESC_Konsistenz_EA 0;
BA_ "GenSigSendType" SG_ 427 ESC_Konsistenz_EA 0;
BA_ "GenSigSwitchedByIgnition" SG_ 427 ESC_Konsistenz_BFF 0;
BA_ "GenSigSendType" SG_ 427 ESC_Konsistenz_BFF 0;
BA_ "GenSigSwitchedByIgnition" SG_ 427 ESC_Konsistenz_MKB 0;
BA_ "GenSigSendType" SG_ 427 ESC_Konsistenz_MKB 0;
BA_ "Fehlerwert" SG_ 2589283470 ESC_Kilometer 1048575;
BA_ "GenSigSwitchedByIgnition" SG_ 2589283470 ESC_Kilometer 0;
BA_ "GenSigStartValue" SG_ 2589283470 ESC_Kilometer 1048574;
BA_ "GenSigSendType" SG_ 2589283470 ESC_Kilometer 0;
BA_ "GenSigSwitchedByIgnition" SG_ 2589283470 ESC_Kilometer_MUX 0;
BA_ "GenSigSendType" SG_ 2589283470 ESC_Kilometer_MUX 0;
BA_ "GenSigSwitchedByIgnition" SG_ 2589283470 ESC_Signatur_Kilometer_GFA_01 0;
BA_ "GenSigSwitchedByIgnition" SG_ 2589283470 ESC_Signatur_Kilometer_IKA_01 0;
BA_ "GenSigSwitchedByIgnition" SG_ 2589283470 ESC_Signatur_Kilometer_GFA_02 0;
BA_ "GenSigSwitchedByIgnition" SG_ 2589283470 ESC_Signatur_Kilometer_IKA_02 0;
BA_ "GenSigFuncType" SG_ 264 Fahrwerk_01_CRC 2;
BA_ "GenSigSendType" SG_ 264 Fahrwerk_01_CRC 0;
BA_ "GenSigFuncType" SG_ 264 Fahrwerk_01_BZ 1;
BA_ "GenSigSendType" SG_ 264 Fahrwerk_01_BZ 0;
BA_ "GenSigSendType" SG_ 264 FA_Hoehenwerte_kalibriert 0;
BA_ "Fehlerwert" SG_ 264 FA_Hoehenwert_VL_00 255;
BA_ "GenSigStartValue" SG_ 264 FA_Hoehenwert_VL_00 254;
BA_ "GenSigSendType" SG_ 264 FA_Hoehenwert_VL_00 0;
BA_ "Fehlerwert" SG_ 264 FA_Hoehenwert_VR_00 255;
BA_ "GenSigStartValue" SG_ 264 FA_Hoehenwert_VR_00 254;
BA_ "GenSigSendType" SG_ 264 FA_Hoehenwert_VR_00 0;
BA_ "Fehlerwert" SG_ 264 FA_Hoehenwert_HL_00 255;
BA_ "GenSigStartValue" SG_ 264 FA_Hoehenwert_HL_00 254;
BA_ "GenSigSendType" SG_ 264 FA_Hoehenwert_HL_00 0;
BA_ "Fehlerwert" SG_ 264 FA_Hoehenwert_HR_00 255;
BA_ "GenSigStartValue" SG_ 264 FA_Hoehenwert_HR_00 254;
BA_ "GenSigSendType" SG_ 264 FA_Hoehenwert_HR_00 0;
BA_ "GenSigSwitchedByIgnition" SG_ 429 Fahrwerk_06_CRC 0;
BA_ "GenSigFuncType" SG_ 429 Fahrwerk_06_CRC 2;
BA_ "GenSigSendType" SG_ 429 Fahrwerk_06_CRC 0;
BA_ "GenSigSwitchedByIgnition" SG_ 429 Fahrwerk_06_BZ 0;
BA_ "GenSigFuncType" SG_ 429 Fahrwerk_06_BZ 1;
BA_ "GenSigSendType" SG_ 429 Fahrwerk_06_BZ 0;
BA_ "GenSigSwitchedByIgnition" SG_ 429 NR_Reglerstatus 0;
BA_ "GenSigSendType" SG_ 429 NR_Reglerstatus 3;
BA_ "GenSigSwitchedByIgnition" SG_ 429 FA_Verstellung_in_Kuerze 0;
BA_ "GenSigSendType" SG_ 429 FA_Verstellung_in_Kuerze 0;
BA_ "GenSigSwitchedByIgnition" SG_ 429 FA_Verstellung_aktiv 0;
BA_ "GenSigSendType" SG_ 429 FA_Verstellung_aktiv 0;
BA_ "GenSigSwitchedByIgnition" SG_ 429 FA_Kompressor_laeuft_in_Kuerze 0;
BA_ "GenSigSendType" SG_ 429 FA_Kompressor_laeuft_in_Kuerze 0;
BA_ "GenSigSwitchedByIgnition" SG_ 429 FA_Kompressor_laeuft 0;
BA_ "GenSigSendType" SG_ 429 FA_Kompressor_laeuft 0;
BA_ "GenSigSwitchedByIgnition" SG_ 429 NR_Anforderung_v_Begrenzung 0;
BA_ "GenSigSendType" SG_ 429 NR_Anforderung_v_Begrenzung 0;
BA_ "GenSigSwitchedByIgnition" SG_ 429 NR_LED_SGN 0;
BA_ "GenSigSendType" SG_ 429 NR_LED_SGN 3;
BA_ "GenSigSwitchedByIgnition" SG_ 429 NR_LED_TN 0;
BA_ "GenSigSendType" SG_ 429 NR_LED_TN 3;
BA_ "GenSigSwitchedByIgnition" SG_ 429 NR_LED_BN 0;
BA_ "GenSigSendType" SG_ 429 NR_LED_BN 3;
BA_ "GenSigSwitchedByIgnition" SG_ 429 FA_Absenkung_Fahrzeug 0;
BA_ "GenSigSendType" SG_ 429 FA_Absenkung_Fahrzeug 0;
BA_ "GenSigSwitchedByIgnition" SG_ 429 FA_Anhaengerstatus_intern 0;
BA_ "GenSigSendType" SG_ 429 FA_Anhaengerstatus_intern 0;
BA_ "GenSigSwitchedByIgnition" SG_ 429 FA_Anhebung_Fahrzeug 0;
BA_ "GenSigSendType" SG_ 429 FA_Anhebung_Fahrzeug 0;
BA_ "GenSigSwitchedByIgnition" SG_ 429 FA_Druckspeicher_verfuegbar 0;
BA_ "GenSigSendType" SG_ 429 FA_Druckspeicher_verfuegbar 0;
BA_ "GenSigSendType" SG_ 429 FA_ESP_Zuschaltung 0;
BA_ "GenSigSwitchedByIgnition" SG_ 429 NR_LED_HN 0;
BA_ "GenSigSendType" SG_ 429 NR_LED_HN 3;
BA_ "GenSigSwitchedByIgnition" SG_ 429 FA_Zwischenniveau 0;
BA_ "GenSigSendType" SG_ 429 FA_Zwischenniveau 0;
BA_ "GenSigSwitchedByIgnition" SG_ 429 FA_Systemstatus 0;
BA_ "GenSigSendType" SG_ 429 FA_Systemstatus 0;
BA_ "GenSigSwitchedByIgnition" SG_ 429 EFP_Soll_FahrPr_HAL 0;
BA_ "GenSigSendType" SG_ 429 EFP_Soll_FahrPr_HAL 0;
BA_ "Fehlerwert" SG_ 429 NR_Kompressor_Temp_Zylinderkopf 255;
BA_ "GenSigStartValue" SG_ 429 NR_Kompressor_Temp_Zylinderkopf 254;
BA_ "GenSigSendType" SG_ 429 NR_Kompressor_Temp_Zylinderkopf 0;
BA_ "Fehlerwert" SG_ 429 FA_Signal_Drucksensor 255;
BA_ "GenSigSwitchedByIgnition" SG_ 429 FA_Signal_Drucksensor 0;
BA_ "GenSigStartValue" SG_ 429 FA_Signal_Drucksensor 254;
BA_ "GenSigSendType" SG_ 429 FA_Signal_Drucksensor 0;
BA_ "GenSigSendType" SG_ 1605 FLA_aktiv 3;
BA_ "GenSigSendType" SG_ 1605 FLA_ISP_defekt 3;
BA_ "GenSigSendType" SG_ 1605 FLA_Sensor_blockiert 3;
BA_ "Fehlerwert" SG_ 1605 FLA_Abblendursache 255;
BA_ "GenSigSendType" SG_ 1605 FLA_Abblendursache 3;
BA_ "Fehlerwert" SG_ 1605 FLA_Fernlicht_PWM 127;
BA_ "GenSigStartValue" SG_ 1605 FLA_Fernlicht_PWM 100;
BA_ "GenSigSendType" SG_ 1605 FLA_Fernlicht_PWM 3;
BA_ "Fehlerwert" SG_ 1605 ISP_EC_Lichtwert_vorne 63;
BA_ "GenSigStartValue" SG_ 1605 ISP_EC_Lichtwert_vorne 62;
BA_ "GenSigSendType" SG_ 1605 ISP_EC_Lichtwert_vorne 3;
BA_ "Fehlerwert" SG_ 1605 ISP_EC_Lichtwert_hinten 63;
BA_ "GenSigStartValue" SG_ 1605 ISP_EC_Lichtwert_hinten 62;
BA_ "GenSigSendType" SG_ 1605 ISP_EC_Lichtwert_hinten 3;
BA_ "Fehlerwert" SG_ 1605 ISP_Himmelsrichtung 31;
BA_ "GenSigStartValue" SG_ 1605 ISP_Himmelsrichtung 30;
BA_ "GenSigSendType" SG_ 1605 ISP_Himmelsrichtung 3;
BA_ "GenSigSendType" SG_ 1605 ISP_Taste_betaetigt 3;
BA_ "GenSigStartValue" SG_ 1605 ISP_EC_aktiv 1;
BA_ "GenSigSendType" SG_ 1605 ISP_EC_aktiv 3;
BA_ "GenSigStartValue" SG_ 1605 ISP_Kompass_aktiv 1;
BA_ "GenSigSendType" SG_ 1605 ISP_Kompass_aktiv 3;
BA_ "GenSigSendType" SG_ 1605 ISP_Dimmung_ASP_02 3;
BA_ "GenSigSendType" SG_ 1605 FLA_Aufblenden 3;
BA_ "GenSigSendType" SG_ 1605 FLA_SAE_Mode 3;
BA_ "GenSigSwitchedByIgnition" SG_ 1726 FSS_Laenge_Pos 0;
BA_ "GenSigSendType" SG_ 1726 FSS_Laenge_Pos 6;
BA_ "GenSigActiveRepetitions" SG_ 1726 FSS_Laenge_Pos 5;
BA_ "GenSigSwitchedByIgnition" SG_ 1726 FSS_Hoehe_Pos 0;
BA_ "GenSigSendType" SG_ 1726 FSS_Hoehe_Pos 6;
BA_ "GenSigActiveRepetitions" SG_ 1726 FSS_Hoehe_Pos 5;
BA_ "GenSigSwitchedByIgnition" SG_ 1726 FSS_Kopfstuetze_Pos 0;
BA_ "GenSigSendType" SG_ 1726 FSS_Kopfstuetze_Pos 6;
BA_ "GenSigActiveRepetitions" SG_ 1726 FSS_Kopfstuetze_Pos 5;
BA_ "GenSigSwitchedByIgnition" SG_ 1726 FSS_Neigung_Lehne_Pos 0;
BA_ "GenSigSendType" SG_ 1726 FSS_Neigung_Lehne_Pos 6;
BA_ "GenSigActiveRepetitions" SG_ 1726 FSS_Neigung_Lehne_Pos 5;
BA_ "GenSigSwitchedByIgnition" SG_ 1727 FSS_Lehnenkopf_Pos 0;
BA_ "GenSigSendType" SG_ 1727 FSS_Lehnenkopf_Pos 6;
BA_ "GenSigActiveRepetitions" SG_ 1727 FSS_Lehnenkopf_Pos 5;
BA_ "GenSigSwitchedByIgnition" SG_ 1727 FSS_Neigung_Sitz_Pos 0;
BA_ "GenSigSendType" SG_ 1727 FSS_Neigung_Sitz_Pos 6;
BA_ "GenSigActiveRepetitions" SG_ 1727 FSS_Neigung_Sitz_Pos 5;
BA_ "GenSigSwitchedByIgnition" SG_ 1727 FSS_KopfstuetzeX_Pos 0;
BA_ "GenSigSendType" SG_ 1727 FSS_KopfstuetzeX_Pos 6;
BA_ "GenSigActiveRepetitions" SG_ 1727 FSS_KopfstuetzeX_Pos 5;
BA_ "GenSigSwitchedByIgnition" SG_ 173 Getriebe_11_CRC 0;
BA_ "GenSigFuncType" SG_ 173 Getriebe_11_CRC 2;
BA_ "GenSigSendType" SG_ 173 Getriebe_11_CRC 0;
BA_ "GenSigSwitchedByIgnition" SG_ 173 Getriebe_11_BZ 0;
BA_ "GenSigFuncType" SG_ 173 Getriebe_11_BZ 1;
BA_ "GenSigSendType" SG_ 173 Getriebe_11_BZ 0;
BA_ "Fehlerwert" SG_ 173 GE_MMom_Soll_02 1023;
BA_ "GenSigSwitchedByIgnition" SG_ 173 GE_MMom_Soll_02 0;
BA_ "GenSigStartValue" SG_ 173 GE_MMom_Soll_02 1022;
BA_ "GenSigSendType" SG_ 173 GE_MMom_Soll_02 0;
BA_ "Fehlerwert" SG_ 173 GE_MMom_Vorhalt_02 1023;
BA_ "GenSigSwitchedByIgnition" SG_ 173 GE_MMom_Vorhalt_02 0;
BA_ "GenSigStartValue" SG_ 173 GE_MMom_Vorhalt_02 1022;
BA_ "GenSigSendType" SG_ 173 GE_MMom_Vorhalt_02 0;
BA_ "Fehlerwert" SG_ 173 GE_Uefkt 1023;
BA_ "GenSigSwitchedByIgnition" SG_ 173 GE_Uefkt 0;
BA_ "GenSigSendType" SG_ 173 GE_Uefkt 0;
BA_ "Fehlerwert" SG_ 173 GE_Fahrstufe 15;
BA_ "GenSigSwitchedByIgnition" SG_ 173 GE_Fahrstufe 0;
BA_ "GenSigStartValue" SG_ 173 GE_Fahrstufe 1;
BA_ "GenSigSendType" SG_ 173 GE_Fahrstufe 3;
BA_ "GenSigSwitchedByIgnition" SG_ 173 GE_reserv_Fahrstufe 0;
BA_ "GenSigSendType" SG_ 173 GE_reserv_Fahrstufe 0;
BA_ "GenSigSwitchedByIgnition" SG_ 173 GE_Schaltablauf 0;
BA_ "GenSigSendType" SG_ 173 GE_Schaltablauf 0;
BA_ "GenSigSwitchedByIgnition" SG_ 173 GE_Uefkt_unplausibel 0;
BA_ "GenSigSendType" SG_ 173 GE_Uefkt_unplausibel 0;
BA_ "GenSigSwitchedByIgnition" SG_ 173 GE_MMom_Status_02 0;
BA_ "GenSigSendType" SG_ 173 GE_MMom_Status_02 0;
BA_ "GenSigSwitchedByIgnition" SG_ 173 GE_Status_Kraftschluss 0;
BA_ "GenSigSendType" SG_ 173 GE_Status_Kraftschluss 0;
BA_ "GenSigSwitchedByIgnition" SG_ 173 GE_MMom_Status 0;
BA_ "GenSigSendType" SG_ 173 GE_MMom_Status 0;
BA_ "GenSigSwitchedByIgnition" SG_ 173 GE_Freig_MMom_Vorhalt 0;
BA_ "GenSigSendType" SG_ 173 GE_Freig_MMom_Vorhalt 0;
BA_ "GenSigSwitchedByIgnition" SG_ 173 GE_Verbot_Ausblendung 0;
BA_ "GenSigSendType" SG_ 173 GE_Verbot_Ausblendung 0;
BA_ "Fehlerwert" SG_ 173 GE_Zielgang 15;
BA_ "GenSigSwitchedByIgnition" SG_ 173 GE_Zielgang 0;
BA_ "GenSigSendType" SG_ 173 GE_Zielgang 0;
BA_ "GenSigSwitchedByIgnition" SG_ 968 GE_OBD_AbsperrVent 0;
BA_ "GenSigSendType" SG_ 968 GE_OBD_AbsperrVent 0;
BA_ "GenSigSwitchedByIgnition" SG_ 968 GE_amax_moeglich 0;
BA_ "GenSigStartValue" SG_ 968 GE_amax_moeglich 84;
BA_ "GenSigSendType" SG_ 968 GE_amax_moeglich 0;
BA_ "GenSigSwitchedByIgnition" SG_ 968 GE_Charisma_FahrPr 0;
BA_ "GenSigSendType" SG_ 968 GE_Charisma_FahrPr 0;
BA_ "GenSigSwitchedByIgnition" SG_ 968 GE_Charisma_Status 0;
BA_ "GenSigSendType" SG_ 968 GE_Charisma_Status 0;
BA_ "GenSigSwitchedByIgnition" SG_ 968 GE_Freigabe_Verfallsinfo_WFS 0;
BA_ "GenSigSendType" SG_ 968 GE_Freigabe_Verfallsinfo_WFS 0;
BA_ "GenSigSwitchedByIgnition" SG_ 968 Freilauf_Charisma_FahrPr 0;
BA_ "GenSigSendType" SG_ 968 Freilauf_Charisma_FahrPr 0;
BA_ "GenSigSwitchedByIgnition" SG_ 968 Freilauf_Charisma_Status 0;
BA_ "GenSigSendType" SG_ 968 Freilauf_Charisma_Status 0;
BA_ "GenSigSwitchedByIgnition" SG_ 968 GE_Freigabe_Info_WFS 0;
BA_ "GenSigSendType" SG_ 968 GE_Freigabe_Info_WFS 3;
BA_ "GenSigSwitchedByIgnition" SG_ 968 GE_Sperr_Info_WFS 0;
BA_ "GenSigSendType" SG_ 968 GE_Sperr_Info_WFS 3;
BA_ "GenSigSwitchedByIgnition" SG_ 968 GE_Zustand_Kuppltemp 0;
BA_ "GenSigSendType" SG_ 968 GE_Zustand_Kuppltemp 0;
BA_ "GenSigSwitchedByIgnition" SG_ 968 GE_Codierung_MSG 0;
BA_ "GenSigSendType" SG_ 968 GE_Codierung_MSG 0;
BA_ "GenSigSwitchedByIgnition" SG_ 968 GE_LaunchControl 0;
BA_ "GenSigSendType" SG_ 968 GE_LaunchControl 0;
BA_ "GenSigSwitchedByIgnition" SG_ 968 GE_Heizwunsch 0;
BA_ "GenSigStartValue" SG_ 968 GE_Heizwunsch 1;
BA_ "GenSigSendType" SG_ 968 GE_Heizwunsch 0;
BA_ "GenSigSwitchedByIgnition" SG_ 968 GE_OBD_Status 0;
BA_ "GenSigSendType" SG_ 968 GE_OBD_Status 0;
BA_ "GenSigSwitchedByIgnition" SG_ 968 GE_LFR_Adaption 0;
BA_ "GenSigSendType" SG_ 968 GE_LFR_Adaption 0;
BA_ "Fehlerwert" SG_ 968 GE_Sumpftemperatur 255;
BA_ "GenSigSwitchedByIgnition" SG_ 968 GE_Sumpftemperatur 0;
BA_ "GenSigSendType" SG_ 968 GE_Sumpftemperatur 0;
BA_ "GenSigSwitchedByIgnition" SG_ 310 HAL_01_CRC 0;
BA_ "GenSigFuncType" SG_ 310 HAL_01_CRC 2;
BA_ "GenSigSendType" SG_ 310 HAL_01_CRC 0;
BA_ "GenSigSwitchedByIgnition" SG_ 310 HAL_01_BZ 0;
BA_ "GenSigFuncType" SG_ 310 HAL_01_BZ 1;
BA_ "GenSigSendType" SG_ 310 HAL_01_BZ 0;
BA_ "GenSigSwitchedByIgnition" SG_ 310 HAL_Status 0;
BA_ "GenSigSendType" SG_ 310 HAL_Status 0;
BA_ "GenSigSwitchedByIgnition" SG_ 310 HAL_VZ_Radwinkel 0;
BA_ "GenSigSendType" SG_ 310 HAL_VZ_Radwinkel 0;
BA_ "GenSigSwitchedByIgnition" SG_ 310 HAL_QBit_Radwinkel 0;
BA_ "GenSigSendType" SG_ 310 HAL_QBit_Radwinkel 0;
BA_ "Fehlerwert" SG_ 310 HAL_Radwinkel 1023;
BA_ "GenSigSwitchedByIgnition" SG_ 310 HAL_Radwinkel 0;
BA_ "GenSigStartValue" SG_ 310 HAL_Radwinkel 1022;
BA_ "GenSigSendType" SG_ 310 HAL_Radwinkel 0;
BA_ "GenSigSwitchedByIgnition" SG_ 310 HAL_Warnungen 0;
BA_ "GenSigSendType" SG_ 310 HAL_Warnungen 0;
BA_ "GenSigSwitchedByIgnition" SG_ 310 HAL_VZ_Fahrerwunschwinkel_Soll 0;
BA_ "GenSigSendType" SG_ 310 HAL_VZ_Fahrerwunschwinkel_Soll 0;
BA_ "Fehlerwert" SG_ 310 HAL_Fahrerwunschwinkel_Soll 1023;
BA_ "GenSigSwitchedByIgnition" SG_ 310 HAL_Fahrerwunschwinkel_Soll 0;
BA_ "GenSigStartValue" SG_ 310 HAL_Fahrerwunschwinkel_Soll 1022;
BA_ "GenSigSendType" SG_ 310 HAL_Fahrerwunschwinkel_Soll 0;
BA_ "Fehlerwert" SG_ 310 HAL_max_Gradient 127;
BA_ "GenSigSwitchedByIgnition" SG_ 310 HAL_max_Gradient 0;
BA_ "GenSigStartValue" SG_ 310 HAL_max_Gradient 126;
BA_ "GenSigSendType" SG_ 310 HAL_max_Gradient 0;
BA_ "GenSigSwitchedByIgnition" SG_ 310 HAL_EFP_FahrPr 0;
BA_ "GenSigSendType" SG_ 310 HAL_EFP_FahrPr 0;
BA_ "GenSigSwitchedByIgnition" SG_ 310 HAL_Charisma_Status 0;
BA_ "GenSigSendType" SG_ 310 HAL_Charisma_Status 0;
BA_ "GenSigSwitchedByIgnition" SG_ 310 HAL_Charisma_FahrPr 0;
BA_ "GenSigSendType" SG_ 310 HAL_Charisma_FahrPr 0;
BA_ "GenSigSwitchedByIgnition" SG_ 676 HAL_02_CRC 0;
BA_ "GenSigFuncType" SG_ 676 HAL_02_CRC 2;
BA_ "GenSigSendType" SG_ 676 HAL_02_CRC 0;
BA_ "GenSigSwitchedByIgnition" SG_ 676 HAL_02_BZ 0;
BA_ "GenSigFuncType" SG_ 676 HAL_02_BZ 1;
BA_ "GenSigSendType" SG_ 676 HAL_02_BZ 0;
BA_ "GenSigSwitchedByIgnition" SG_ 676 HAL_ARA_Status 0;
BA_ "GenSigSendType" SG_ 676 HAL_ARA_Status 0;
BA_ "GenSigSwitchedByIgnition" SG_ 676 HAL_PLA_Status 0;
BA_ "GenSigSendType" SG_ 676 HAL_PLA_Status 0;
BA_ "GenSigSwitchedByIgnition" SG_ 676 HAL_PWR_Abbruch 0;
BA_ "GenSigSendType" SG_ 676 HAL_PWR_Abbruch 0;
BA_ "GenSigSwitchedByIgnition" SG_ 676 HAL_PWR_Fehler 0;
BA_ "GenSigSendType" SG_ 676 HAL_PWR_Fehler 0;
BA_ "GenSigSwitchedByIgnition" SG_ 1410 HD_Endstellung_oben 0;
BA_ "GenSigSendType" SG_ 1410 HD_Endstellung_oben 0;
BA_ "GenSigSwitchedByIgnition" SG_ 1410 HD_Endstellung_unten 0;
BA_ "GenSigSendType" SG_ 1410 HD_Endstellung_unten 0;
BA_ "GenSigSwitchedByIgnition" SG_ 1410 HD_Bewegung_auf 0;
BA_ "GenSigSendType" SG_ 1410 HD_Bewegung_auf 0;
BA_ "GenSigSwitchedByIgnition" SG_ 1410 HD_Bewegung_zu 0;
BA_ "GenSigSendType" SG_ 1410 HD_Bewegung_zu 0;
BA_ "GenSigSwitchedByIgnition" SG_ 1410 HD_Innentaster_betaetigt 0;
BA_ "GenSigSendType" SG_ 1410 HD_Innentaster_betaetigt 0;
BA_ "GenSigSwitchedByIgnition" SG_ 1410 HD_UeKB_erkannt 0;
BA_ "GenSigSendType" SG_ 1410 HD_UeKB_erkannt 0;
BA_ "GenSigSwitchedByIgnition" SG_ 1410 HD_Position 0;
BA_ "GenSigSendType" SG_ 1410 HD_Position 0;
BA_ "GenSigSwitchedByIgnition" SG_ 1410 HD_Taster_defekt 0;
BA_ "GenSigSendType" SG_ 1410 HD_Taster_defekt 0;
BA_ "GenSigSwitchedByIgnition" SG_ 1410 HD_Rueckmeld_prog 0;
BA_ "GenSigSendType" SG_ 1410 HD_Rueckmeld_prog 0;
BA_ "GenSigSwitchedByIgnition" SG_ 1410 HD_Verriegelungstaster_betaetigt 0;
BA_ "GenSigSendType" SG_ 1410 HD_Verriegelungstaster_betaetigt 0;
BA_ "GenSigSwitchedByIgnition" SG_ 1410 HD_Verr_Taster_betaetigt_inv 0;
BA_ "GenSigSendType" SG_ 1410 HD_Verr_Taster_betaetigt_inv 0;
BA_ "GenSigSwitchedByIgnition" SG_ 1410 HD_ZZH_Schalter_S3 0;
BA_ "GenSigSendType" SG_ 1410 HD_ZZH_Schalter_S3 3;
BA_ "GenSigSwitchedByIgnition" SG_ 1416 FSH_LED 0;
BA_ "GenSigSendType" SG_ 1416 FSH_LED 3;
BA_ "GenSigSwitchedByIgnition" SG_ 1416 HSH_LED 0;
BA_ "GenSigSendType" SG_ 1416 HSH_LED 3;
BA_ "GenSigSwitchedByIgnition" SG_ 1416 SIH_Stufe_LED_li 0;
BA_ "GenSigSendType" SG_ 1416 SIH_Stufe_LED_li 3;
BA_ "GenSigSwitchedByIgnition" SG_ 1416 SIH_Stufe_LED_re 0;
BA_ "GenSigSendType" SG_ 1416 SIH_Stufe_LED_re 3;
BA_ "GenSigSwitchedByIgnition" SG_ 1416 SIL_Stufe_LED_li 0;
BA_ "GenSigSendType" SG_ 1416 SIL_Stufe_LED_li 3;
BA_ "GenSigSwitchedByIgnition" SG_ 1416 SIL_Stufe_LED_re 0;
BA_ "GenSigSendType" SG_ 1416 SIL_Stufe_LED_re 3;
BA_ "GenSigSwitchedByIgnition" SG_ 1416 KRH_Stufe_LED_li 0;
BA_ "GenSigSendType" SG_ 1416 KRH_Stufe_LED_li 3;
BA_ "GenSigSwitchedByIgnition" SG_ 1416 KRH_Stufe_LED_re 0;
BA_ "GenSigSendType" SG_ 1416 KRH_Stufe_LED_re 3;
BA_ "GenSigSwitchedByIgnition" SG_ 1416 BCM1_TCH_HLR_Anf 0;
BA_ "GenSigSendType" SG_ 1416 BCM1_TCH_HLR_Anf 3;
BA_ "GenSigSwitchedByIgnition" SG_ 1416 HLR_SIH_Freigabe_Fond 0;
BA_ "GenSigSendType" SG_ 1416 HLR_SIH_Freigabe_Fond 3;
BA_ "GenSigSwitchedByIgnition" SG_ 1016 HLR_FlHz_Freigabe_Ruhesitz 0;
BA_ "GenSigSendType" SG_ 1016 HLR_FlHz_Freigabe_Ruhesitz 3;
BA_ "GenSigSwitchedByIgnition" SG_ 1016 HLR_FlHz_Freigabe_VR 0;
BA_ "GenSigSendType" SG_ 1016 HLR_FlHz_Freigabe_VR 3;
BA_ "GenSigSwitchedByIgnition" SG_ 1016 HLR_FlHz_Freigabe_VL 0;
BA_ "GenSigSendType" SG_ 1016 HLR_FlHz_Freigabe_VL 3;
BA_ "GenSigSwitchedByIgnition" SG_ 1016 HLR_FlHz_Freigabe_HR 0;
BA_ "GenSigSendType" SG_ 1016 HLR_FlHz_Freigabe_HR 3;
BA_ "GenSigSwitchedByIgnition" SG_ 1016 HLR_FlHz_Freigabe_HL 0;
BA_ "GenSigSendType" SG_ 1016 HLR_FlHz_Freigabe_HL 3;
BA_ "GenSigSwitchedByIgnition" SG_ 1016 HLR_TCH_Freigabe 0;
BA_ "GenSigSendType" SG_ 1016 HLR_TCH_Freigabe 3;
BA_ "GenSigSwitchedByIgnition" SG_ 1016 HLR_SIH_Freigabe_Fond 0;
BA_ "GenSigSendType" SG_ 1016 HLR_SIH_Freigabe_Fond 3;
BA_ "GenSigSwitchedByIgnition" SG_ 1016 HLR_Sp_Heizung_Freigabe_BT 0;
BA_ "GenSigSendType" SG_ 1016 HLR_Sp_Heizung_Freigabe_BT 3;
BA_ "GenSigSwitchedByIgnition" SG_ 1016 HLR_Sp_Heizung_Freigabe_FT 0;
BA_ "GenSigSendType" SG_ 1016 HLR_Sp_Heizung_Freigabe_FT 3;
BA_ "GenSigSwitchedByIgnition" SG_ 1016 HLR_KRH_Freigabe_VL 0;
BA_ "GenSigSendType" SG_ 1016 HLR_KRH_Freigabe_VL 3;
BA_ "GenSigSwitchedByIgnition" SG_ 1016 HLR_KRH_Freigabe_VR 0;
BA_ "GenSigSendType" SG_ 1016 HLR_KRH_Freigabe_VR 3;
BA_ "GenSigSwitchedByIgnition" SG_ 1016 HLR_SIH_Freigabe_VL 0;
BA_ "GenSigSendType" SG_ 1016 HLR_SIH_Freigabe_VL 3;
BA_ "GenSigSwitchedByIgnition" SG_ 1016 HLR_SIH_Freigabe_VR 0;
BA_ "GenSigSendType" SG_ 1016 HLR_SIH_Freigabe_VR 3;
BA_ "GenSigSwitchedByIgnition" SG_ 1016 HLR_SIH_Freigabe_HL 0;
BA_ "GenSigSendType" SG_ 1016 HLR_SIH_Freigabe_HL 3;
BA_ "GenSigSwitchedByIgnition" SG_ 1016 HLR_SIH_Freigabe_HR 0;
BA_ "GenSigSendType" SG_ 1016 HLR_SIH_Freigabe_HR 3;
BA_ "GenSigSwitchedByIgnition" SG_ 1016 HLR_SIL_Freigabe_VL 0;
BA_ "GenSigSendType" SG_ 1016 HLR_SIL_Freigabe_VL 3;
BA_ "GenSigSwitchedByIgnition" SG_ 1016 HLR_SIL_Freigabe_VR 0;
BA_ "GenSigSendType" SG_ 1016 HLR_SIL_Freigabe_VR 3;
BA_ "GenSigSwitchedByIgnition" SG_ 1016 HLR_SIL_Freigabe_HL 0;
BA_ "GenSigSendType" SG_ 1016 HLR_SIL_Freigabe_HL 3;
BA_ "GenSigSwitchedByIgnition" SG_ 1016 HLR_SIL_Freigabe_HR 0;
BA_ "GenSigSendType" SG_ 1016 HLR_SIL_Freigabe_HR 3;
BA_ "Fehlerwert" SG_ 1016 HLR_FSH_Freigabe 63;
BA_ "GenSigSwitchedByIgnition" SG_ 1016 HLR_FSH_Freigabe 0;
BA_ "GenSigSendType" SG_ 1016 HLR_FSH_Freigabe 3;
BA_ "GenSigSwitchedByIgnition" SG_ 1016 HLR_HSH_Freigabe 0;
BA_ "GenSigSendType" SG_ 1016 HLR_HSH_Freigabe 3;
BA_ "GenSigSwitchedByIgnition" SG_ 1016 HLR_LRH_Freigabe 0;
BA_ "GenSigSendType" SG_ 1016 HLR_LRH_Freigabe 3;
BA_ "Fehlerwert" SG_ 1016 HLR_PTC_linear_Freigabe 63;
BA_ "GenSigSwitchedByIgnition" SG_ 1016 HLR_PTC_linear_Freigabe 0;
BA_ "GenSigSendType" SG_ 1016 HLR_PTC_linear_Freigabe 3;
BA_ "GenSigSwitchedByIgnition" SG_ 1016 HLR_PTC_Freigabe 0;
BA_ "GenSigStartValue" SG_ 1016 HLR_PTC_Freigabe 3;
BA_ "GenSigSendType" SG_ 1016 HLR_PTC_Freigabe 3;
BA_ "GenSigSwitchedByIgnition" SG_ 1412 HSP_01_CRC 0;
BA_ "GenSigFuncType" SG_ 1412 HSP_01_CRC 2;
BA_ "GenSigSendType" SG_ 1412 HSP_01_CRC 0;
BA_ "GenSigSwitchedByIgnition" SG_ 1412 HSP_01_BZ 0;
BA_ "GenSigFuncType" SG_ 1412 HSP_01_BZ 1;
BA_ "GenSigSendType" SG_ 1412 HSP_01_BZ 0;
BA_ "GenSigSwitchedByIgnition" SG_ 1412 HSP_Taster 0;
BA_ "GenSigSendType" SG_ 1412 HSP_Taster 0;
BA_ "GenSigSwitchedByIgnition" SG_ 1412 HSP_Status_LED 0;
BA_ "GenSigSendType" SG_ 1412 HSP_Status_LED 0;
BA_ "GenSigSwitchedByIgnition" SG_ 1412 HSP_Warnung_LED 0;
BA_ "GenSigSendType" SG_ 1412 HSP_Warnung_LED 0;
BA_ "GenSigSwitchedByIgnition" SG_ 1412 HSP_Warnung_Ton 0;
BA_ "GenSigSendType" SG_ 1412 HSP_Warnung_Ton 0;
BA_ "GenSigSwitchedByIgnition" SG_ 1412 HSP_Warnung_Text 0;
BA_ "GenSigSendType" SG_ 1412 HSP_Warnung_Text 0;
BA_ "GenSigSwitchedByIgnition" SG_ 1412 HSP_Endlage_eingefahren 0;
BA_ "GenSigSendType" SG_ 1412 HSP_Endlage_eingefahren 0;
BA_ "GenSigSwitchedByIgnition" SG_ 1412 HSP_Endlage_ausgefahren 0;
BA_ "GenSigSendType" SG_ 1412 HSP_Endlage_ausgefahren 0;
BA_ "Fehlerwert" SG_ 1412 HSP_Unterspannung 1;
BA_ "GenSigSwitchedByIgnition" SG_ 1412 HSP_Unterspannung 0;
BA_ "GenSigSendType" SG_ 1412 HSP_Unterspannung 0;
BA_ "Fehlerwert" SG_ 1412 HSP_Ueberspannung 1;
BA_ "GenSigSwitchedByIgnition" SG_ 1412 HSP_Ueberspannung 0;
BA_ "GenSigSendType" SG_ 1412 HSP_Ueberspannung 0;
BA_ "GenSigSwitchedByIgnition" SG_ 1412 HSP_Lokalaktiv 0;
BA_ "GenSigSendType" SG_ 1412 HSP_Lokalaktiv 0;
BA_ "Fehlerwert" SG_ 1412 HSP_ResponseError 1;
BA_ "GenSigSwitchedByIgnition" SG_ 1412 HSP_ResponseError 0;
BA_ "GenSigSendType" SG_ 1412 HSP_ResponseError 0;
BA_ "GenSigSwitchedByIgnition" SG_ 1412 HSP_ErrorGueltigkeit_1 0;
BA_ "GenSigSendType" SG_ 1412 HSP_ErrorGueltigkeit_1 0;
BA_ "GenSigSwitchedByIgnition" SG_ 1412 HSP_ErrorGueltigkeit_2 0;
BA_ "GenSigSendType" SG_ 1412 HSP_ErrorGueltigkeit_2 0;
BA_ "Fehlerwert" SG_ 1412 HSP_def 1;
BA_ "GenSigSwitchedByIgnition" SG_ 1412 HSP_def 0;
BA_ "GenSigSendType" SG_ 1412 HSP_def 0;
BA_ "Fehlerwert" SG_ 1412 HSP_Motor_def 1;
BA_ "GenSigSwitchedByIgnition" SG_ 1412 HSP_Motor_def 0;
BA_ "GenSigSendType" SG_ 1412 HSP_Motor_def 0;
BA_ "GenSigSwitchedByIgnition" SG_ 1412 HSP_Spoiler_Error 0;
BA_ "GenSigSendType" SG_ 1412 HSP_Spoiler_Error 0;
BA_ "GenSigSwitchedByIgnition" SG_ 1412 HSP_Taster_Error 0;
BA_ "GenSigSendType" SG_ 1412 HSP_Taster_Error 0;
BA_ "Fehlerwert" SG_ 1412 HSP_LED_Error 1;
BA_ "GenSigSwitchedByIgnition" SG_ 1412 HSP_LED_Error 0;
BA_ "GenSigSendType" SG_ 1412 HSP_LED_Error 0;
BA_ "GenSigSwitchedByIgnition" SG_ 1412 HSP_Spielschutz 0;
BA_ "GenSigSendType" SG_ 1412 HSP_Spielschutz 0;
BA_ "GenSigSwitchedByIgnition" SG_ 1412 HSP_Charisma_FahrPr 0;
BA_ "GenSigSendType" SG_ 1412 HSP_Charisma_FahrPr 0;
BA_ "GenSigSwitchedByIgnition" SG_ 1412 HSP_Charisma_Status 0;
BA_ "GenSigSendType" SG_ 1412 HSP_Charisma_Status 0;
BA_ "GenSigSwitchedByIgnition" SG_ 1412 HSP_Adressegment 0;
BA_ "GenSigStartValue" SG_ 1412 HSP_Adressegment 7;
BA_ "GenSigSendType" SG_ 1412 HSP_Adressegment 0;
BA_ "GenSigSwitchedByIgnition" SG_ 1412 HSP_AdressInhalt 0;
BA_ "GenSigStartValue" SG_ 1412 HSP_AdressInhalt 15;
BA_ "GenSigSendType" SG_ 1412 HSP_AdressInhalt 0;
BA_ "GenSigSwitchedByIgnition" SG_ 1283 HVK_01_CRC 0;
BA_ "GenSigFuncType" SG_ 1283 HVK_01_CRC 2;
BA_ "GenSigSendType" SG_ 1283 HVK_01_CRC 0;
BA_ "GenSigSwitchedByIgnition" SG_ 1283 HVK_01_BZ 0;
BA_ "GenSigFuncType" SG_ 1283 HVK_01_BZ 1;
BA_ "GenSigSendType" SG_ 1283 HVK_01_BZ 0;
BA_ "GenSigSwitchedByIgnition" SG_ 1283 HVK_Istmodus_Anf 0;
BA_ "GenSigSendType" SG_ 1283 HVK_Istmodus_Anf 3;
BA_ "GenSigSwitchedByIgnition" SG_ 1283 HVK_MO_EmSollzustand 0;
BA_ "GenSigStartValue" SG_ 1283 HVK_MO_EmSollzustand 255;
BA_ "GenSigSendType" SG_ 1283 HVK_MO_EmSollzustand 3;
BA_ "GenSigSwitchedByIgnition" SG_ 1283 HVK_BMS_Sollmodus 0;
BA_ "GenSigStartValue" SG_ 1283 HVK_BMS_Sollmodus 7;
BA_ "GenSigSendType" SG_ 1283 HVK_BMS_Sollmodus 3;
BA_ "GenSigSwitchedByIgnition" SG_ 1283 HVK_DCDC_Sollmodus 0;
BA_ "GenSigStartValue" SG_ 1283 HVK_DCDC_Sollmodus 7;
BA_ "GenSigSendType" SG_ 1283 HVK_DCDC_Sollmodus 3;
BA_ "GenSigSwitchedByIgnition" SG_ 1283 HVK_EKK_Sollmodus 0;
BA_ "GenSigStartValue" SG_ 1283 HVK_EKK_Sollmodus 7;
BA_ "GenSigSendType" SG_ 1283 HVK_EKK_Sollmodus 3;
BA_ "GenSigSwitchedByIgnition" SG_ 1283 HVK_HVPTC_Sollmodus 0;
BA_ "GenSigStartValue" SG_ 1283 HVK_HVPTC_Sollmodus 7;
BA_ "GenSigSendType" SG_ 1283 HVK_HVPTC_Sollmodus 3;
BA_ "GenSigSwitchedByIgnition" SG_ 1283 HVK_HVLM_Sollmodus 0;
BA_ "GenSigStartValue" SG_ 1283 HVK_HVLM_Sollmodus 7;
BA_ "GenSigSendType" SG_ 1283 HVK_HVLM_Sollmodus 3;
BA_ "GenSigSwitchedByIgnition" SG_ 1283 HVK_HV_Netz_Warnungen 0;
BA_ "GenSigSendType" SG_ 1283 HVK_HV_Netz_Warnungen 3;
BA_ "GenSigSwitchedByIgnition" SG_ 1283 HV_Bordnetz_aktiv 0;
BA_ "GenSigSendType" SG_ 1283 HV_Bordnetz_aktiv 3;
BA_ "Fehlerwert" SG_ 1283 HV_Bordnetz_Fehler 1;
BA_ "GenSigSwitchedByIgnition" SG_ 1283 HV_Bordnetz_Fehler 0;
BA_ "GenSigSendType" SG_ 1283 HV_Bordnetz_Fehler 3;
BA_ "Fehlerwert" SG_ 1283 HVK_Gesamtst_Spgfreiheit 3;
BA_ "GenSigSwitchedByIgnition" SG_ 1283 HVK_Gesamtst_Spgfreiheit 0;
BA_ "GenSigSendType" SG_ 1283 HVK_Gesamtst_Spgfreiheit 0;
BA_ "GenSigSwitchedByIgnition" SG_ 1283 HVK_AktiveEntladung_Anf 0;
BA_ "GenSigSendType" SG_ 1283 HVK_AktiveEntladung_Anf 3;
BA_REL_ "GenSigTimeoutTime" BU_SG_REL_ BCM2 SG_ 262 ESP_05_CRC 500;
BA_REL_ "GenSigTimeoutTime" BU_SG_REL_ BCM2 SG_ 262 ESP_05_BZ 500;
BA_REL_ "GenSigTimeoutTime" BU_SG_REL_ AAG SG_ 262 ESC_Bremslicht 500;
BA_REL_ "GenSigTimeoutTime" BU_SG_REL_ BCM2 SG_ 262 ESC_Bremslicht 500;
BA_REL_ "GenSigTimeoutTime" BU_SG_REL_ MSBBR SG_ 262 ESC_Bremslicht 500;
BA_REL_ "GenSigTimeoutTime" BU_SG_REL_ BCM1 SG_ 914 ESP_Codierung_ADS 800;
BA_REL_ "GenSigTimeoutTime" BU_SG_REL_ BCM2 SG_ 914 ESP_Rollenmodus_Deaktivieren 800;
BA_REL_ "GenSigTimeoutTime" BU_SG_REL_ BCM1 SG_ 278 ESP_10_CRC 500;
BA_REL_ "GenSigTimeoutTime" BU_SG_REL_ ELV SG_ 278 ESP_10_CRC 500;
BA_REL_ "GenSigTimeoutTime" BU_SG_REL_ BCM1 SG_ 278 ESP_10_BZ 500;
BA_REL_ "GenSigTimeoutTime" BU_SG_REL_ ELV SG_ 278 ESP_10_BZ 500;
BA_REL_ "GenSigTimeoutTime" BU_SG_REL_ BCM1 SG_ 278 ESP_QBit_Wegimpuls_VL 500;
BA_REL_ "GenSigTimeoutTime" BU_SG_REL_ ELV SG_ 278 ESP_QBit_Wegimpuls_VL 500;
BA_REL_ "GenSigTimeoutTime" BU_SG_REL_ BCM1 SG_ 278 ESP_QBit_Wegimpuls_VR 500;
BA_REL_ "GenSigTimeoutTime" BU_SG_REL_ ELV SG_ 278 ESP_QBit_Wegimpuls_VR 500;
BA_REL_ "GenSigTimeoutTime" BU_SG_REL_ BCM1 SG_ 278 ESP_QBit_Wegimpuls_HL 500;
BA_REL_ "GenSigTimeoutTime" BU_SG_REL_ ELV SG_ 278 ESP_QBit_Wegimpuls_HL 500;
BA_REL_ "GenSigTimeoutTime" BU_SG_REL_ BCM1 SG_ 278 ESP_QBit_Wegimpuls_HR 500;
BA_REL_ "GenSigTimeoutTime" BU_SG_REL_ ELV SG_ 278 ESP_QBit_Wegimpuls_HR 500;
BA_REL_ "GenSigTimeoutTime" BU_SG_REL_ BCM1 SG_ 278 ESP_Wegimpuls_VL 500;
BA_REL_ "GenSigTimeoutTime" BU_SG_REL_ ELV SG_ 278 ESP_Wegimpuls_VL 500;
BA_REL_ "GenSigTimeoutTime" BU_SG_REL_ BCM1 SG_ 278 ESP_Wegimpuls_VR 500;
BA_REL_ "GenSigTimeoutTime" BU_SG_REL_ ELV SG_ 278 ESP_Wegimpuls_VR 500;
BA_REL_ "GenSigTimeoutTime" BU_SG_REL_ BCM1 SG_ 278 ESP_Wegimpuls_HL 500;
BA_REL_ "GenSigTimeoutTime" BU_SG_REL_ ELV SG_ 278 ESP_Wegimpuls_HL 500;
BA_REL_ "GenSigTimeoutTime" BU_SG_REL_ BCM1 SG_ 278 ESP_Wegimpuls_HR 500;
BA_REL_ "GenSigTimeoutTime" BU_SG_REL_ ELV SG_ 278 ESP_Wegimpuls_HR 500;
BA_REL_ "GenSigTimeoutTime" BU_SG_REL_ BCM1 SG_ 278 ESP_VL_Fahrtrichtung 500;
BA_REL_ "GenSigTimeoutTime" BU_SG_REL_ BCM1 SG_ 278 ESP_VR_Fahrtrichtung 500;
BA_REL_ "GenSigTimeoutTime" BU_SG_REL_ BCM1 SG_ 278 ESP_HL_Fahrtrichtung 500;
BA_REL_ "GenSigTimeoutTime" BU_SG_REL_ BCM1 SG_ 278 ESP_HR_Fahrtrichtung 500;
BA_REL_ "GenSigTimeoutTime" BU_SG_REL_ BCM1 SG_ 418 HMS_Systemstatus 2000;
BA_REL_ "GenSigTimeoutTime" BU_SG_REL_ BCM1 SG_ 418 HMS_Stillstand 2000;
BA_REL_ "GenSigTimeoutTime" BU_SG_REL_ BCM1 SG_ 418 HMS_aktives_System 2000;
BA_REL_ "GenSigTimeoutTime" BU_SG_REL_ BCM2 SG_ 1629 ESP_Zaehnezahl 5000;
BA_REL_ "GenSigTimeoutTime" BU_SG_REL_ AAG SG_ 253 ESP_21_CRC 500;
BA_REL_ "GenSigTimeoutTime" BU_SG_REL_ BCM1 SG_ 253 ESP_21_CRC 500;
BA_REL_ "GenSigTimeoutTime" BU_SG_REL_ BCM2 SG_ 253 ESP_21_CRC 500;
BA_REL_ "GenSigTimeoutTime" BU_SG_REL_ ELV SG_ 253 ESP_21_CRC 500;
BA_REL_ "GenSigTimeoutTime" BU_SG_REL_ IEZS SG_ 253 ESP_21_CRC 500;
BA_REL_ "GenSigTimeoutTime" BU_SG_REL_ MSBBR SG_ 253 ESP_21_CRC 500;
BA_REL_ "GenSigTimeoutTime" BU_SG_REL_ SitzMem_BFS SG_ 253 ESP_21_CRC 500;
BA_REL_ "GenSigTimeoutTime" BU_SG_REL_ SitzMem_FS SG_ 253 ESP_21_CRC 500;
BA_REL_ "GenSigTimeoutTime" BU_SG_REL_ SitzMem_HBFS SG_ 253 ESP_21_CRC 500;
BA_REL_ "GenSigTimeoutTime" BU_SG_REL_ SitzMem_HFS SG_ 253 ESP_21_CRC 500;
BA_REL_ "GenSigTimeoutTime" BU_SG_REL_ SitzMem_SR3 SG_ 253 ESP_21_CRC 500;
BA_REL_ "GenSigTimeoutTime" BU_SG_REL_ SpoilerSG SG_ 253 ESP_21_CRC 500;
BA_REL_ "GenSigTimeoutTime" BU_SG_REL_ AAG SG_ 253 ESP_21_BZ 500;
BA_REL_ "GenSigTimeoutTime" BU_SG_REL_ BCM1 SG_ 253 ESP_21_BZ 500;
BA_REL_ "GenSigTimeoutTime" BU_SG_REL_ BCM2 SG_ 253 ESP_21_BZ 500;
BA_REL_ "GenSigTimeoutTime" BU_SG_REL_ ELV SG_ 253 ESP_21_BZ 500;
BA_REL_ "GenSigTimeoutTime" BU_SG_REL_ IEZS SG_ 253 ESP_21_BZ 500;
BA_REL_ "GenSigTimeoutTime" BU_SG_REL_ MSBBR SG_ 253 ESP_21_BZ 500;
BA_REL_ "GenSigTimeoutTime" BU_SG_REL_ SitzMem_BFS SG_ 253 ESP_21_BZ 500;
BA_REL_ "GenSigTimeoutTime" BU_SG_REL_ SitzMem_FS SG_ 253 ESP_21_BZ 500;
BA_REL_ "GenSigTimeoutTime" BU_SG_REL_ SitzMem_HBFS SG_ 253 ESP_21_BZ 500;
BA_REL_ "GenSigTimeoutTime" BU_SG_REL_ SitzMem_HFS SG_ 253 ESP_21_BZ 500;
BA_REL_ "GenSigTimeoutTime" BU_SG_REL_ SitzMem_SR3 SG_ 253 ESP_21_BZ 500;
BA_REL_ "GenSigTimeoutTime" BU_SG_REL_ SpoilerSG SG_ 253 ESP_21_BZ 500;
BA_REL_ "GenSigTimeoutTime" BU_SG_REL_ BCM1 SG_ 253 BR_Eingriffsmoment 500;
BA_REL_ "GenSigTimeoutTime" BU_SG_REL_ BCM1 SG_ 253 ESP_PLA_Bremseingriff 500;
BA_REL_ "GenSigTimeoutTime" BU_SG_REL_ IEZS SG_ 253 ESC_v_Signal_Qualifier_High_Low 500;
BA_REL_ "GenSigTimeoutTime" BU_SG_REL_ SpoilerSG SG_ 253 ESC_v_Signal_Qualifier_High_Low 500;
BA_REL_ "GenSigTimeoutTime" BU_SG_REL_ BCM1 SG_ 253 ESP_Vorsteuerung 500;
BA_REL_ "GenSigTimeoutTime" BU_SG_REL_ AAG SG_ 253 ESP_v_Signal 500;
BA_REL_ "GenSigTimeoutTime" BU_SG_REL_ BCM1 SG_ 253 ESP_v_Signal 500;
BA_REL_ "GenSigTimeoutTime" BU_SG_REL_ BCM2 SG_ 253 ESP_v_Signal 500;
BA_REL_ "GenSigTimeoutTime" BU_SG_REL_ ELV SG_ 253 ESP_v_Signal 500;
BA_REL_ "GenSigTimeoutTime" BU_SG_REL_ HDSG SG_ 253 ESP_v_Signal 500;
BA_REL_ "GenSigTimeoutTime" BU_SG_REL_ MFG SG_ 253 ESP_v_Signal 500;
BA_REL_ "GenSigTimeoutTime" BU_SG_REL_ MSBBR SG_ 253 ESP_v_Signal 500;
BA_REL_ "GenSigTimeoutTime" BU_SG_REL_ SAD SG_ 253 ESP_v_Signal 500;
BA_REL_ "GenSigTimeoutTime" BU_SG_REL_ SAD2 SG_ 253 ESP_v_Signal 500;
BA_REL_ "GenSigTimeoutTime" BU_SG_REL_ SitzMem_BFS SG_ 253 ESP_v_Signal 500;
BA_REL_ "GenSigTimeoutTime" BU_SG_REL_ SitzMem_FS SG_ 253 ESP_v_Signal 500;
BA_REL_ "GenSigTimeoutTime" BU_SG_REL_ SitzMem_HBFS SG_ 253 ESP_v_Signal 500;
BA_REL_ "GenSigTimeoutTime" BU_SG_REL_ SitzMem_HFS SG_ 253 ESP_v_Signal 500;
BA_REL_ "GenSigTimeoutTime" BU_SG_REL_ SitzMem_SR3 SG_ 253 ESP_v_Signal 500;
BA_REL_ "GenSigTimeoutTime" BU_SG_REL_ SpoilerSG SG_ 253 ESP_v_Signal 500;
BA_REL_ "GenSigTimeoutTime" BU_SG_REL_ TSG_BFS SG_ 253 ESP_v_Signal 500;
BA_REL_ "GenSigTimeoutTime" BU_SG_REL_ TSG_FS SG_ 253 ESP_v_Signal 500;
BA_REL_ "GenSigTimeoutTime" BU_SG_REL_ VSG SG_ 253 ESP_v_Signal 500;
BA_REL_ "GenSigTimeoutTime" BU_SG_REL_ VTS SG_ 253 ESP_v_Signal 500;
BA_REL_ "GenSigTimeoutTime" BU_SG_REL_ BCM1 SG_ 253 ASR_Tastung_passiv 500;
BA_REL_ "GenSigTimeoutTime" BU_SG_REL_ BCM1 SG_ 253 ESP_Tastung_passiv 500;
BA_REL_ "GenSigTimeoutTime" BU_SG_REL_ BCM1 SG_ 253 ESP_Systemstatus 500;
BA_REL_ "GenSigTimeoutTime" BU_SG_REL_ BCM1 SG_ 253 ASR_Schalteingriff 500;
BA_REL_ "GenSigTimeoutTime" BU_SG_REL_ BCM1 SG_ 253 ESP_Haltebestaetigung 500;
BA_REL_ "GenSigTimeoutTime" BU_SG_REL_ BCM1 SG_ 253 ESP_QBit_v_Signal 500;
BA_REL_ "GenSigTimeoutTime" BU_SG_REL_ BCM2 SG_ 253 ESP_QBit_v_Signal 500;
BA_REL_ "GenSigTimeoutTime" BU_SG_REL_ ELV SG_ 253 ESP_QBit_v_Signal 500;
BA_REL_ "GenSigTimeoutTime" BU_SG_REL_ SitzMem_BFS SG_ 253 ESP_QBit_v_Signal 500;
BA_REL_ "GenSigTimeoutTime" BU_SG_REL_ SitzMem_FS SG_ 253 ESP_QBit_v_Signal 500;
BA_REL_ "GenSigTimeoutTime" BU_SG_REL_ SitzMem_SR3 SG_ 253 ESP_QBit_v_Signal 500;
BA_REL_ "GenSigTimeoutTime" BU_SG_REL_ SpoilerSG SG_ 253 ESP_QBit_v_Signal 500;
BA_REL_ "GenSigTimeoutTime" BU_SG_REL_ BCM1 SG_ 253 ABS_Bremsung 500;
BA_REL_ "GenSigTimeoutTime" BU_SG_REL_ MSBBR SG_ 253 ABS_Bremsung 500;
BA_REL_ "GenSigTimeoutTime" BU_SG_REL_ BCM1 SG_ 253 ASR_Anf 500;
BA_REL_ "GenSigTimeoutTime" BU_SG_REL_ BCM1 SG_ 253 MSR_Anf 500;
BA_REL_ "GenSigTimeoutTime" BU_SG_REL_ BCM1 SG_ 253 EBV_Eingriff 500;
BA_REL_ "GenSigTimeoutTime" BU_SG_REL_ BCM1 SG_ 253 EDS_Eingriff 500;
BA_REL_ "GenSigTimeoutTime" BU_SG_REL_ BCM1 SG_ 253 ESP_Eingriff 500;
BA_REL_ "GenSigTimeoutTime" BU_SG_REL_ BCM1 SG_ 253 ESP_ASP 500;
BA_REL_ "GenSigTimeoutTime" BU_SG_REL_ VTS SG_ 795 BK_Lampe_02 5000;
BA_REL_ "GenSigTimeoutTime" BU_SG_REL_ VTS SG_ 795 ESP_Textanzeigen_03 5000;
BA_REL_ "GenSigTimeoutTime" BU_SG_REL_ VTS SG_ 795 ESP_BKV_Warnung 5000;
BA_REL_ "GenSigTimeoutTime" BU_SG_REL_ BCM1 SG_ 508 ESP_Stillstandsflag 1000;
BA_REL_ "GenSigTimeoutTime" BU_SG_REL_ BCM2 SG_ 508 ESP_Stillstandsflag 1000;
BA_REL_ "GenSigTimeoutTime" BU_SG_REL_ BCM1 SG_ 508 ESP_AVH_LED 1000;
BA_REL_ "GenSigTimeoutTime" BU_SG_REL_ BCM1 SG_ 508 ESP_HDC_LED 1000;
BA_REL_ "GenSigTimeoutTime" BU_SG_REL_ BCM1 SG_ 508 ESP_Off_LED 1000;
BA_REL_ "GenSigTimeoutTime" BU_SG_REL_ VTS SG_ 508 ESP_Off_LED 1000;
BA_REL_ "GenSigTimeoutTime" BU_SG_REL_ BCM2 SG_ 508 ESP_Notbremsanzeige 1000;
BA_REL_ "GenSigTimeoutTime" BU_SG_REL_ SAD SG_ 508 ESP_Notbremsanzeige 1000;
BA_REL_ "GenSigTimeoutTime" BU_SG_REL_ BCM1 SG_ 427 ESC_AHW_aktiv 2000;
BA_REL_ "GenSigTimeoutTime" BU_SG_REL_ BCM1 SG_ 427 ESC_AHW_nicht_verfuegbar 2000;
BA_REL_ "GenSigTimeoutTime" BU_SG_REL_ BCM1 SG_ 427 ESC_Verz_Reg_aktiv 2000;
BA_REL_ "GenSigTimeoutTime" BU_SG_REL_ BCM1 SG_ 427 ESC_Verz_Reg_nicht_verfuegbar 2000;
BA_REL_ "GenSigTimeoutTime" BU_SG_REL_ BCM1 SG_ 427 ESC_Verz_Reg_ZB_nicht_verfuegbar 2000;
BA_REL_ "GenSigTimeoutTime" BU_SG_REL_ BCM1 SG_ 427 ESC_Konsistenz_ARA 2000;
BA_REL_ "GenSigTimeoutTime" BU_SG_REL_ BCM1 SG_ 427 ESC_Konsistenz_IPA 2000;
BA_REL_ "GenSigTimeoutTime" BU_SG_REL_ BCM2 SG_ 2589283470 ESC_Kilometer 5000;
BA_REL_ "GenSigTimeoutTime" BU_SG_REL_ BCM2 SG_ 2589283470 ESC_Kilometer_MUX 5000;
BA_REL_ "GenSigTimeoutTime" BU_SG_REL_ BCM2 SG_ 2589283470 ESC_Signatur_Kilometer_GFA_01 5000;
BA_REL_ "GenSigTimeoutTime" BU_SG_REL_ BCM2 SG_ 2589283470 ESC_Signatur_Kilometer_IKA_01 5000;
BA_REL_ "GenSigTimeoutTime" BU_SG_REL_ BCM2 SG_ 2589283470 ESC_Signatur_Kilometer_GFA_02 5000;
BA_REL_ "GenSigTimeoutTime" BU_SG_REL_ BCM2 SG_ 2589283470 ESC_Signatur_Kilometer_IKA_02 5000;
BA_REL_ "GenSigTimeoutTime" BU_SG_REL_ BCM1 SG_ 264 FA_Hoehenwerte_kalibriert 500;
BA_REL_ "GenSigTimeoutTime" BU_SG_REL_ BCM1 SG_ 264 FA_Hoehenwert_VL_00 500;
BA_REL_ "GenSigTimeoutTime" BU_SG_REL_ BCM1 SG_ 264 FA_Hoehenwert_HL_00 500;
BA_REL_ "GenSigTimeoutTime" BU_SG_REL_ BCM1 SG_ 429 NR_Reglerstatus 5000;
BA_REL_ "GenSigTimeoutTime" BU_SG_REL_ BCM1 SG_ 429 NR_LED_SGN 5000;
BA_REL_ "GenSigTimeoutTime" BU_SG_REL_ BCM1 SG_ 429 NR_LED_TN 5000;
BA_REL_ "GenSigTimeoutTime" BU_SG_REL_ BCM1 SG_ 429 NR_LED_BN 5000;
BA_REL_ "GenSigTimeoutTime" BU_SG_REL_ BCM1 SG_ 429 NR_LED_HN 5000;
BA_REL_ "GenSigTimeoutTime" BU_SG_REL_ BCM1 SG_ 1605 FLA_aktiv 5000;
BA_REL_ "GenSigTimeoutTime" BU_SG_REL_ BCM1 SG_ 1605 FLA_ISP_defekt 5000;
BA_REL_ "GenSigTimeoutTime" BU_SG_REL_ BCM1 SG_ 1605 FLA_Sensor_blockiert 5000;
BA_REL_ "GenSigTimeoutTime" BU_SG_REL_ BCM1 SG_ 1605 FLA_Fernlicht_PWM 5000;
BA_REL_ "GenSigTimeoutTime" BU_SG_REL_ TSG_BFS SG_ 1605 ISP_Dimmung_ASP_02 5000;
BA_REL_ "GenSigTimeoutTime" BU_SG_REL_ TSG_FS SG_ 1605 ISP_Dimmung_ASP_02 5000;
BA_REL_ "GenSigTimeoutTime" BU_SG_REL_ BCM1 SG_ 1605 FLA_Aufblenden 5000;
BA_REL_ "GenSigTimeoutTime" BU_SG_REL_ SitzMem_BFS SG_ 1726 FSS_Laenge_Pos 5000;
BA_REL_ "GenSigTimeoutTime" BU_SG_REL_ SitzMem_BFS SG_ 1726 FSS_Hoehe_Pos 5000;
BA_REL_ "GenSigTimeoutTime" BU_SG_REL_ SitzMem_BFS SG_ 1726 FSS_Kopfstuetze_Pos 5000;
BA_REL_ "GenSigTimeoutTime" BU_SG_REL_ SitzMem_BFS SG_ 1726 FSS_Neigung_Lehne_Pos 5000;
BA_REL_ "GenSigTimeoutTime" BU_SG_REL_ SitzMem_BFS SG_ 1727 FSS_Lehnenkopf_Pos 5000;
BA_REL_ "GenSigTimeoutTime" BU_SG_REL_ SitzMem_BFS SG_ 1727 FSS_Neigung_Sitz_Pos 5000;
BA_REL_ "GenSigTimeoutTime" BU_SG_REL_ SitzMem_BFS SG_ 1727 FSS_KopfstuetzeX_Pos 5000;
BA_REL_ "GenSigTimeoutTime" BU_SG_REL_ BCM1 SG_ 173 GE_Fahrstufe 1000;
BA_REL_ "GenSigTimeoutTime" BU_SG_REL_ BCM2 SG_ 173 GE_Fahrstufe 1000;
BA_REL_ "GenSigTimeoutTime" BU_SG_REL_ ELV SG_ 173 GE_Fahrstufe 1000;
BA_REL_ "GenSigTimeoutTime" BU_SG_REL_ MFG SG_ 173 GE_Fahrstufe 1000;
BA_REL_ "GenSigTimeoutTime" BU_SG_REL_ BCM1 SG_ 173 GE_Zielgang 1000;
BA_REL_ "GenSigTimeoutTime" BU_SG_REL_ BCM2 SG_ 968 GE_Freigabe_Verfallsinfo_WFS 800;
BA_REL_ "GenSigTimeoutTime" BU_SG_REL_ BCM2 SG_ 968 GE_Freigabe_Info_WFS 800;
BA_REL_ "GenSigTimeoutTime" BU_SG_REL_ BCM2 SG_ 968 GE_Sperr_Info_WFS 800;
BA_REL_ "GenSigTimeoutTime" BU_SG_REL_ BCM1 SG_ 310 HAL_01_CRC 500;
BA_REL_ "GenSigTimeoutTime" BU_SG_REL_ BCM1 SG_ 310 HAL_01_BZ 500;
BA_REL_ "GenSigTimeoutTime" BU_SG_REL_ BCM1 SG_ 310 HAL_Status 500;
BA_REL_ "GenSigTimeoutTime" BU_SG_REL_ BCM1 SG_ 310 HAL_VZ_Radwinkel 500;
BA_REL_ "GenSigTimeoutTime" BU_SG_REL_ BCM1 SG_ 310 HAL_QBit_Radwinkel 500;
BA_REL_ "GenSigTimeoutTime" BU_SG_REL_ BCM1 SG_ 310 HAL_Radwinkel 500;
BA_REL_ "GenSigTimeoutTime" BU_SG_REL_ BCM1 SG_ 310 HAL_VZ_Fahrerwunschwinkel_Soll 500;
BA_REL_ "GenSigTimeoutTime" BU_SG_REL_ BCM1 SG_ 310 HAL_Fahrerwunschwinkel_Soll 500;
BA_REL_ "GenSigTimeoutTime" BU_SG_REL_ BCM1 SG_ 676 HAL_02_CRC 500;
BA_REL_ "GenSigTimeoutTime" BU_SG_REL_ BCM1 SG_ 676 HAL_02_BZ 500;
BA_REL_ "GenSigTimeoutTime" BU_SG_REL_ BCM1 SG_ 676 HAL_ARA_Status 500;
BA_REL_ "GenSigTimeoutTime" BU_SG_REL_ BCM1 SG_ 676 HAL_PLA_Status 500;
BA_REL_ "GenSigTimeoutTime" BU_SG_REL_ BCM1 SG_ 676 HAL_PWR_Abbruch 500;
BA_REL_ "GenSigTimeoutTime" BU_SG_REL_ BCM1 SG_ 676 HAL_PWR_Fehler 500;
BA_REL_ "GenSigTimeoutTime" BU_SG_REL_ BCM2 SG_ 1410 HD_Bewegung_auf 2000;
BA_REL_ "GenSigTimeoutTime" BU_SG_REL_ BCM2 SG_ 1410 HD_Bewegung_zu 2000;
BA_REL_ "GenSigTimeoutTime" BU_SG_REL_ AAG SG_ 1410 HD_Innentaster_betaetigt 2000;
BA_REL_ "GenSigTimeoutTime" BU_SG_REL_ BCM1 SG_ 1410 HD_Position 2000;
BA_REL_ "GenSigTimeoutTime" BU_SG_REL_ BCM2 SG_ 1410 HD_Position 2000;
BA_REL_ "GenSigTimeoutTime" BU_SG_REL_ BCM2 SG_ 1410 HD_Rueckmeld_prog 2000;
BA_REL_ "GenSigTimeoutTime" BU_SG_REL_ AAG SG_ 1410 HD_Verriegelungstaster_betaetigt 2000;
BA_REL_ "GenSigTimeoutTime" BU_SG_REL_ BCM2 SG_ 1410 HD_Verriegelungstaster_betaetigt 2000;
BA_REL_ "GenSigTimeoutTime" BU_SG_REL_ BCM2 SG_ 1410 HD_Verr_Taster_betaetigt_inv 2000;
BA_REL_ "GenSigTimeoutTime" BU_SG_REL_ BCM2 SG_ 1410 HD_ZZH_Schalter_S3 2000;
BA_REL_ "GenSigTimeoutTime" BU_SG_REL_ Gateway SG_ 1416 KRH_Stufe_LED_li 5000;
BA_REL_ "GenSigTimeoutTime" BU_SG_REL_ Gateway SG_ 1416 KRH_Stufe_LED_re 5000;
BA_REL_ "GenSigTimeoutTime" BU_SG_REL_ Gateway SG_ 1416 BCM1_TCH_HLR_Anf 5000;
BA_REL_ "GenSigTimeoutTime" BU_SG_REL_ BCM1 SG_ 1016 HLR_FlHz_Freigabe_Ruhesitz 5000;
BA_REL_ "GenSigTimeoutTime" BU_SG_REL_ BCM1 SG_ 1016 HLR_FlHz_Freigabe_VR 5000;
BA_REL_ "GenSigTimeoutTime" BU_SG_REL_ BCM1 SG_ 1016 HLR_FlHz_Freigabe_VL 5000;
BA_REL_ "GenSigTimeoutTime" BU_SG_REL_ BCM1 SG_ 1016 HLR_FlHz_Freigabe_HR 5000;
BA_REL_ "GenSigTimeoutTime" BU_SG_REL_ BCM1 SG_ 1016 HLR_FlHz_Freigabe_HL 5000;
BA_REL_ "GenSigTimeoutTime" BU_SG_REL_ BCM1 SG_ 1016 HLR_TCH_Freigabe 5000;
BA_REL_ "GenSigTimeoutTime" BU_SG_REL_ BCM1 SG_ 1016 HLR_SIH_Freigabe_Fond 5000;
BA_REL_ "GenSigTimeoutTime" BU_SG_REL_ TSG_BFS SG_ 1016 HLR_Sp_Heizung_Freigabe_BT 5000;
BA_REL_ "GenSigTimeoutTime" BU_SG_REL_ TSG_FS SG_ 1016 HLR_Sp_Heizung_Freigabe_BT 5000;
BA_REL_ "GenSigTimeoutTime" BU_SG_REL_ TSG_BFS SG_ 1016 HLR_Sp_Heizung_Freigabe_FT 5000;
BA_REL_ "GenSigTimeoutTime" BU_SG_REL_ TSG_FS SG_ 1016 HLR_Sp_Heizung_Freigabe_FT 5000;
BA_REL_ "GenSigTimeoutTime" BU_SG_REL_ BCM1 SG_ 1016 HLR_KRH_Freigabe_VL 5000;
BA_REL_ "GenSigTimeoutTime" BU_SG_REL_ BCM1 SG_ 1016 HLR_KRH_Freigabe_VR 5000;
BA_REL_ "GenSigTimeoutTime" BU_SG_REL_ BCM1 SG_ 1016 HLR_SIH_Freigabe_VL 5000;
BA_REL_ "GenSigTimeoutTime" BU_SG_REL_ BCM1 SG_ 1016 HLR_SIH_Freigabe_VR 5000;
BA_REL_ "GenSigTimeoutTime" BU_SG_REL_ BCM1 SG_ 1016 HLR_SIH_Freigabe_HL 5000;
BA_REL_ "GenSigTimeoutTime" BU_SG_REL_ BCM1 SG_ 1016 HLR_SIH_Freigabe_HR 5000;
BA_REL_ "GenSigTimeoutTime" BU_SG_REL_ BCM1 SG_ 1016 HLR_SIL_Freigabe_VL 5000;
BA_REL_ "GenSigTimeoutTime" BU_SG_REL_ BCM1 SG_ 1016 HLR_SIL_Freigabe_VR 5000;
BA_REL_ "GenSigTimeoutTime" BU_SG_REL_ BCM1 SG_ 1016 HLR_SIL_Freigabe_HL 5000;
BA_REL_ "GenSigTimeoutTime" BU_SG_REL_ BCM1 SG_ 1016 HLR_SIL_Freigabe_HR 5000;
BA_REL_ "GenSigTimeoutTime" BU_SG_REL_ BCM2 SG_ 1016 HLR_FSH_Freigabe 5000;
BA_REL_ "GenSigTimeoutTime" BU_SG_REL_ BCM2 SG_ 1016 HLR_HSH_Freigabe 5000;
BA_REL_ "GenSigTimeoutTime" BU_SG_REL_ BCM1 SG_ 1016 HLR_PTC_Freigabe 5000;
BA_REL_ "GenSigTimeoutTime" BU_SG_REL_ VTS SG_ 1412 HSP_Endlage_eingefahren 1600;
BA_REL_ "GenSigTimeoutTime" BU_SG_REL_ VTS SG_ 1412 HSP_Endlage_ausgefahren 1600;
BA_REL_ "GenSigTimeoutTime" BU_SG_REL_ Gateway SG_ 1412 HSP_Charisma_FahrPr 1600;
BA_REL_ "GenSigTimeoutTime" BU_SG_REL_ Gateway SG_ 1412 HSP_Charisma_Status 1600;
BA_REL_ "GenSigTimeoutTime" BU_SG_REL_ BCM2 SG_ 1283 HV_Bordnetz_Fehler 1000;
VAL_ 262 ESP_QBit_Bremsdruck 0 "gueltiger_Wert" 1 "Ersatz_Init_oder_Fehlerwert" ;
VAL_ 262 ESP_QBit_Fahrer_bremst 0 "gueltiger_Wert" 1 "Ersatz_Init_oder_Fehlerwert" ;
VAL_ 262 ESP_Schwelle_Unterdruck 0 "kein_Signal" 1 "Unterdruck_kleiner_gleich_450_mbar" 2 "Unterdruck_groesser_450_mbar" 3 "Fehler_Unterdrucksensor" ;
VAL_ 262 ESP_Bremsdruck 1023 "Fehler" ;
VAL_ 262 ESP_Fahrer_bremst 0 "Bremsdruckschwelle_nicht_ueberschritten" 1 "Bremsdruckschwelle_ueberschritten" ;
VAL_ 262 ESP_Lenkeingriff_ADS 0 "kein_Lenkeingriff" 1 "stabilisierender_Lenkeingriff" ;
VAL_ 262 ECD_Fehler 0 "ECD_iO" 1 "ECD_Fehler" ;
VAL_ 262 ECD_nicht_verfuegbar 0 "ECD_Funktion_verfuegbar" 1 "ECD_Funktion_nicht_verfuegbar" ;
VAL_ 262 ESP_Status_Bremsentemp 0 "Bremse_nicht_ueberhitzt" 1 "Bremse_ueberhitzt" ;
VAL_ 262 ESP_Autohold_Standby 0 "Autohold_nicht_im_Standby" 1 "Autohold_im_Standby" ;
VAL_ 262 ESP_HDC_Standby 0 "HDC_Funktion_nicht_im_Standby" 1 "HDC_Funktion_im_Standby" ;
VAL_ 262 ESP_HBA_aktiv 0 "HBA_nicht_aktiv" 1 "HBA_aktiv" ;
VAL_ 262 ESP_Prefill_ausgeloest 0 "nicht_ausgeloest" 1 "Prefill_ausgeloest" ;
VAL_ 262 ESP_Rueckwaertsfahrt_erkannt 0 "keine_Rueckwaetsfahrt" 1 "Rueckwaertsfahrt_sicher_erkannt" ;
VAL_ 262 ESP_Status_Anfahrhilfe 0 "Aus" 1 "Ein" ;
VAL_ 262 ESP_HDC_aktiv 0 "inaktiv" 1 "aktiv" ;
VAL_ 262 ESP_StartStopp_Info 0 "Motorlauf_nicht_notwendig_(Stoppfreigabe)" 1 "Motoranlauf_nicht_zwingend_notwendig_(Stoppverbot,keine_Startanforderung)" 2 "Motoranlauf_zwingend_notwendig_(Startanforderung)" 3 "Systemfehler" ;
VAL_ 262 ESP_Eingr_HL 0 "kein_Eingriff" 1 "ESP_Eingriff_HL" ;
VAL_ 262 ESP_Eingr_HR 0 "kein_Eingriff" 1 "ESP_Eingriff_HR" ;
VAL_ 262 ESP_Eingr_VL 0 "kein_Eingriff" 1 "ESP_Eingriff_VL" ;
VAL_ 262 ESP_Eingr_VR 0 "kein_Eingriff" 1 "ESP_Eingriff_VR" ;
VAL_ 262 ESP_BKV_Unterdruck 0 "nicht_verbaut_oder_nicht_kodiert" 254 "Init" 255 "Fehler" ;
VAL_ 262 ESP_Autohold_aktiv 0 "Autohold_inaktiv" 1 "Autohold_aktiv" ;
VAL_ 262 ESP_FStatus_Anfahrhilfe 0 "kein_Fehler" 1 "Fehler" ;
VAL_ 262 ESP_Verz_EPB_aktiv 0 "nicht_aktiviert" 1 "aktiviert" ;
VAL_ 262 ESC_Bremslicht 0 "Aus" 1 "Ein" ;
VAL_ 262 ESP_Verzoeg_EPB_verf 0 "nicht_verfuegbar" 1 "System_verfuegbar" ;
VAL_ 262 ESP_Status_Bremsdruck 0 "Bremse_drucklos" 1 "mit_Bremsdruck" ;
VAL_ 262 ESP_Anforderung_EPB 0 "keine_Anforderung" 1 "Anforderung_Oeffnen" 2 "Anforderung_Schliessen" 3 "reserviert" ;
VAL_ 914 ESP_ACC_LDE 0 "Lebensdauerende_nicht_erreicht" 1 "Lebensdauerende_erreicht" ;
VAL_ 914 ESP_Allrad_Antrieb 0 "Front" 1 "Allrad" ;
VAL_ 914 ESP_Codierung_ADS 0 "Init" 1 "ESP_nicht_ADS_codiert" 2 "ADS_codiert" 3 "tbd" ;
VAL_ 914 ESP_RTA_HL 254 "Abgleich_nocht_nicht_genuegend_konvergent" 255 "Fehler" ;
VAL_ 914 ESP_RTA_HR 254 "Abgleich_nocht_nicht_genuegend_konvergent" 255 "Fehler" ;
VAL_ 914 ESP_RTA_VR 254 "Abgleich_nocht_nicht_genuegend_konvergent" 255 "Fehler" ;
VAL_ 914 OBD_Fehler_Radsensor_HL 0 "kein Fehler / Init / nicht verbaut" 1 "KS- (Kurzschluss nach minus)" 2 "KS+ (Kurzschluss nach plus)" 3 "OC (Leitungsunterbrechung)" 4 "OOR+ (Signal zu gross)" 5 "OOR- (Signal zu klein)" 6 "RC+ (Signal unplausibel zu gross)" 7 "RC- (Signal unplausibel zu klein)" 8 "KS+/OC (Kurzschluss nach plus/Unterbrechung)" 9 "KS-/OC  (Kurzschluss nach minus/Unterbrechung)" 10 "KS-/KS+  (Kurzschluss nach minus/plus)" 11 "KS-/KS+/OC (Kurzschluss nach minus/plus/Unterbrechung)" 12 "frei" 13 "frei" 14 "frei" 15 "frei" ;
VAL_ 914 OBD_Fehler_Radsensor_HR 0 "kein Fehler / Init / nicht verbaut" 1 "KS- (Kurzschluss nach minus)" 2 "KS+ (Kurzschluss nach plus)" 3 "OC (Leitungsunterbrechung)" 4 "OOR+ (Signal zu gross)" 5 "OOR- (Signal zu klein)" 6 "RC+ (Signal unplausibel zu gross)" 7 "RC- (Signal unplausibel zu klein)" 8 "KS+/OC (Kurzschluss nach plus/Unterbrechung)" 9 "KS-/OC  (Kurzschluss nach minus/Unterbrechung)" 10 "KS-/KS+  (Kurzschluss nach minus/plus)" 11 "KS-/KS+/OC (Kurzschluss nach minus/plus/Unterbrechung)" 12 "frei" 13 "frei" 14 "frei" 15 "frei" ;
VAL_ 914 OBD_Fehler_Radsensor_VL 0 "kein Fehler / Init / nicht verbaut" 1 "KS- (Kurzschluss nach minus)" 2 "KS+ (Kurzschluss nach plus)" 3 "OC (Leitungsunterbrechung)" 4 "OOR+ (Signal zu gross)" 5 "OOR- (Signal zu klein)" 6 "RC+ (Signal unplausibel zu gross)" 7 "RC- (Signal unplausibel zu klein)" 8 "KS+/OC (Kurzschluss nach plus/Unterbrechung)" 9 "KS-/OC  (Kurzschluss nach minus/Unterbrechung)" 10 "KS-/KS+  (Kurzschluss nach minus/plus)" 11 "KS-/KS+/OC (Kurzschluss nach minus/plus/Unterbrechung)" 12 "frei" 13 "frei" 14 "frei" 15 "frei" ;
VAL_ 914 OBD_Fehler_Radsensor_VR 0 "kein Fehler / Init / nicht verbaut" 1 "KS- (Kurzschluss nach minus)" 2 "KS+ (Kurzschluss nach plus)" 3 "OC (Leitungsunterbrechung)" 4 "OOR+ (Signal zu gross)" 5 "OOR- (Signal zu klein)" 6 "RC+ (Signal unplausibel zu gross)" 7 "RC- (Signal unplausibel zu klein)" 8 "KS+/OC (Kurzschluss nach plus/Unterbrechung)" 9 "KS-/OC  (Kurzschluss nach minus/Unterbrechung)" 10 "KS-/KS+  (Kurzschluss nach minus/plus)" 11 "KS-/KS+/OC (Kurzschluss nach minus/plus/Unterbrechung)" 12 "frei" 13 "frei" 14 "frei" 15 "frei" ;
VAL_ 914 ESP_Qualifizierung_Antriebsart 0 "alte_Bedeutung_Bit_ESP_Allrad_Antrieb" 1 "neue_Bedeutung_Bit_ESP_Allrad_Antrieb" ;
VAL_ 914 ESP_Offroad_Modus 0 "kein_ESP_Offroadmodus" 1 "ESP_Offroadmodus" ;
VAL_ 914 ESP_MKB_ausloesbar 0 "Multikollisionsbremsung_nicht_freigeschaltet" 1 "Multikollisionsbremsung_freigeschaltet" ;
VAL_ 914 ESP_Stat_FallBack_eBKV 0 "Rueckfallebene_nicht_vorhanden" 1 "Rueckfallebene_vorhanden" ;
VAL_ 914 ESP_CM_Variante 0 "Standard" 1 "Erweitert" ;
VAL_ 914 ESP_OBD_Status 0 "MIL_aus" 1 "MIL_ein" ;
VAL_ 914 ESP_Rollenmodus_Deaktivieren 0 "keine_Aenderung" 1 "Abbruch" ;
VAL_ 914 ESP_nachtr_Stopp_Anf 0 "nicht_angefordert" 1 "angefordert" ;
VAL_ 278 ESP_QBit_Wegimpuls_VL 0 "gueltiger_Wert" 1 "Ersatz_Init_oder_Fehlerwert" ;
VAL_ 278 ESP_QBit_Wegimpuls_VR 0 "gueltiger_Wert" 1 "Ersatz_Init_oder_Fehlerwert" ;
VAL_ 278 ESP_QBit_Wegimpuls_HL 0 "gueltiger_Wert" 1 "Ersatz_Init_oder_Fehlerwert" ;
VAL_ 278 ESP_QBit_Wegimpuls_HR 0 "gueltiger_Wert" 1 "Ersatz_Init_oder_Fehlerwert" ;
VAL_ 278 ESP_Wegimpuls_VL 1021 "Init" 1022 "Unterspannung" 1023 "Fehler" ;
VAL_ 278 ESP_Wegimpuls_VR 1021 "Init" 1022 "Unterspannung" 1023 "Fehler" ;
VAL_ 278 ESP_Wegimpuls_HL 1021 "Init" 1022 "Unterspannung" 1023 "Fehler" ;
VAL_ 278 ESP_Wegimpuls_HR 1021 "Init" 1022 "Unterspannung" 1023 "Fehler" ;
VAL_ 278 ESP_VL_Fahrtrichtung 0 "Vorwaerts" 1 "Rueckwaerts" 2 "Init" 3 "ungueltig_oder_nicht_verbaut" ;
VAL_ 278 ESP_VR_Fahrtrichtung 0 "Vorwaerts" 1 "Rueckwaerts" 2 "Init" 3 "ungueltig_oder_nicht_verbaut" ;
VAL_ 278 ESP_HL_Fahrtrichtung 0 "Vorwaerts" 1 "Rueckwaerts" 2 "Init" 3 "ungueltig_oder_nicht_verbaut" ;
VAL_ 278 ESP_HR_Fahrtrichtung 0 "Vorwaerts" 1 "Rueckwaerts" 2 "Init" 3 "ungueltig_oder_nicht_verbaut" ;
VAL_ 418 HMS_P_beibehalten_GE 0 "P_nicht_beibehalten" 1 "P_beibehalten" 2 "Init" 3 "Fehler" ;
VAL_ 418 HMS_Konsistenz_GE 0 "kein_Fehler_erkannt" 1 "Fehler_erkannt" ;
VAL_ 418 HMS_Konsistenz_IPA 0 "kein_Fehler_erkannt" 1 "Fehler_erkannt" ;
VAL_ 418 HMS_Konsistenz_EBKV 0 "kein_Fehler_erkannt" 1 "Fehler_erkannt" ;
VAL_ 418 HMS_Konsistenz_RCTA 0 "kein_Fehler_erkannt" 1 "Fehler_erkannt" ;
VAL_ 418 HMS_Konsistenz_STA 0 "kein_Fehler_erkannt" 1 "Fehler_erkannt" ;
VAL_ 418 HMS_Konsistenz_MO 0 "kein_Fehler_erkannt" 1 "Fehler_erkannt" ;
VAL_ 418 HMS_halten_nicht_verfuegbar 0 "verfuegbar" 1 "nicht_verfuegbar" ;
VAL_ 418 HMS_parken_nicht_verfuegbar 0 "verfuegbar" 1 "nicht_verfuegbar" ;
VAL_ 418 HMS_Anforderung_GE 0 "keine_Anforderung" 1 "P_einlegen" ;
VAL_ 418 HMS_Systemstatus 0 "keine_Funktion_aktiv" 1 "Halten_aktiv" 2 "Parken_angefordert" 3 "Parken_aktiv" 4 "Parken_beibehalten_aktiv" 5 "Anfahren_aktiv" 6 "Loeseanforderung_aktiv" 7 "Loeseanforderung_durch_Fahrer" 8 "Abrutschen_erkannt" 9 "Halten_Standby_aktiv" 10 "Anfahren_Standby_aktiv" 14 "Init" 15 "Fehler" ;
VAL_ 418 HMS_Stillstand 0 "kein_Stillstand" 1 "Stillstand_frueh" 2 "Stillstand" 6 "Init" 7 "Fehler" ;
VAL_ 418 HMS_aktives_System 0 "kein_System__Init_Fehler" 1 "Fahreranforderung_aktiv" 2 "HMS_intern_aktiv" 3 "ACC_aktiv" 4 "Autohold_aktiv" 5 "HHC_aktiv" 6 "HVLM_aktiv" 7 "Getriebe_aktiv" 8 "EBKV_aktiv" 9 "IPA_aktiv" 10 "ARA_aktiv" 11 "RCTA_aktiv" 12 "autonomous_Hold_aktiv" 13 "STA_aktiv" 14 "Motor_aktiv" ;
VAL_ 418 HMS_Konsistenz_HVLM 0 "kein_Fehler_erkannt" 1 "Fehler_erkannt" ;
VAL_ 418 HMS_Konsistenz_ACC 0 "kein_Fehler_erkannt" 1 "Fehler_erkannt" ;
VAL_ 418 HMS_Fehlerstatus 0 "kein_Fehler" 1 "Halten_nicht_moeglich" 2 "Sonderbetriebsmodus_aktiv" 3 "Systemeinschraenkung" 4 "Systemstoerung" ;
VAL_ 418 ESP_Index_Haltemoment 0 "Bremsmoment" 1 "Antriebsmoment" ;
VAL_ 418 ESP_Haltemoment 1022 "Init" 1023 "Fehler" ;
VAL_ 1629 BR_Systemart 0 "ABS" 1 "ABS_ASR" 2 "ESP" 3 "ESP_mit_integrierter_EPB" ;
VAL_ 1629 ESP_SpannungsAnf_02 0 "keine_Anforderung" 1 "Anforderung_Stufe1" 2 "Anforderung_Stufe2" 3 "Anforderung_Stufe3" ;
VAL_ 1629 ESP_Charisma_FahrPr 0 "keine_Funktion" 1 "Programm_1" 2 "Programm_2" 3 "Programm_3" 4 "Programm_4" 5 "Programm_5" 6 "Programm_6" 7 "Programm_7" 8 "Programm_8" 9 "Programm_9" 10 "Programm_10" 11 "Programm_11" 12 "Programm_12" 13 "Programm_13" 14 "Programm_14" 15 "Programm_15" ;
VAL_ 1629 ESP_Charisma_Status 0 "Init" 1 "verfuegbar" 2 "nicht_verfuegbar" 3 "asynchron_durch_Fahrerwunsch" ;
VAL_ 1629 ESP_Wiederstart_Anz_01 0 "keine_Anzeige" 1 "Rueckwaertsrollen" ;
VAL_ 1629 ESP_Wiederstart_Anz_02 0 "keine_Anzeige" 1 "Autohold_Rutschen" ;
VAL_ 1629 ESP_Wiederstart_Anz_03 0 "keine_Anzeige" 1 "Offroad_HDC" ;
VAL_ 1629 ESP_Wiederstart_Anz_04 0 "keine_Anzeige" 1 "ESC_Off" ;
VAL_ 1629 ESP_Stoppverbot_Anz_01 0 "keine_Anzeige" 1 "Notbremsung_aktiv" ;
VAL_ 1629 ESP_Stoppverbot_Anz_02 0 "keine_Anzeige" 1 "Autohold_AVH_Rutschen" ;
VAL_ 1629 ESP_Stoppverbot_Anz_03 0 "keine_Anzeige" 1 "Rueckwaertsrollen" ;
VAL_ 1629 ESP_Stoppverbot_Anz_04 0 "keine_Anzeige" 1 "ESP_Pumpenlauf" ;
VAL_ 1629 ESP_Stoppverbot_Anz_05 0 "keine_Anzeige" 1 "ESP_OFF" ;
VAL_ 1629 ESP_Stoppverbot_Anz_06 0 "keine_Anzeige" 1 "Offroad_HDC" ;
VAL_ 1629 ESP_Stoppverbot_Anz_07 0 "keine_Anzeige" 1 "ESP_Haltefunktion_nicht_verfuegbar" ;
VAL_ 1629 ESP_Stoppverbot_Anz_Std 0 "keine_Anzeige" 1 "Standard_Stoppvetogrund" ;
VAL_ 1629 ESP_Dachrelingsensor 0 "Sensor_nicht_verbaut" 1 "Quertraeger_montiert" 2 "Quertraeger_nicht_montiert" 3 "Fehler" ;
VAL_ 1629 ESP_Stoppverbot_Anz_08 0 "keine_Anzeige" 1 "Neigungsbegrenzung" ;
VAL_ 1629 HDC_Charisma_FahrPr 0 "keine_Funktion" 1 "Programm_1" 2 "Programm_2" 3 "Programm_3" 4 "Programm_4" 5 "Programm_5" 6 "Programm_6" 7 "Programm_7" 8 "Programm_8" 9 "Programm_9" 10 "Programm_10" 11 "Programm_11" 12 "Programm_12" 13 "Programm_13" 14 "Programm_14" 15 "Programm_15" ;
VAL_ 1629 HDC_Charisma_Status 0 "Init" 1 "verfuegbar" 2 "nicht_verfuegbar" 3 "asynchron_durch_Fahrerwunsch" ;
VAL_ 1629 BR_QBit_Reifenumfang 0 "gueltiger_Wert" 1 "Ersatz_Init_oder_Fehlerwert" ;
VAL_ 253 BR_Eingriffsmoment 1022 "Init" 1023 "Fehler" ;
VAL_ 253 ESP_PLA_Bremseingriff 0 "inaktiv" 1 "aktiv" ;
VAL_ 253 ESP_Diagnose 0 "ESP_nicht_in_Diagnose" 1 "ESP_in_Diagnose" ;
VAL_ 253 ESC_v_Signal_Qualifier_High_Low 0 "Gueteschwelle_kleiner_1kmh" 1 "Gueteschwelle_kleiner_3kmh" 2 "Gueteschwelle_kleiner_5kmh" 3 "Gueteschwelle_kleiner_10kmh" 4 "Gueteschwelle_kleiner_20kmh" 5 "Gueteschwelle_groessergleich_20kmh" 6 "Init" 7 "Fehler" ;
VAL_ 253 ESP_Vorsteuerung 0 "keine_Vorsteuerung_aktiv" 1 "Vorsteuerung_aktiv" ;
VAL_ 253 OBD_Schlechtweg 0 "kein_Schlechtweg_erkannt" 1 "Schlechtweg_erkannt" ;
VAL_ 253 OBD_QBit_Schlechtweg 0 "gueltiger_Wert" 1 "Ersatz_Init_oder_Fehlerwert" ;
VAL_ 253 ESP_v_Signal 65533 "Unterspannung" 65534 "Init" 65535 "Fehler" ;
VAL_ 253 ASR_Tastung_passiv 0 "ASR_aktiviert" 1 "ASR_passiv_getastet_oder_Schwellen_geaendert" ;
VAL_ 253 ESP_Tastung_passiv 0 "ESP_aktiviert" 1 "ESP_passiv_getastet_oder_Schwellen_geaendert" ;
VAL_ 253 ESP_Systemstatus 0 "iO" 1 "Fehler" ;
VAL_ 253 ASR_Schalteingriff 0 "keine_Anforderung" 1 "ASR_Schaltkennfeld" 2 "Rueckschaltung" 3 "Schaltverbot" ;
VAL_ 253 ESP_Haltebestaetigung 0 "kein_sicheres_Halten" 1 "sicheres_Halten" ;
VAL_ 253 ESP_MKB_Abbruch_Geschw 0 "MKB_nicht_beendet_wg_v_Schwelle" 1 "MKB_beendet_wg_v_Schwelle" ;
VAL_ 253 ESP_QBit_v_Signal 0 "gueltiger_Wert" 1 "Ersatz_Init_oder_Fehlerwert" ;
VAL_ 253 ABS_Bremsung 0 "keine_ABS_Regelung" 1 "ABS_Regelung_aktiv" ;
VAL_ 253 ASR_Anf 0 "keine_Anforderung" 1 "ASR_Anforderung" ;
VAL_ 253 MSR_Anf 0 "keine Anfoderung" 1 "MSR-Anforderung" ;
VAL_ 253 EBV_Eingriff 0 "kein_EBV_Eingriff" 1 "EBV_Eingriff" ;
VAL_ 253 EDS_Eingriff 0 "kein_EDS_Eingriff" 1 "EDS_Eingriff" ;
VAL_ 253 ESP_Eingriff 0 "kein_ESP_Eingriff" 1 "ESP_Eingriff_aktiv" ;
VAL_ 253 ESP_ASP 0 "inaktiv" 1 "aktiv" ;
VAL_ 795 ESP_Lampe 0 "Aus" 1 "Ein" ;
VAL_ 795 ABS_Lampe 0 "Aus" 1 "Ein" ;
VAL_ 795 BK_Lampe_02 0 "aus" 1 "ein_statisch" 3 "Warnung" ;
VAL_ 795 TC_Lampe 0 "Aus" 1 "Ein" ;
VAL_ 795 ESP_m_Raddrehz 32765 "Unterspannung" 32766 "Init" 32767 "Fehler" ;
VAL_ 795 ESP_Textanzeigen_03 0 "kein_Text" 1 "ESP_Stoerung" 2 "ABS_Stoerung" 3 "ESP_ABS_Stoerung" 4 "Werkstatt_Bremse" 5 "ASR_Stoerung" 6 "ESP_switched_off" 7 "ASR_off" 8 "ESP_ASR_on" 10 "keine_Bremskraftverstaerkung" 11 "ASR_aktiviert" 12 "ABS_ASR_Stoerung" 15 "ESP_offroad" 17 "ESP_sport" 18 "ESP_Zwangsaktivierung" 19 "ESP_Taster_Info" 20 "TC_aktiv" 21 "reserviert_fuer_Verlassenswarnung" 22 "TC_switched_off" 23 "Verlwarn_akt_Rollsicherung_inakt" ;
VAL_ 795 ESP_Meldungen 0 "keine_Anzeige" 1 "Autohold_Hinweis_1" 2 "Stoerung_Autohold" 3 "Stoerung_Hillholder" 4 "Uebernehmen" 5 "Autohold_aus" 6 "Autohold_Hinweis_2" ;
VAL_ 795 ESP_Fehlerstatus_Wegimp 0 "Wegimpulse_iO" 1 "Fehler" ;
VAL_ 795 ESP_Wegimp_Ueberlauf 0 "Reset_und_kein_Ueberlauf" 1 "mindestens_1x_Ueberlauf" ;
VAL_ 795 ESP_QBit_Wegimp_VA 0 "gueltiger_Wert" 1 "Ersatz_Init_oder_Fehlerwert" ;
VAL_ 795 ESP_HDC_FktLampe 0 "Aus" 1 "Ein" ;
VAL_ 795 ESP_Off_Lampe 0 "Lampe_aus" 1 "Lampe_ein" ;
VAL_ 795 ESP_HDC_Regelgeschw 0 "nicht_verbaut" 125 "HDC_Standby" 126 "Init" 127 "Fehler" ;
VAL_ 795 ESP_BKV_Warnung 0 "keine_Anzeige" 1 "keine_Bremskraftverstaerkung" ;
VAL_ 508 ESP_Status_Bremsentemp_02 0 "nicht_erhoeht" 1 "Schwelle_1" 2 "Schwelle_2" ;
VAL_ 508 ESP_Aggregataktivitaet 0 "inaktiv" 1 "aktiv" ;
VAL_ 508 ESP_Stillstandsflag 0 "kein_Stillstand_erkannt" 1 "Stillstand_erkannt" ;
VAL_ 508 ESC_FBA_Meldungen 0 "kein_Text" 1 "FBA_Warnung_aktiv_MT" 2 "FBA_Warnung_aktiv_AT" ;
VAL_ 508 ESP_Rollover_Status_dyn 0 "Auspraegung1" 1 "Auspraegung2" 2 "Auspraegung3" 3 "Auspraegung4" ;
VAL_ 508 ESP_Rollover_Status_stat 0 "Auspraegung1" 1 "Auspraegung2" 2 "Auspraegung3" 3 "Auspraegung4" ;
VAL_ 508 ESP_AVH_LED 0 "LED_aus" 1 "LED_ein" 2 "LED_blinken" 3 "Funktion_gesperrt__LED_aus" 6 "Init" ;
VAL_ 508 ESP_HDC_LED 0 "LED_aus" 1 "LED_ein" 2 "LED_blinken" 3 "Funktion_gesperrt__LED_aus" 6 "Init" ;
VAL_ 508 ESP_Off_LED 0 "LED_aus" 1 "LED_ein" 2 "LED_blinken" 3 "Funktion_gesperrt__LED_aus" 6 "Init" ;
VAL_ 508 ESP_Notbremsanzeige 0 "keine_Notbremsung_erkannt" 1 "Notbremsung_erkannt" ;
VAL_ 508 ESC_Motorstartverzoegerung 0 "Startfreigabe" 1 "Anforderung_Startverzoegerung" ;
VAL_ 508 ESP_Offroad_Lampe 0 "Aus" 1 "Ein" ;
VAL_ 508 ESP_HDC_Textanzeigen 0 "kein_Text" 1 "HDC_ein" 2 "HDC_aus" 3 "HDC_nicht_verfuegbar_in_FahrPr" 4 "HDC_nicht_verfuegbar_Uebertemp" 5 "HDC_verfuegbar_keine_Uebertemp" 6 "HDC_nicht_verfuegbar_ACC_aktiv" 7 "HDC_nicht_verfuegbar_GRA_aktiv" 8 "HDC_nicht_verfuegbar_LIM_aktiv" 9 "HDC_nicht_verfuegbar_IPA_aktiv" 10 "HDC_nicht_verfuegbar_PLA_aktiv" 11 "HDC_nicht_verf_anderes_Syst_akt" 12 "HDC_nicht_verfuegbar_Fehler" 13 "GRA_Hebel_einschalten" 14 "Funk_nicht_verfuegbar_bei_HDC" 15 "Funk_verfuegbar_wenn_HDC_aktiv" ;
VAL_ 427 ESC_AHW_aktiv 0 "keine_Aktivitaet" 1 "Aktivitaet_durch_IPA" 2 "Aktivitaet_durch_ARA" 3 "Aktivitaet_durch_ACC" 4 "tbd" 5 "tbd" 6 "tbd" 7 "tbd" ;
VAL_ 427 ESC_AHW_nicht_verfuegbar 0 "verfuegbar" 1 "nicht_verfuegbar" ;
VAL_ 427 ESC_ANB_CM_aktiv 0 "keine_Aktivitaet" 1 "Aktivitaet_durch_AWV" ;
VAL_ 427 ESC_ANB_CM_nicht_verfuegbar 0 "verfuegbar" 1 "nicht_verfuegbar" ;
VAL_ 427 ESC_Warnruck_aktiv 0 "keine_Aktivitaet" 1 "Aktivitaet_durch_AWV" 2 "Aktivitaet_durch_vFGS" 3 "Aktivitaet_durch_RCTA" 4 "Aktivitaet_durch_FCWO" 5 "Aktivitaet_durch_FCWP" 6 "Aktivitaet_durch_EA" ;
VAL_ 427 ESC_Warnruck_nicht_verfuegbar 0 "verfuegbar" 1 "nicht_verfuegbar" ;
VAL_ 427 ESC_Prefill_aktiv 0 "keine_Aktivitaet" 1 "Prefill_aktiv" ;
VAL_ 427 ESC_Prefill_nicht_verfuegbar 0 "verfuegbar" 1 "nicht_verfuegbar" ;
VAL_ 427 ESC_HBA_aktiv 0 "keine_Aktivitaet" 1 "HBA_aktiv" ;
VAL_ 427 ESC_HBA_nicht_verfuegbar 0 "verfuegbar" 1 "nicht_verfuegbar" ;
VAL_ 427 ESC_TSK_SRBM_Anf 0 "keine_Aktivitaet" 1 "Aktivitaet_durch_TSK" ;
VAL_ 427 ESC_TSK_SRBM_nicht_verfuegbar 0 "verfuegbar" 1 "nicht_verfuegbar" ;
VAL_ 427 ESC_Verz_Reg_aktiv 0 "keine_Aktivitaet" 1 "Aktivitaet_TB_durch_AWV" 2 "Aktivitaet_ZB_durch_AWV" 3 "Aktivitaet_durch_vFGS" 4 "Aktivitaet_durch_TSK" 5 "Aktivitaet_durch_RCTA" 6 "Aktivitaet_durch_PLA_IPA" 7 "Aktivitaet_durch_STA" 8 "Aktivitaet_durch_ARA" ;
VAL_ 427 ESC_Verz_Reg_nicht_verfuegbar 0 "verfuegbar" 1 "nicht_verfuegbar" ;
VAL_ 427 ESC_Verz_Reg_TB_nicht_verfuegbar 0 "verfuegbar" 1 "nicht_verfuegbar" ;
VAL_ 427 ESC_Verz_Reg_ZB_nicht_verfuegbar 0 "verfuegbar" 1 "nicht_verfuegbar" ;
VAL_ 427 ESC_Bremslicht_unplausibel 0 "plausibel" 1 "unplausibel" ;
VAL_ 427 ESC_Konsistenz_ACC 0 "konsistent" 1 "nicht_konsistent" ;
VAL_ 427 ESC_Konsistenz_AWV 0 "konsistent" 1 "nicht_konsistent" ;
VAL_ 427 ESC_Konsistenz_ARA 0 "konsistent" 1 "nicht_konsistent" ;
VAL_ 427 ESC_Konsistenz_IPA 0 "konsistent" 1 "nicht_konsistent" ;
VAL_ 427 ESC_Konsistenz_FCW 0 "konsistent" 1 "nicht_konsistent" ;
VAL_ 427 ESC_Konsistenz_NV 0 "konsistent" 1 "nicht_konsistent" ;
VAL_ 427 ESC_Konsistenz_RCTA 0 "konsistent" 1 "nicht_konsistent" ;
VAL_ 427 ESC_Konsistenz_TSK 0 "konsistent" 1 "nicht_konsistent" ;
VAL_ 427 ESC_Konsistenz_vFGS 0 "konsistent" 1 "nicht_konsistent" ;
VAL_ 427 ESC_Konsistenz_STA 0 "konsistent" 1 "nicht_konsistent" ;
VAL_ 427 ESC_Fahrer_Bremsdruck_bestimmend 0 "Fahrer_nicht_Bremsdruck_bestimmend" 1 "Fahrer_Bremsdruck_bestimmend" ;
VAL_ 427 ESC_Konsistenz_EA 0 "konsistent" 1 "nicht_konsistent" ;
VAL_ 427 ESC_Konsistenz_BFF 0 "konsistent" 1 "nicht_konsistent" ;
VAL_ 427 ESC_Konsistenz_MKB 0 "konsistent" 1 "nicht_konsistent" ;
VAL_ 2589283470 ESC_Kilometer 1048574 "Init" 1048575 "Fehler" ;
VAL_ 2589283470 ESC_Kilometer_MUX 0 "GFA_Signierung" 1 "IKA_Signierung" ;
VAL_ 2589283470 ESC_Signatur_Kilometer_GFA_01 0 "Init" ;
VAL_ 2589283470 ESC_Signatur_Kilometer_IKA_01 0 "Init" ;
VAL_ 2589283470 ESC_Signatur_Kilometer_GFA_02 0 "Init" ;
VAL_ 2589283470 ESC_Signatur_Kilometer_IKA_02 0 "Init" ;
VAL_ 264 FA_Hoehenwerte_kalibriert 0 "kalibrierte Höhenwerte in mm" 1 "Rohwerte" ;
VAL_ 264 FA_Hoehenwert_VL_00 254 "nicht initialisiert" 255 "Fehler" ;
VAL_ 264 FA_Hoehenwert_VR_00 254 "nicht initialisiert" 255 "Fehler" ;
VAL_ 264 FA_Hoehenwert_HL_00 254 "nicht initialisiert" 255 "Fehler" ;
VAL_ 264 FA_Hoehenwert_HR_00 254 "nicht initialisiert" 255 "Fehler" ;
VAL_ 429 NR_Reglerstatus 0 "nicht_definiert" 1 "Hochniveau_2" 2 "Hochniveau_1" 3 "Zwischenniveau" 4 "Normalniveau" 5 "Tiefniveau_1" 6 "Tiefniveau_2" 7 "Tiefniveau_3" 8 "Verladeniveau" 9 "Beladungsniveau" 10 "Heckabsenkung" ;
VAL_ 429 FA_Verstellung_in_Kuerze 0 "keine_Verstellung_erwartet" 1 "Verstellung_erwartet" ;
VAL_ 429 FA_Verstellung_aktiv 0 "keine_Verstellung" 1 "Verstellung_aktiv" ;
VAL_ 429 FA_Kompressor_laeuft_in_Kuerze 0 "kein_Kompressorlauf_erwartet" 1 "Kompressorlauf_steht_bevor" ;
VAL_ 429 FA_Kompressor_laeuft 0 "Kompressor_nicht_angesteuert" 1 "Kompressor_angesteuert" ;
VAL_ 429 NR_Anforderung_v_Begrenzung 0 "keine_Begrenzung_angefordert" 1 "Sicherheitsbegrenzung_1_aktiv" 2 "Sicherheitsbegrenzung_2_aktiv" 3 "Komfortbegrenzung_aktiv" ;
VAL_ 429 NR_LED_SGN 0 "LED_aus" 1 "LED_ein" ;
VAL_ 429 NR_LED_TN 0 "LED_aus" 1 "LED_ein" ;
VAL_ 429 NR_LED_BN 0 "LED_aus" 1 "LED_ein" ;
VAL_ 429 FA_Absenkung_Fahrzeug 0 "keine_Absenkung" 1 "Absenkung_Fahrzeug" ;
VAL_ 429 FA_Anhaengerstatus_intern 0 "Anhaenger_intern_nicht_erkannt" 1 "Anhaenger_intern_erkannt_manuell" 2 "Anhaenger_intern_erkannt_automatisch" 3 "Anhaenger_intern_erkannt_automatisch_manuelle_Deaktivierung_aktiv" 4 "Anhaenger_intern_erkannt_Failsafe" ;
VAL_ 429 FA_Anhebung_Fahrzeug 0 "keine_Anhebung" 1 "Anhebung_Fahrzeug" ;
VAL_ 429 FA_Druckspeicher_verfuegbar 0 "Druckspeicher_nicht_verfuegbar" 1 "Regelung_aus_Druckspeicher_moeglich" ;
VAL_ 429 FA_ESP_Zuschaltung 0 "keine_ESP_Beeinflussung" 1 "ESP_Zwangszuschaltung_angefordert" ;
VAL_ 429 NR_LED_HN 0 "LED_aus" 1 "LED_ein" ;
VAL_ 429 FA_Zwischenniveau 0 "kein_Zwischenniveau" 1 "Zwischenniveau" ;
VAL_ 429 FA_Systemstatus 0 "nicht_funktionsfaehig" 1 "funktionsfaehig" ;
VAL_ 429 EFP_Soll_FahrPr_HAL 0 "nicht_gesteuert" 1 "Zwang_Programm_1" 2 "Zwang_Programm_2" 3 "Zwang_Programm_3" 4 "Zwang_Programm_4" 5 "Zwang_Programm_5" 6 "Zwang_Programm_6" 7 "Zwang_Programm_7" 8 "Zwang_Programm_8" 9 "Zwang_Programm_9" 10 "Zwang_Programm_10" 11 "Zwang_Programm_11" 12 "Zwang_Programm_12" 13 "Zwang_Programm_13" 14 "Zwang_Programm_14" 15 "Zwang_Programm_15" ;
VAL_ 429 NR_Kompressor_Temp_Zylinderkopf 254 "Init" 255 "Fehler" ;
VAL_ 429 FA_Signal_Drucksensor 254 "Init" 255 "Fehler" ;
VAL_ 1605 FLA_aktiv 0 "inaktiv" 1 "aktiv" ;
VAL_ 1605 FLA_ISP_defekt 0 "iO" 1 "defekt" ;
VAL_ 1605 FLA_Sensor_blockiert 0 "Sensor in Ordnung" 1 "Sensor blockiert" ;
VAL_ 1605 FLA_Abblendursache 0 "nichts erkannt (Init-Wert) " 1 "enentgegenkommendes Fahrzeug (Scheinwerfer erkannt) " 2 "vorausfahrendes Fahrzeug (Heckleuchten erkannt) " 4 "Geschwindigkeitslimit unterschritten" 8 "Ortschaft_erkannt" 16 "Umgebungshelligkeit_generell_zu_hell" 32 "Nebel erkannt " 64 "Übertemperatur Imager" 128 "Verzögerungsbedingung" 255 "Fehler" ;
VAL_ 1605 FLA_Fernlicht_PWM 127 "Fehler" ;
VAL_ 1605 ISP_EC_Lichtwert_vorne 62 "Init" 63 "Fehler" ;
VAL_ 1605 ISP_EC_Lichtwert_hinten 62 "Init" 63 "Fehler" ;
VAL_ 1605 ISP_Himmelsrichtung 30 "nicht verfuegbar bzw. Init" 31 "Fehler" ;
VAL_ 1605 ISP_Taste_betaetigt 0 "nicht_betaetigt" 1 "betaetigt" ;
VAL_ 1605 ISP_EC_aktiv 0 "inaktiv" 1 "aktiv" ;
VAL_ 1605 ISP_Kompass_aktiv 0 "inaktiv" 1 "aktiv" ;
VAL_ 1605 FLA_Aufblenden 0 "nicht_aufblenden" 1 "aufblenden" ;
VAL_ 1605 FLA_SAE_Mode 0 "Init" 1 "FLA_Icon_invertiert" ;
VAL_ 1727 FSS_Neigung_Sitz_Pos 0 "Inaktiv" ;
VAL_ 1727 FSS_KopfstuetzeX_Pos 0 "Init" ;
VAL_ 173 GE_MMom_Soll_02 1022 "keine_Anforderung_Init" 1023 "Fehler" ;
VAL_ 173 GE_MMom_Vorhalt_02 1022 "Init" 1023 "Fehler" ;
VAL_ 173 GE_Uefkt 1023 "Fehler" ;
VAL_ 173 GE_Fahrstufe 0 "Zwischenstellung" 1 "Init" 5 "Position_P" 6 "Position_R" 7 "Position_N" 8 "Position_D" 9 "Position_S" 10 "Effizienz" 13 "Tipp_in_S" 14 "Tipp_in_D" 15 "Fehler" ;
VAL_ 173 GE_Schaltablauf 0 "keine_Schaltung" 1 "Momentenueberschneidung" 2 "Befuellphase" 3 "Drehzahlueberfuehrung" ;
VAL_ 173 GE_Uefkt_unplausibel 0 "Uefkt_plausibel" 1 "Uefkt_unplausibel" ;
VAL_ 173 GE_MMom_Status_02 0 "kein_Eingriff" 1 "abs_reduzierender_Eingriff_auf_Gesamt_Antrieb_nur_schneller_Pfad" 2 "abs_erhoehender_Eingriff_auf_Gesamt_Antrieb" 3 "relativer_Eingriff_auf_Gesamt_Antrieb" 4 "relativer_Eingriff_auf_E_Maschine" 5 "abs_red_Eingr_auf_Gesamt_Antrieb_nur_Luftpfad" 6 "abs_red_Eingr_auf_Gesamt_Antrieb_Luft-_und_schnellen_Pfad" ;
VAL_ 173 GE_Status_Kraftschluss 0 "offen_kein_Kraftschluss" 1 "offen_mit_Kraftschluss" 2 "schlupfend_geregelt" 4 "geschlossen_mit_Mikroschlupf" 5 "geschlossen_mit_Ueberanpressung" 6 "sonstige_Fehler" 7 "fehlerhaft_geschlossen" ;
VAL_ 173 GE_MMom_Status 0 "keine Anforderung" 1 "reduzierender Getriebeeingriff" 2 "erhöhender Getriebeeingriff" 3 "Änderung mit Sprung" ;
VAL_ 173 GE_Freig_MMom_Vorhalt 0 "nicht_freigegeben" 1 "freigegeben" ;
VAL_ 173 GE_Verbot_Ausblendung 0 "kein_Verbot" 1 "Verbot" ;
VAL_ 173 GE_Zielgang 0 "Gang P/N (ausgekuppelt)" 1 "Gang 1" 2 "Gang 2" 3 "Gang 3" 4 "Gang 4" 5 "Gang 5" 6 "Gang 6" 7 "Gang 7" 8 "Gang R" 11 "Gang 8" 12 "Gang 9" 14 "Istgang nicht definiert" 15 "Fehler" ;
VAL_ 968 GE_OBD_AbsperrVent 0 "kein Fehler / Init / nicht verbaut" 1 "KS- (Kurzschluss nach minus)" 2 "KS+ (Kurzschluss nach plus)" 3 "OC (Leitungsunterbrechung)" 4 "OOR+ (Signal zu gross)" 5 "OOR- (Signal zu klein)" 6 "RC+ (Signal unplausibel zu gross)" 7 "RC- (Signal unplausibel zu klein)" 8 "KS+/OC (Kurzschluss nach plus/Unterbrechung)" 9 "KS-/OC  (Kurzschluss nach minus/Unterbrechung)" 10 "KS-/KS+  (Kurzschluss nach minus/plus)" 11 "KS-/KS+/OC (Kurzschluss nach minus/plus/Unterbrechung)" 12 "frei" 13 "frei" 14 "frei" 15 "frei" ;
VAL_ 968 GE_amax_moeglich 511 "nicht_definiert" ;
VAL_ 968 GE_Charisma_FahrPr 0 "keine_Funktion" 1 "Programm_1" 2 "Programm_2" 3 "Programm_3" 4 "Programm_4" 5 "Programm_5" 6 "Programm_6" 7 "Programm_7" 8 "Programm_8" 9 "Programm_9" 10 "Programm_10" 11 "Programm_11" 12 "Programm_12" 13 "Programm_13" 14 "Programm_14" 15 "Programm_15" ;
VAL_ 968 GE_Charisma_Status 0 "Init" 1 "verfuegbar" 2 "nicht_verfuegbar" 3 "asynchron_durch_Fahrerwunsch" ;
VAL_ 968 GE_Freigabe_Verfallsinfo_WFS 0 "Aus" 1 "Ein" ;
VAL_ 968 Freilauf_Charisma_FahrPr 0 "keine_Funktion" 1 "Programm_1" 2 "Programm_2" 3 "Programm_3" 4 "Programm_4" 5 "Programm_5" 6 "Programm_6" 7 "Programm_7" 8 "Programm_8" 9 "Programm_9" 10 "Programm_10" 11 "Programm_11" 12 "Programm_12" 13 "Programm_13" 14 "Programm_14" 15 "Programm_15" ;
VAL_ 968 Freilauf_Charisma_Status 0 "Init" 1 "verfuegbar" 2 "nicht_verfuegbar" 3 "asynchron_durch_Fahrerwunsch" ;
VAL_ 968 GE_Freigabe_Info_WFS 0 "ungueltig" 1 "gueltig" ;
VAL_ 968 GE_Sperr_Info_WFS 0 "nicht_gesperrt" 1 "gesperrt" ;
VAL_ 968 GE_Zustand_Kuppltemp 0 "Init" 1 "Kupplungstemp_normal" 2 "Kupplungstemp_hoch" 3 "Kupplungsschutz_aktivieren" ;
VAL_ 968 GE_Codierung_MSG 0 "Codierung iO / Init" 1 "Codierung niO" ;
VAL_ 968 GE_LaunchControl 0 "inaktiv" 1 "aktiv" ;
VAL_ 968 GE_Heizwunsch 0 "maximaler_Waermebedarf" 1 "kein_Waermebedarf" 2 "Kuehlbedarf" 3 "Notfall_(maximaler_Kuehlbedarf)" ;
VAL_ 968 GE_OBD_Status 0 "MIL aus" 1 "MIL ein" ;
VAL_ 968 GE_LFR_Adaption 0 "fuer_Adaption_geeignet" 1 "fuer_Adaption_nicht_geeignet" ;
VAL_ 968 GE_Sumpftemperatur 255 "Fehler" ;
VAL_ 310 HAL_Status 0 "Normalbetrieb" 1 "Lenkungsausfall" 2 "Derating_aktiv" 3 "Lenkung_manuell_deaktiviert" ;
VAL_ 310 HAL_VZ_Radwinkel 0 "positiv_Lenkeinschlag_links" 1 "negativ_Lenkeinschlag_rechts" ;
VAL_ 310 HAL_QBit_Radwinkel 0 "gueltiger_Wert" 1 "Ersatz_Init_oder_Fehlerwert" ;
VAL_ 310 HAL_Radwinkel 1020 "Unterspannung" 1021 "nicht_kalibriert" 1022 "Init" 1023 "Fehler" ;
VAL_ 310 HAL_Warnungen 0 "keine_Warnung" 1 "Ausfall_rote_Warnung" 2 "Systemstoerung_gelbe_Warnung" 3 "HAL_deaktiviert" ;
VAL_ 310 HAL_VZ_Fahrerwunschwinkel_Soll 0 "positiv" 1 "negativ" ;
VAL_ 310 HAL_Fahrerwunschwinkel_Soll 1022 "Init" 1023 "Fehler" ;
VAL_ 310 HAL_max_Gradient 126 "Init" 127 "Fehler" ;
VAL_ 310 HAL_EFP_FahrPr 0 "keine_Funktion" 1 "Programm_1" 2 "Programm_2" 3 "Programm_3" 4 "Programm_4" 5 "Programm_5" 6 "Programm_6" 7 "Programm_7" 8 "Programm_8" 9 "Programm_9" 10 "Programm_10" 11 "Programm_11" 12 "Programm_12" 13 "Programm_13" 14 "Programm_14" 15 "Programm_15" ;
VAL_ 310 HAL_Charisma_Status 0 "Init" 1 "verfuegbar" 2 "nicht_verfuegbar" 3 "asynchron_durch_Fahrerwunsch" ;
VAL_ 310 HAL_Charisma_FahrPr 0 "keine_Funktion" 1 "Programm_1" 2 "Programm_2" 3 "Programm_3" 4 "Programm_4" 5 "Programm_5" 6 "Programm_6" 7 "Programm_7" 8 "Programm_8" 9 "Programm_9" 10 "Programm_10" 11 "Programm_11" 12 "Programm_12" 13 "Programm_13" 14 "Programm_14" 15 "Programm_15" ;
VAL_ 676 HAL_ARA_Status 0 "HAL_ARA_Deaktiv" 1 "HAL_ARA_Init" 2 "HAL_ARA_Fehler_mit_Eintrag" 3 "reserviert" 4 "reserviert" 5 "reserviert" 6 "HAL_ARA_Lenkwinkel_aktiv" 7 "HAL_ARA_Abgewiesen" 8 "HAL_ARA_Funktionsbereit" 9 "reserviert" 10 "HAL_ARA_Abbruch" 11 "reserviert" 12 "reserviert" 13 "reserviert" 14 "reserviert" 15 "reserviert" ;
VAL_ 676 HAL_PLA_Status 0 "HAL_PLA_Deaktiv" 1 "HAL_PLA_Init" 2 "HAL_PLA_Fehler_mit_Eintrag" 3 "reserviert" 4 "reserviert" 5 "reserviert" 6 "HAL_PLA_Lenkwinkel_aktiv" 7 "HAL_PLA_Abgewiesen" 8 "HAL_PLA_Funktionsbereit" 9 "reserviert" 10 "HAL_PLA_Abbruch" 11 "reserviert" 12 "reserviert" 13 "reserviert" 14 "reserviert" 15 "reserviert" ;
VAL_ 676 HAL_PWR_Abbruch 0 "Init/Invalid" 1 "PWR beendet durch HAL-SG wegen vFzg" 2 "PWR beendet durch HAL-SG wegen HM" 3 "Radwinkeldifferenz zu groß" 4 "Gradient der Zielanforderung zu groß" 5 "reserviert" 6 "reserviert" 7 "reserviert" 8 "Falscher PLA-Status" 9 "Falscher ARA-Status" 10 "reserviert" 11 "reserviert" 12 "reserviert" 13 "reserviert" 14 "reserviert" 15 "reserviert" ;
VAL_ 676 HAL_PWR_Fehler 0 "Init/Invalid" 1 "Verfügbarkeit zu gering" 2 "reserviert" 3 "Rotorwinkel nicht initialisiert" 4 "BCM1/Rückfahrlicht veraltet" 5 "reserviert" 6 "reserviert" 7 "Fehler ESP(vFzg)" 8 "Fehler ESP(Raddrehzahlen)" 9 "reserviert" 10 "reserviert" 11 "reserviert" 12 "reserviert" 13 "reserviert" 14 "HAL_ARA_Satus == 6" 15 "HAL_PLA_Satus == 6" ;
VAL_ 1410 HD_Endstellung_oben 1 "HD in Endstellung oben (offen)" ;
VAL_ 1410 HD_Endstellung_unten 1 "HD in Endstellung unten (geschlossen)" ;
VAL_ 1410 HD_Bewegung_auf 1 "HD in Bewegung auf" ;
VAL_ 1410 HD_Bewegung_zu 1 "HD in Bewegung zu" ;
VAL_ 1410 HD_Innentaster_betaetigt 0 "HD_Innentaster_nicht_betaetigt" 1 "HD_Innentaster_betaetigt" ;
VAL_ 1410 HD_UeKB_erkannt 1 "Einklemmschutz aktiv" ;
VAL_ 1410 HD_Taster_defekt 0 "Taster_funktionsfähig" 1 "Taster defekt" ;
VAL_ 1410 HD_Rueckmeld_prog 0 "keine Rueckmeldung" 1 "Rueckmeldung zur Programmierung Endstellung aktiv" ;
VAL_ 1410 HD_Verriegelungstaster_betaetigt 0 "Taster_nicht_betaetigt" 1 "Taster_betaetigt" ;
VAL_ 1410 HD_Verr_Taster_betaetigt_inv 0 "Taster_betaetigt" 1 "Taster_nicht_betaetigt" ;
VAL_ 1410 HD_ZZH_Schalter_S3 0 "nicht_betaetigt" 1 "betaetigt" ;
VAL_ 1416 FSH_LED 0 "Aus" 1 "Ein" ;
VAL_ 1416 HSH_LED 0 "Aus" 1 "Ein" ;
VAL_ 1416 SIH_Stufe_LED_li 0 "Aus" 2 "Stufe_2" 4 "Stufe_4" 6 "Stufe_6" ;
VAL_ 1416 SIH_Stufe_LED_re 0 "Aus" 2 "Stufe_2" 4 "Stufe_4" 6 "Stufe_6" ;
VAL_ 1416 SIL_Stufe_LED_li 0 "Aus" 2 "Stufe_2" 4 "Stufe_4" 6 "Stufe_6" ;
VAL_ 1416 SIL_Stufe_LED_re 0 "Aus" 2 "Stufe_2" 4 "Stufe_4" 6 "Stufe_6" ;
VAL_ 1416 KRH_Stufe_LED_li 0 "Aus" 1 "Stufe_1" 2 "Stufe_2" 3 "Stufe_3" ;
VAL_ 1416 KRH_Stufe_LED_re 0 "Aus" 1 "Stufe_1" 2 "Stufe_2" 3 "Stufe_3" ;
VAL_ 1416 BCM1_TCH_HLR_Anf 0 "keine_Anforderung" 1 "Anforderung" ;
VAL_ 1416 HLR_SIH_Freigabe_Fond 0 "keine_Freigabe" 1 "Freigabe" ;
VAL_ 1016 HLR_FlHz_Freigabe_Ruhesitz 0 "0_Prozent" 1 "33_Prozent" 2 "66_Prozent" 3 "100_Prozent" ;
VAL_ 1016 HLR_FlHz_Freigabe_VR 0 "0_Prozent" 1 "33_Prozent" 2 "66_Prozent" 3 "100_Prozent" ;
VAL_ 1016 HLR_FlHz_Freigabe_VL 0 "0_Prozent" 1 "33_Prozent" 2 "66_Prozent" 3 "100_Prozent" ;
VAL_ 1016 HLR_FlHz_Freigabe_HR 0 "0_Prozent" 1 "33_Prozent" 2 "66_Prozent" 3 "100_Prozent" ;
VAL_ 1016 HLR_FlHz_Freigabe_HL 0 "0_Prozent" 1 "33_Prozent" 2 "66_Prozent" 3 "100_Prozent" ;
VAL_ 1016 HLR_TCH_Freigabe 0 "keine_Freigabe" 1 "Freigabe" ;
VAL_ 1016 HLR_SIH_Freigabe_Fond 0 "keine_Freigabe" 1 "Freigabe" ;
VAL_ 1016 HLR_Sp_Heizung_Freigabe_BT 0 "keine_Freigabe" 1 "Freigabe" ;
VAL_ 1016 HLR_Sp_Heizung_Freigabe_FT 0 "keine_Freigabe" 1 "Freigabe" ;
VAL_ 1016 HLR_KRH_Freigabe_VL 0 "0_Prozent" 1 "33_Prozent" 2 "66_Prozent" 3 "100_Prozent" ;
VAL_ 1016 HLR_KRH_Freigabe_VR 0 "0_Prozent" 1 "33_Prozent" 2 "66_Prozent" 3 "100_Prozent" ;
VAL_ 1016 HLR_SIH_Freigabe_VL 0 "0_Prozent" 1 "33_Prozent" 2 "66_Prozent" 3 "100_Prozent" ;
VAL_ 1016 HLR_SIH_Freigabe_VR 0 "0_Prozent" 1 "33_Prozent" 2 "66_Prozent" 3 "100_Prozent" ;
VAL_ 1016 HLR_SIH_Freigabe_HL 0 "0_Prozent" 1 "33_Prozent" 2 "66_Prozent" 3 "100_Prozent" ;
VAL_ 1016 HLR_SIH_Freigabe_HR 0 "0_Prozent" 1 "33_Prozent" 2 "66_Prozent" 3 "100_Prozent" ;
VAL_ 1016 HLR_SIL_Freigabe_VL 0 "0_Prozent" 1 "33_Prozent" 2 "66_Prozent" 3 "100_Prozent" ;
VAL_ 1016 HLR_SIL_Freigabe_VR 0 "0_Prozent" 1 "33_Prozent" 2 "66_Prozent" 3 "100_Prozent" ;
VAL_ 1016 HLR_SIL_Freigabe_HL 0 "0_Prozent" 1 "33_Prozent" 2 "66_Prozent" 3 "100_Prozent" ;
VAL_ 1016 HLR_SIL_Freigabe_HR 0 "0_Prozent" 1 "33_Prozent" 2 "66_Prozent" 3 "100_Prozent" ;
VAL_ 1016 HLR_FSH_Freigabe 0 "AUS" 63 "Fehler" ;
VAL_ 1016 HLR_HSH_Freigabe 0 "keine_Freigabe" 1 "Freigabe" ;
VAL_ 1016 HLR_LRH_Freigabe 0 "keine_Freigabe" 1 "Freigabe" ;
VAL_ 1016 HLR_PTC_linear_Freigabe 63 "Fehler" ;
VAL_ 1016 HLR_PTC_Freigabe 0 "Aus" 1 "Stufe_1" 2 "Stufe_2" 3 "Stufe_3" ;
VAL_ 1412 HSP_Taster 0 "nicht_betaetigt" 1 "betaetigt" ;
VAL_ 1412 HSP_Status_LED 0 "LED_nicht_angesteuert" 1 "LED_angesteuert" ;
VAL_ 1412 HSP_Warnung_LED 0 "Aus" 1 "Ein" ;
VAL_ 1412 HSP_Warnung_Ton 0 "Aus" 1 "Ein" ;
VAL_ 1412 HSP_Warnung_Text 0 "Aus" 1 "Ein" ;
VAL_ 1412 HSP_Endlage_eingefahren 0 "Endlage nicht erreicht" 1 "Endlage erreicht" ;
VAL_ 1412 HSP_Endlage_ausgefahren 0 "Endlage nicht erreicht" 1 "Endlage erreicht" ;
VAL_ 1412 HSP_Unterspannung 0 "normal" 1 "Fehler" ;
VAL_ 1412 HSP_Ueberspannung 0 "normal" 1 "Fehler" ;
VAL_ 1412 HSP_Lokalaktiv 0 "war_nicht_lokal_aktiv" 1 "war_lokal_aktiv" ;
VAL_ 1412 HSP_ResponseError 0 "normal" 1 "Fehler" ;
VAL_ 1412 HSP_ErrorGueltigkeit_1 0 "Fehler_passiv__Fehlerpfad_nicht_durchlaufen" 1 "Fehler_gueltig__Fehlerpfad_durchlaufen" ;
VAL_ 1412 HSP_ErrorGueltigkeit_2 0 "Fehler_passiv__Fehlerpfad_nicht_durchlaufen" 1 "Fehler_gueltig__Fehlerpfad_durchlaufen" ;
VAL_ 1412 HSP_def 0 "normal" 1 "Fehler" ;
VAL_ 1412 HSP_Motor_def 0 "normal" 1 "Fehler" ;
VAL_ 1412 HSP_Spoiler_Error 0 "iO" 1 "Fehler__Endlage_nicht_erreicht" ;
VAL_ 1412 HSP_Taster_Error 0 "Taster_iO" 1 "Fehler__haengender_Taster" ;
VAL_ 1412 HSP_LED_Error 0 "normal" 1 "Fehler" ;
VAL_ 1412 HSP_Spielschutz 0 "inaktiv" 1 "aktiv" ;
VAL_ 1412 HSP_Charisma_FahrPr 0 "keine_Funktion" 1 "Programm_1" 2 "Programm_2" 3 "Programm_3" 4 "Programm_4" 5 "Programm_5" 6 "Programm_6" 7 "Programm_7" 8 "Programm_8" 9 "Programm_9" 10 "Programm_10" 11 "Programm_11" 12 "Programm_12" 13 "Programm_13" 14 "Programm_14" 15 "Programm_15" ;
VAL_ 1412 HSP_Charisma_Status 0 "Init" 1 "verfuegbar" 2 "nicht_verfuegbar" 3 "asynchron_durch_Fahrerwunsch" ;
VAL_ 1283 HVK_Istmodus_Anf 0 "nicht_angefordert" 1 "angefordert" ;
VAL_ 1283 HVK_MO_EmSollzustand 0 "HvOff" 1 "HvStbyReq" 2 "HvStbyWait" 3 "HvBattOnReq" 4 "HvBattOnWait" 10 "HvOnIdle" 18 "HvOnDrvReq" 19 "HvOnDrvWait" 20 "HvOnDrvRdy" 28 "HvStepUpReq" 29 "HvStepUpWait" 30 "HvStepUp" 38 "HvStepDownReq" 39 "HvStepDownWait" 40 "HvStepDown" 46 "HvAcChPreReq" 47 "HvAcChPreWait" 48 "HvAcChReq" 49 "HvAcChWait" 50 "HvAcCh" 56 "HvDcChPreReq" 57 "HvDcChPreWait" 58 "HvDcChReq" 59 "HvDcChWait" 60 "HvDcCh" 67 "HvChOffReq" 68 "HvChOffWait" 69 "HvOnIdleReq" 70 "HvOnIdleWait" 96 "HvCpntOffReq" 97 "HvCpntOffWait" 98 "HvBattOffReq" 99 "HvBattOffWait" 109 "HvDcDcFailOffReq" 110 "HvDcDcFail" 119 "HvElmOffReq" 120 "HvElmOff" 126 "HvFailCpntOffReq" 127 "HvFailCpntOffWait" 128 "HvFailBattOffReq" 129 "HvFailBattOffWait" 130 "HvFailBattOff" 138 "HvFailUCtlReq" 139 "HvFailUCtlWait" 140 "HvFailUCtl" 150 "HvEmgcyOff" 255 "Init" ;
VAL_ 1283 HVK_BMS_Sollmodus 0 "HV_Off" 1 "HV_On" 4 "AC_Laden" 6 "DC_Laden" 7 "Init" ;
VAL_ 1283 HVK_DCDC_Sollmodus 0 "Standby" 1 "HV_On" 2 "Tiefsetzen" 3 "Hochsetzen" 7 "Initialisierung" ;
VAL_ 1283 HVK_EKK_Sollmodus 0 "Keine_Freigabe" 1 "Freigabe" 7 "Init" ;
VAL_ 1283 HVK_HVPTC_Sollmodus 0 "Keine_Freigabe" 1 "Freigabe" 7 "Init" ;
VAL_ 1283 HVK_HVLM_Sollmodus 0 "keine_Freigabe" 1 "Freigabe_Lademanager" 7 "Init" ;
VAL_ 1283 HVK_HV_Netz_Warnungen 0 "Keine_Warnung" 1 "Warntext_HV_Netz_Anf" 2 "Fehlertext_HV_Netz_Anf" 3 "Warnung_Kein_Wiederstart_moeglich" ;
VAL_ 1283 HV_Bordnetz_aktiv 0 "inaktiv" 1 "aktiv" ;
VAL_ 1283 HV_Bordnetz_Fehler 0 "kein_Fehler" 1 "Fehler" ;
VAL_ 1283 HVK_Gesamtst_Spgfreiheit 0 "Funktion_Init__ohne_Funktion" 1 "HV_System_spannungsfrei" 2 "HV_System_nicht_spannungsfrei" 3 "Fehler" ;
VAL_ 1283 HVK_AktiveEntladung_Anf 0 "nicht_angefordert" 1 "angefordert" ;
